VERSION "ConnectivityCANFD"

NS_ :

BS_ :

BU_ :  ETC IHU TCAM

BO_ 880 DhuConnCANFDFr07 : 64 IHU
 SG_ BookChrgnTarValFb : 7|10@0+ (0.1,0.0) [0.0|100.0] "%" TCAM
 SG_ BookChrgnTarValFb_UB : 13|1@0+ (1,0) [0|1] "" TCAM
 SG_ BookTrvlHeatgStsFb : 23|3@0+ (1,0) [0|7] "" TCAM
 SG_ BookTrvlHeatgStsFb_UB : 20|1@0+ (1,0) [0|1] "" TCAM
 SG_ BookTrvlPreHeatgFb : 9|2@0+ (1,0) [0|3] "" TCAM
 SG_ BookTrvlPreHeatgFb_UB : 10|1@0+ (1,0) [0|1] "" TCAM
 SG_ CarLoctrActvnSts : 31|2@0+ (1,0) [0|3] "" TCAM
 SG_ CarLoctrActvnSts_UB : 29|1@0+ (1,0) [0|1] "" TCAM
 SG_ CdsParkgClimaActv : 12|1@0+ (1,0) [0|1] "" TCAM
 SG_ CdsParkgClimaActv_UB : 11|1@0+ (1,0) [0|1] "" TCAM
 SG_ ClimaOvrHeatProActv : 19|1@0+ (1,0) [0|1] "" TCAM
 SG_ ClimaOvrHeatProActv_UB : 18|1@0+ (1,0) [0|1] "" TCAM
 SG_ ClimaOvrHeatProActvSts : 17|1@0+ (1,0) [0|1] "" TCAM
 SG_ ClimaOvrHeatProActvSts_UB : 16|1@0+ (1,0) [0|1] "" TCAM
 SG_ CmptmtRelHum : 47|8@0+ (0.5,0.0) [0.0|100.0] "%" TCAM
 SG_ CmptmtRelHum_UB : 55|1@0+ (1,0) [0|1] "" TCAM
 SG_ DchaChrgnTarValFb : 25|10@0+ (0.1,0.0) [0.0|100.0] "%" TCAM
 SG_ DchaChrgnTarValFb_UB : 26|1@0+ (1,0) [0|1] "" TCAM
 SG_ DigKeyLogUploadSwt : 88|1@0+ (1,0) [0|1] "" TCAM
 SG_ DigKeyLogUploadSwt_UB : 56|1@0+ (1,0) [0|1] "" TCAM
 SG_ DrvrSeatHeatgAvlSts : 51|3@0+ (1,0) [0|7] "" TCAM
 SG_ DrvrSeatHeatgAvlSts_UB : 48|1@0+ (1,0) [0|1] "" TCAM
 SG_ DrvrSeatHeatgLvlSts : 53|2@0+ (1,0) [0|3] "" TCAM
 SG_ DrvrSeatHeatgLvlSts_UB : 54|1@0+ (1,0) [0|1] "" TCAM
 SG_ DrvrSeatVentAvlSts : 63|3@0+ (1,0) [0|7] "" TCAM
 SG_ DrvrSeatVentAvlSts_UB : 60|1@0+ (1,0) [0|1] "" TCAM
 SG_ DrvrSeatVentnLvlSts : 59|2@0+ (1,0) [0|3] "" TCAM
 SG_ DrvrSeatVentnLvlSts_UB : 57|1@0+ (1,0) [0|1] "" TCAM
 SG_ EngN2 : 71|15@0+ (0.5,0.0) [0.0|16383.5] "rpm" TCAM
 SG_ EngN2_UB : 72|1@0+ (1,0) [0|1] "" TCAM
 SG_ FragCh1Id : 87|8@0+ (1.0,0.0) [0.0|255.0] "Unitless" TCAM
 SG_ FragCh1Id_UB : 95|1@0+ (1,0) [0|1] "" TCAM
 SG_ FragCh1UseUpWrn : 90|1@0+ (1,0) [0|1] "" TCAM
 SG_ FragCh1UseUpWrn_UB : 89|1@0+ (1,0) [0|1] "" TCAM
 SG_ FragCh2Id : 103|8@0+ (1.0,0.0) [0.0|255.0] "Unitless" TCAM
 SG_ FragCh2Id_UB : 94|1@0+ (1,0) [0|1] "" TCAM
 SG_ FragCh2UseUpWrn : 135|1@0+ (1,0) [0|1] "" TCAM
 SG_ FragCh2UseUpWrn_UB : 134|1@0+ (1,0) [0|1] "" TCAM
 SG_ FragCh3Id : 111|8@0+ (1.0,0.0) [0.0|255.0] "Unitless" TCAM
 SG_ FragCh3Id_UB : 93|1@0+ (1,0) [0|1] "" TCAM
 SG_ FragCh3UseUpWrn : 133|1@0+ (1,0) [0|1] "" TCAM
 SG_ FragCh3UseUpWrn_UB : 132|1@0+ (1,0) [0|1] "" TCAM
 SG_ FragCh4Id : 119|8@0+ (1.0,0.0) [0.0|255.0] "Unitless" TCAM
 SG_ FragCh4Id_UB : 92|1@0+ (1,0) [0|1] "" TCAM
 SG_ FragCh4UseUpWrn : 131|1@0+ (1,0) [0|1] "" TCAM
 SG_ FragCh4UseUpWrn_UB : 130|1@0+ (1,0) [0|1] "" TCAM
 SG_ FragCh5Id : 127|8@0+ (1.0,0.0) [0.0|255.0] "Unitless" TCAM
 SG_ FragCh5Id_UB : 91|1@0+ (1,0) [0|1] "" TCAM
 SG_ FragCh5UseUpWrn : 129|1@0+ (1,0) [0|1] "" TCAM
 SG_ FragCh5UseUpWrn_UB : 128|1@0+ (1,0) [0|1] "" TCAM
 SG_ FragLvlFrmClima : 143|2@0+ (1,0) [0|3] "" TCAM
 SG_ FragLvlFrmClima_UB : 151|1@0+ (1,0) [0|1] "" TCAM
 SG_ FragStsFrmClima : 141|2@0+ (1,0) [0|3] "" TCAM
 SG_ FragStsFrmClima_UB : 150|1@0+ (1,0) [0|1] "" TCAM
 SG_ HmiCarLocatorSetReq : 307|1@0+ (1,0) [0|1] "" TCAM
 SG_ HmiCarLocatorSetReq_UB : 306|1@0+ (1,0) [0|1] "" TCAM
 SG_ HvCellTDifFlt : 139|2@0+ (1,0) [0|3] "" TCAM
 SG_ HvCellTDifFlt_UB : 149|1@0+ (1,0) [0|1] "" TCAM
 SG_ HvCellUDifFlt : 137|2@0+ (1,0) [0|3] "" TCAM
 SG_ HvCellUDifFlt_UB : 148|1@0+ (1,0) [0|1] "" TCAM
 SG_ HvCellUOverFlt : 159|2@0+ (1,0) [0|3] "" TCAM
 SG_ HvCellUOverFlt_UB : 147|1@0+ (1,0) [0|1] "" TCAM
 SG_ HvCellUUnderFlt : 157|2@0+ (1,0) [0|3] "" TCAM
 SG_ HvCellUUnderFlt_UB : 146|1@0+ (1,0) [0|1] "" TCAM
 SG_ HvilFlt : 144|1@0+ (1,0) [0|1] "" TCAM
 SG_ HvilFlt_UB : 145|1@0+ (1,0) [0|1] "" TCAM
 SG_ HvIsoFlt : 167|2@0+ (1,0) [0|3] "" TCAM
 SG_ HvIsoFlt_UB : 175|1@0+ (1,0) [0|1] "" TCAM
 SG_ HvPackOverChrgFlt : 165|2@0+ (1,0) [0|3] "" TCAM
 SG_ HvPackOverChrgFlt_UB : 174|1@0+ (1,0) [0|1] "" TCAM
 SG_ HvPackUOverFlt : 163|2@0+ (1,0) [0|3] "" TCAM
 SG_ HvPackUOverFlt_UB : 173|1@0+ (1,0) [0|1] "" TCAM
 SG_ HvPackUUnderFlt : 161|2@0+ (1,0) [0|3] "" TCAM
 SG_ HvPackUUnderFlt_UB : 172|1@0+ (1,0) [0|1] "" TCAM
 SG_ HvSocHiFlt : 183|2@0+ (1,0) [0|3] "" TCAM
 SG_ HvSocHiFlt_UB : 171|1@0+ (1,0) [0|1] "" TCAM
 SG_ HvSocHopFlt : 181|2@0+ (1,0) [0|3] "" TCAM
 SG_ HvSocHopFlt_UB : 170|1@0+ (1,0) [0|1] "" TCAM
 SG_ HvSocLoFlt : 179|2@0+ (1,0) [0|3] "" TCAM
 SG_ HvSocLoFlt_UB : 169|1@0+ (1,0) [0|1] "" TCAM
 SG_ IntPm25StsFrmClima : 177|2@0+ (1,0) [0|3] "" TCAM
 SG_ IntPm25StsFrmClima_UB : 168|1@0+ (1,0) [0|1] "" TCAM
 SG_ KeyIntrVldDetd : 154|1@0+ (1,0) [0|1] "" TCAM
 SG_ KeyIntrVldDetd_UB : 155|1@0+ (1,0) [0|1] "" TCAM
 SG_ LiBattInPWLockTC : 298|1@0+ (1,0) [0|1] "" TCAM
 SG_ LiBattInPWLockTC_UB : 297|1@0+ (1,0) [0|1] "" TCAM
 SG_ OutdPm25LvlFrmClima : 207|3@0+ (1,0) [0|7] "" TCAM
 SG_ OutdPm25LvlFrmClima_UB : 204|1@0+ (1,0) [0|1] "" TCAM
 SG_ OutdPm25VluFrmClima : 191|10@0+ (1.0,0.0) [0.0|1023.0] "Unitless" TCAM
 SG_ OutdPm25VluFrmClima_UB : 197|1@0+ (1,0) [0|1] "" TCAM
 SG_ PassSeatHeatgAvlSts : 203|3@0+ (1,0) [0|7] "" TCAM
 SG_ PassSeatHeatgAvlSts_UB : 200|1@0+ (1,0) [0|1] "" TCAM
 SG_ PassSeatHeatgLvlSts : 215|2@0+ (1,0) [0|3] "" TCAM
 SG_ PassSeatHeatgLvlSts_UB : 223|1@0+ (1,0) [0|1] "" TCAM
 SG_ PassSeatVentAvlSts : 211|3@0+ (1,0) [0|7] "" TCAM
 SG_ PassSeatVentAvlSts_UB : 208|1@0+ (1,0) [0|1] "" TCAM
 SG_ PassSeatVentnLvlSts : 213|2@0+ (1,0) [0|3] "" TCAM
 SG_ PassSeatVentnLvlSts_UB : 222|1@0+ (1,0) [0|1] "" TCAM
 SG_ PrkgClimaWarn : 195|4@0+ (1,0) [0|15] "" TCAM
 SG_ PrkgClimaWarn_UB : 196|1@0+ (1,0) [0|1] "" TCAM
 SG_ RelHumSnsrRelHum : 231|8@0+ (0.5,0.0) [0.0|100.0] "%" TCAM
 SG_ RelHumSnsrRelHum_UB : 221|1@0+ (1,0) [0|1] "" TCAM
 SG_ RemClimaActv : 239|1@0+ (1,0) [0|1] "" TCAM
 SG_ RemClimaActv_UB : 238|1@0+ (1,0) [0|1] "" TCAM
 SG_ RemClimaDefrstSts : 237|1@0+ (1,0) [0|1] "" TCAM
 SG_ RemClimaDefrstSts_UB : 236|1@0+ (1,0) [0|1] "" TCAM
 SG_ RemClimaDelaySts : 235|1@0+ (1,0) [0|1] "" TCAM
 SG_ RemClimaDelaySts_UB : 234|1@0+ (1,0) [0|1] "" TCAM
 SG_ RemClimaExtnTiRspn : 233|1@0+ (1,0) [0|1] "" TCAM
 SG_ RemClimaExtnTiRspn_UB : 232|1@0+ (1,0) [0|1] "" TCAM
 SG_ RemClimaHvRspn : 247|1@0+ (1,0) [0|1] "" TCAM
 SG_ RemClimaHvRspn_UB : 246|1@0+ (1,0) [0|1] "" TCAM
 SG_ RemClimaHvSts : 245|1@0+ (1,0) [0|1] "" TCAM
 SG_ RemClimaHvSts_UB : 244|1@0+ (1,0) [0|1] "" TCAM
 SG_ RemClimaWarn : 219|4@0+ (1,0) [0|15] "" TCAM
 SG_ RemClimaWarn_UB : 220|1@0+ (1,0) [0|1] "" TCAM
 SG_ RemStrtClimaRspn : 251|1@0+ (1,0) [0|1] "" TCAM
 SG_ RemStrtClimaRspn_UB : 250|1@0+ (1,0) [0|1] "" TCAM
 SG_ RemVentActvSts : 243|1@0+ (1,0) [0|1] "" TCAM
 SG_ RemVentActvSts_UB : 242|1@0+ (1,0) [0|1] "" TCAM
 SG_ RemVentReqRspnFb : 241|1@0+ (1,0) [0|1] "" TCAM
 SG_ RemVentReqRspnFb_UB : 240|1@0+ (1,0) [0|1] "" TCAM
 SG_ RemVentWarnSts : 255|2@0+ (1,0) [0|3] "" TCAM
 SG_ RemVentWarnSts_UB : 253|1@0+ (1,0) [0|1] "" TCAM
 SG_ SteerWhlHeatgAvlSts : 271|3@0+ (1,0) [0|7] "" TCAM
 SG_ SteerWhlHeatgAvlSts_UB : 268|1@0+ (1,0) [0|1] "" TCAM
 SG_ SunCurtImpctDetnSts2 : 263|3@0+ (1,0) [0|7] "" TCAM
 SG_ SunCurtImpctDetnSts2_UB : 249|1@0+ (1,0) [0|1] "" TCAM
 SG_ SunCurtMvngSts : 311|1@0+ (1,0) [0|1] "" Vector__XXX
 SG_ SunCurtMvngSts_UB : 310|1@0+ (1,0) [0|1] "" Vector__XXX
 SG_ SunCurtPosnSts : 260|5@0+ (1,0) [0|31] "" TCAM
 SG_ SunCurtPosnSts_UB : 248|1@0+ (1,0) [0|1] "" TCAM
 SG_ SunRoofAndCurtFailr_UB : 252|1@0+ (1,0) [0|1] "" TCAM
 SG_ SunRoofAndCurtFailrCurtMotFailr : 279|1@0+ (1,0) [0|1] "" TCAM
 SG_ SunRoofAndCurtFailrCurtMotHallFailr : 278|1@0+ (1,0) [0|1] "" TCAM
 SG_ SunRoofAndCurtFailrCurtMotNotAvl : 277|1@0+ (1,0) [0|1] "" TCAM
 SG_ SunRoofAndCurtFailrEcuFailrGen : 276|1@0+ (1,0) [0|1] "" TCAM
 SG_ SunRoofAndCurtFailrPanMotFailr : 275|1@0+ (1,0) [0|1] "" TCAM
 SG_ SunRoofAndCurtFailrPanMotHallFailr : 274|1@0+ (1,0) [0|1] "" TCAM
 SG_ SunRoofAndCurtFailrPanMotNotAvl : 273|1@0+ (1,0) [0|1] "" TCAM
 SG_ SunRoofAndCurtFailrResvd : 272|1@0+ (1,0) [0|1] "" TCAM
 SG_ SunRoofMvngSts : 309|1@0+ (1,0) [0|1] "" Vector__XXX
 SG_ SunRoofMvngSts_UB : 308|1@0+ (1,0) [0|1] "" Vector__XXX
 SG_ TankFlapSts : 301|2@0+ (1,0) [0|3] "" TCAM
 SG_ TankFlapSts_UB : 299|1@0+ (1,0) [0|1] "" TCAM
 SG_ WhlMotSysInvrT : 287|8@0+ (1.0,-50.0) [-50.0|200.0] "degC" TCAM
 SG_ WhlMotSysInvrT_UB : 303|1@0+ (1,0) [0|1] "" TCAM
 SG_ WhlMotSysMotT : 295|8@0+ (1.0,-50.0) [-50.0|200.0] "degC" TCAM
 SG_ WhlMotSysMotT_UB : 302|1@0+ (1,0) [0|1] "" TCAM
 SG_ WinFailrStsAtPass : 267|1@0+ (1,0) [0|1] "" TCAM
 SG_ WinFailrStsAtPass_UB : 266|1@0+ (1,0) [0|1] "" TCAM
 SG_ WinFailrStsAtReRi : 265|1@0+ (1,0) [0|1] "" TCAM
 SG_ WinFailrStsAtReRi_UB : 264|1@0+ (1,0) [0|1] "" TCAM

BO_ 672 DhuConnCANFDFr08 : 64 IHU
 SG_ ClimaOvrHeatProRspn : 4|1@0+ (1,0) [0|1] "" TCAM
 SG_ ClimaOvrHeatProRspn_UB : 3|1@0+ (1,0) [0|1] "" TCAM
 SG_ ClimaOvrHeatProWarn : 7|2@0+ (1,0) [0|3] "" TCAM
 SG_ ClimaOvrHeatProWarn_UB : 5|1@0+ (1,0) [0|1] "" TCAM
 SG_ ClsdDueToRain : 15|1@0+ (1,0) [0|1] "" TCAM
 SG_ ClsdDueToRain_UB : 14|1@0+ (1,0) [0|1] "" TCAM
 SG_ SchedCmptHeatCoolFB : 2|2@0+ (1,0) [0|3] "" TCAM
 SG_ SchedCmptHeatCoolFB_UB : 0|1@0+ (1,0) [0|1] "" TCAM
 SG_ VehCfgPrm_UB : 13|1@0+ (1,0) [0|1] "" TCAM
 SG_ VehCfgPrmBlkIDBytePosn1 : 23|8@0+ (1.0,0.0) [0.0|255.0] "Unitless" TCAM
 SG_ VehCfgPrmCCPBytePosn2 : 31|8@0+ (1.0,0.0) [0.0|255.0] "Unitless" TCAM
 SG_ VehCfgPrmCCPBytePosn3 : 39|8@0+ (1.0,0.0) [0.0|255.0] "Unitless" TCAM
 SG_ VehCfgPrmCCPBytePosn4 : 47|8@0+ (1.0,0.0) [0.0|255.0] "Unitless" TCAM
 SG_ VehCfgPrmCCPBytePosn5 : 55|8@0+ (1.0,0.0) [0.0|255.0] "Unitless" TCAM
 SG_ VehCfgPrmCCPBytePosn6 : 63|8@0+ (1.0,0.0) [0.0|255.0] "Unitless" TCAM
 SG_ VehCfgPrmCCPBytePosn7 : 71|8@0+ (1.0,0.0) [0.0|255.0] "Unitless" TCAM
 SG_ VehCfgPrmCCPBytePosn8 : 79|8@0+ (1.0,0.0) [0.0|255.0] "Unitless" TCAM
 SG_ VehCfgPrmExt_UB : 12|1@0+ (1,0) [0|1] "" TCAM
 SG_ VehCfgPrmExtBlkIDBytePosn1 : 87|8@0+ (1.0,0.0) [0.0|255.0] "Unitless" TCAM
 SG_ VehCfgPrmExtCCPBytePosn2 : 95|8@0+ (1.0,0.0) [0.0|255.0] "Unitless" TCAM
 SG_ VehCfgPrmExtCCPBytePosn3 : 103|8@0+ (1.0,0.0) [0.0|255.0] "Unitless" TCAM
 SG_ VehCfgPrmExtCCPBytePosn4 : 111|8@0+ (1.0,0.0) [0.0|255.0] "Unitless" TCAM
 SG_ VehCfgPrmExtCCPBytePosn5 : 119|8@0+ (1.0,0.0) [0.0|255.0] "Unitless" TCAM
 SG_ VehCfgPrmExtCCPBytePosn6 : 127|8@0+ (1.0,0.0) [0.0|255.0] "Unitless" TCAM
 SG_ VehCfgPrmExtCCPBytePosn7 : 135|8@0+ (1.0,0.0) [0.0|255.0] "Unitless" TCAM
 SG_ VehCfgPrmExtCCPBytePosn8 : 143|8@0+ (1.0,0.0) [0.0|255.0] "Unitless" TCAM
 SG_ Vin_UB : 11|1@0+ (1,0) [0|1] "" TCAM
 SG_ VinBlockNr : 151|8@0+ (1.0,0.0) [0.0|255.0] "Unitless" TCAM
 SG_ VinVINSignalPos1 : 159|8@0+ (1.0,0.0) [0.0|255.0] "Unitless" TCAM
 SG_ VinVINSignalPos2 : 167|8@0+ (1.0,0.0) [0.0|255.0] "Unitless" TCAM
 SG_ VinVINSignalPos3 : 175|8@0+ (1.0,0.0) [0.0|255.0] "Unitless" TCAM
 SG_ VinVINSignalPos4 : 183|8@0+ (1.0,0.0) [0.0|255.0] "Unitless" TCAM
 SG_ VinVINSignalPos5 : 191|8@0+ (1.0,0.0) [0.0|255.0] "Unitless" TCAM
 SG_ VinVINSignalPos6 : 199|8@0+ (1.0,0.0) [0.0|255.0] "Unitless" TCAM
 SG_ VinVINSignalPos7 : 207|8@0+ (1.0,0.0) [0.0|255.0] "Unitless" TCAM

BO_ 1008 DhuConnCANFDFr09 : 64 IHU
 SG_ LocalBookChrgnTarVal : 15|10@0+ (0.1,0.0) [0.0|100.0] "%" TCAM
 SG_ LocalBookChrgnTarVal_UB : 21|1@0+ (1,0) [0|1] "" TCAM
 SG_ MaxAcInpCurrentSet : 7|8@0+ (1.0,0.0) [0.0|255.0] "Unitless" TCAM
 SG_ MaxAcInpCurrentSet_UB : 20|1@0+ (1,0) [0|1] "" TCAM

BO_ 48 DhuConnCANFDFr10 : 64 IHU
 SG_ CarTiGlb : 7|32@0+ (0.1,0.0) [0.0|429496729.5] "s" TCAM
 SG_ CarTiGlb_UB : 39|1@0+ (1,0) [0|1] "" TCAM
 SG_ DoorDrvrLockSts : 47|2@0+ (1,0) [0|3] "" TCAM
 SG_ DoorDrvrLockSts_UB : 38|1@0+ (1,0) [0|1] "" TCAM
 SG_ DoorDrvrSts : 117|2@0+ (1,0) [0|3] "" TCAM
 SG_ DoorDrvrSts_UB : 115|1@0+ (1,0) [0|1] "" TCAM
 SG_ DoorLeReLockSts : 45|2@0+ (1,0) [0|3] "" TCAM
 SG_ DoorLeReLockSts_UB : 37|1@0+ (1,0) [0|1] "" TCAM
 SG_ DoorLeReSts : 113|2@0+ (1,0) [0|3] "" TCAM
 SG_ DoorLeReSts_UB : 114|1@0+ (1,0) [0|1] "" TCAM
 SG_ DoorPassLockSts : 43|2@0+ (1,0) [0|3] "" TCAM
 SG_ DoorPassLockSts_UB : 36|1@0+ (1,0) [0|1] "" TCAM
 SG_ DoorPassSts : 127|2@0+ (1,0) [0|3] "" TCAM
 SG_ DoorPassSts_UB : 125|1@0+ (1,0) [0|1] "" TCAM
 SG_ DoorRiReLockSts : 41|2@0+ (1,0) [0|3] "" TCAM
 SG_ DoorRiReLockSts_UB : 35|1@0+ (1,0) [0|1] "" TCAM
 SG_ DoorRiReSts : 123|2@0+ (1,0) [0|3] "" TCAM
 SG_ DoorRiReSts_UB : 124|1@0+ (1,0) [0|1] "" TCAM
 SG_ LockgCenSts_UB : 48|1@0+ (1,0) [0|1] "" TCAM
 SG_ LockgCenStsLockSt : 51|2@0+ (1,0) [0|3] "" TCAM
 SG_ LockgCenStsTrigSrc : 55|4@0+ (1,0) [0|15] "" TCAM
 SG_ LockgCenStsUpdEve : 49|1@0+ (1,0) [0|1] "" TCAM
 SG_ RecOfImpct_UB : 89|1@0+ (1,0) [0|1] "" TCAM
 SG_ RecOfImpct2_UB : 118|1@0+ (1,0) [0|1] "" TCAM
 SG_ RecOfImpct2ImpctDvxSigned : 88|9@0+ (1.0,-255.0) [-255.0|257.0] "Km/h" TCAM
 SG_ RecOfImpct2ImpctDvySigned : 111|9@0+ (1.0,-255.0) [-255.0|257.0] "Km/h" TCAM
 SG_ RecOfImpctCrashFrnt : 72|1@0+ (1,0) [0|1] "" TCAM
 SG_ RecOfImpctCrashOffroadA : 90|1@0+ (1,0) [0|1] "" TCAM
 SG_ RecOfImpctCrashOffroadD : 91|1@0+ (1,0) [0|1] "" TCAM
 SG_ RecOfImpctCrashOffroadRT : 92|1@0+ (1,0) [0|1] "" TCAM
 SG_ RecOfImpctCrashOffroadRTsevere : 93|1@0+ (1,0) [0|1] "" TCAM
 SG_ RecOfImpctCrashPed : 94|1@0+ (1,0) [0|1] "" TCAM
 SG_ RecOfImpctCrashRe : 95|1@0+ (1,0) [0|1] "" TCAM
 SG_ RecOfImpctCrashRollovr : 80|1@0+ (1,0) [0|1] "" TCAM
 SG_ RecOfImpctCrashSideLe : 81|1@0+ (1,0) [0|1] "" TCAM
 SG_ RecOfImpctCrashSideRi : 82|1@0+ (1,0) [0|1] "" TCAM
 SG_ RecOfImpctCrashState : 84|2@0+ (1,0) [0|3] "" TCAM
 SG_ RecOfImpctImpctDvx : 63|8@0+ (1.0,0.0) [0.0|255.0] "Km/h" TCAM
 SG_ RecOfImpctImpctDvy : 71|8@0+ (1.0,0.0) [0.0|255.0] "Km/h" TCAM
 SG_ RecOfImpctImpctRollAg : 79|7@0+ (15.0,0.0) [0.0|1905.0] "Deg" TCAM
 SG_ RecOfImpctVehOri : 87|3@0+ (1,0) [0|7] "" TCAM
 SG_ TrLockSts : 33|2@0+ (1,0) [0|3] "" TCAM
 SG_ TrLockSts_UB : 34|1@0+ (1,0) [0|1] "" TCAM
 SG_ TrSts : 121|2@0+ (1,0) [0|3] "" TCAM
 SG_ TrSts_UB : 135|1@0+ (1,0) [0|1] "" TCAM

BO_ 944 DhuConnCANFDFr11 : 64 IHU
 SG_ AccrPedlPsd_UB : 9|1@0+ (1,0) [0|1] "" TCAM
 SG_ AccrPedlPsdAccrPedlPsd : 11|1@0+ (1,0) [0|1] "" TCAM
 SG_ AccrPedlPsdChks : 7|8@0+ (1.0,0.0) [0.0|255.0] "Unitless" TCAM
 SG_ AccrPedlPsdCntr : 15|4@0+ (1.0,0.0) [0.0|15.0] "Unitless" TCAM
 SG_ AccrPedlPsdSts : 10|1@0+ (1,0) [0|1] "" TCAM
 SG_ AjarChrgLidRearSwitch : 45|2@0+ (1,0) [0|3] "" TCAM
 SG_ AjarChrgLidRearSwitch_UB : 43|1@0+ (1,0) [0|1] "" TCAM
 SG_ DCChrgSt : 63|4@0+ (1,0) [0|15] "" TCAM
 SG_ DCChrgSt_UB : 59|1@0+ (1,0) [0|1] "" TCAM
 SG_ EscWarnIndcnReq_UB : 25|1@0+ (1,0) [0|1] "" TCAM
 SG_ EscWarnIndcnReqChks : 23|8@0+ (1.0,0.0) [0.0|255.0] "Unitless" TCAM
 SG_ EscWarnIndcnReqCntr : 31|4@0+ (1.0,0.0) [0.0|15.0] "Unitless" TCAM
 SG_ EscWarnIndcnReqEscWarnIndcnReq : 27|2@0+ (1,0) [0|3] "" TCAM
 SG_ GearIndcnRec_UB : 24|1@0+ (1,0) [0|1] "" TCAM
 SG_ GearIndcnRecGearIndcn : 39|4@0+ (1,0) [0|15] "" TCAM
 SG_ GearIndcnRecGearShiftIndcn : 47|2@0+ (1,0) [0|3] "" TCAM
 SG_ GearIndcnRecGearTarIndcn : 35|4@0+ (1,0) [0|15] "" TCAM
 SG_ HvBattChrgnTiEstimd : 42|11@0+ (1.0,0.0) [0.0|2047.0] "Mins" TCAM
 SG_ HvBattChrgnTiEstimd_UB : 8|1@0+ (1,0) [0|1] "" TCAM
 SG_ HvIsoR : 71|16@0+ (1.0,0.0) [0.0|60000.0] "kOhm" TCAM
 SG_ HvIsoR_UB : 58|1@0+ (1,0) [0|1] "" TCAM
 SG_ IemGeneric_UB : 151|1@0+ (1,0) [0|1] "" TCAM
 SG_ IemGenericADAlrmSt : 127|2@0+ (1,0) [0|3] "" TCAM
 SG_ IemGenericDTCHig : 87|8@0+ (1.0,0.0) [0.0|255.0] "Unitless" TCAM
 SG_ IemGenericDTCLow : 95|8@0+ (1.0,0.0) [0.0|255.0] "Unitless" TCAM
 SG_ IemGenericDTCMid : 103|8@0+ (1.0,0.0) [0.0|255.0] "Unitless" TCAM
 SG_ IemGenericDTCSts : 111|8@0+ (1.0,0.0) [0.0|255.0] "Unitless" TCAM
 SG_ IemGenericEMQnty : 119|4@0+ (1.0,0.0) [0.0|15.0] "Unitless" TCAM
 SG_ IemGenericEMSeqNr : 115|4@0+ (1.0,0.0) [0.0|15.0] "Unitless" TCAM
 SG_ IemGenericFltAlrmSt : 125|2@0+ (1,0) [0|3] "" TCAM
 SG_ IemGenericIacAlrmSt : 123|2@0+ (1,0) [0|3] "" TCAM
 SG_ IemGenericInvrtTAlrmSt : 121|2@0+ (1,0) [0|3] "" TCAM
 SG_ IemGenericModStatusRms : 135|4@0+ (1,0) [0|15] "" TCAM
 SG_ IemGenericMotTAlrmSt : 131|2@0+ (1,0) [0|3] "" TCAM
 SG_ IemGenericRslAlrmSt : 129|2@0+ (1,0) [0|3] "" TCAM
 SG_ IemGenericSpdAlrmSt : 143|2@0+ (1,0) [0|3] "" TCAM
 SG_ IemGenericTypeInfo : 139|4@0+ (1.0,0.0) [0.0|15.0] "Unitless" TCAM
 SG_ IemGenericUDcAlrmSt : 141|2@0+ (1,0) [0|3] "" TCAM
 SG_ IntPm25LvlFrmClima : 150|3@0+ (1,0) [0|7] "" TCAM
 SG_ IntPm25LvlFrmClima_UB : 147|1@0+ (1,0) [0|1] "" TCAM
 SG_ IntPm25VluFrmClima : 145|10@0+ (1.0,0.0) [0.0|1023.0] "Unitless" TCAM
 SG_ IntPm25VluFrmClima_UB : 146|1@0+ (1,0) [0|1] "" TCAM
 SG_ OnBdChrgrHndlSts1 : 199|4@0+ (1,0) [0|15] "" TCAM
 SG_ OnBdChrgrHndlSts1_UB : 191|1@0+ (1,0) [0|1] "" TCAM
 SG_ OnBdChrgrIAct : 167|12@0+ (0.1,-200.0) [-200.0|200.0] "A" TCAM
 SG_ OnBdChrgrIAct_UB : 171|1@0+ (1,0) [0|1] "" TCAM
 SG_ OnBdChrgrPwrEnaAllwd : 189|1@0+ (1,0) [0|1] "" TCAM
 SG_ OnBdChrgrPwrEnaAllwd_UB : 188|1@0+ (1,0) [0|1] "" TCAM
 SG_ OnBdChrgrSt : 195|4@0+ (1,0) [0|15] "" TCAM
 SG_ OnBdChrgrSt_UB : 190|1@0+ (1,0) [0|1] "" TCAM
 SG_ OnBdChrgrUAct : 170|11@0+ (0.25,0.0) [0.0|511.0] "Volt" TCAM
 SG_ OnBdChrgrUAct_UB : 185|1@0+ (1,0) [0|1] "" TCAM
 SG_ RemAllowStrt : 57|1@0+ (1,0) [0|1] "" TCAM
 SG_ RemAllowStrt_UB : 56|1@0+ (1,0) [0|1] "" TCAM
 SG_ WirelschrgActvReqFromHmi : 187|1@0+ (1,0) [0|1] "" TCAM
 SG_ WirelschrgActvReqFromHmi_UB : 186|1@0+ (1,0) [0|1] "" TCAM

BO_ 832 DhuConnCANFDFr12 : 64 IHU
 SG_ BookChargeSetResponse : 7|2@0+ (1,0) [0|3] "" TCAM
 SG_ BookChargeSetResponse_UB : 5|1@0+ (1,0) [0|1] "" TCAM
 SG_ BrkAndAbsWarnIndcnReq_UB : 111|1@0+ (1,0) [0|1] "" TCAM
 SG_ BrkAndAbsWarnIndcnReqAbsWarnIndcnReq : 109|2@0+ (1,0) [0|3] "" TCAM
 SG_ BrkAndAbsWarnIndcnReqBrkWarnIndcnReq : 110|1@0+ (1,0) [0|1] "" TCAM
 SG_ BrkAndAbsWarnIndcnReqChks : 119|8@0+ (1.0,0.0) [0.0|255.0] "Unitless" TCAM
 SG_ BrkAndAbsWarnIndcnReqCntr : 107|4@0+ (1.0,0.0) [0.0|15.0] "Unitless" TCAM
 SG_ DispOfPrpsnMod : 3|4@0+ (1,0) [0|15] "" TCAM
 SG_ DispOfPrpsnMod_UB : 4|1@0+ (1,0) [0|1] "" TCAM
 SG_ EngForbidRespFromVMM : 47|1@0+ (1,0) [0|1] "" TCAM
 SG_ EngForbidRespFromVMM_UB : 46|1@0+ (1,0) [0|1] "" TCAM
 SG_ NetDHUActvt : 63|8@0+ (1.0,0.0) [0.0|255.0] "Unitless" TCAM
 SG_ NetDHUActvt_UB : 42|1@0+ (1,0) [0|1] "" TCAM
 SG_ NotifForEmgyCall : 45|1@0+ (1,0) [0|1] "" TCAM
 SG_ NotifForEmgyCall_UB : 44|1@0+ (1,0) [0|1] "" TCAM
 SG_ PassSeatSnsrSts2 : 71|2@0+ (1,0) [0|3] "" TCAM
 SG_ PassSeatSnsrSts2_UB : 41|1@0+ (1,0) [0|1] "" TCAM
 SG_ PassSeatSts2 : 69|2@0+ (1,0) [0|3] "" TCAM
 SG_ PassSeatSts2_UB : 40|1@0+ (1,0) [0|1] "" TCAM
 SG_ TCSDoorNoClsSts : 103|1@0+ (1,0) [0|1] "" TCAM
 SG_ TCSDoorNoClsSts_UB : 102|1@0+ (1,0) [0|1] "" TCAM
 SG_ TrOpenerByFootOperCmd : 67|1@0+ (1,0) [0|1] "" TCAM
 SG_ TrOpenerByFootOperCmd_UB : 66|1@0+ (1,0) [0|1] "" TCAM
 SG_ TrsmParkLockd_UB : 14|1@0+ (1,0) [0|1] "" TCAM
 SG_ TrsmParkLockdChks : 23|8@0+ (1.0,0.0) [0.0|255.0] "Unitless" TCAM
 SG_ TrsmParkLockdCntr : 11|4@0+ (1.0,0.0) [0.0|15.0] "Unitless" TCAM
 SG_ TrsmParkLockdTrsmParkLockd : 13|2@0+ (1,0) [0|3] "" TCAM
 SG_ VehMtnSt_UB : 31|1@0+ (1,0) [0|1] "" TCAM
 SG_ VehMtnStChks : 39|8@0+ (1.0,0.0) [0.0|255.0] "Unitless" TCAM
 SG_ VehMtnStCntr : 30|4@0+ (1.0,0.0) [0.0|15.0] "Unitless" TCAM
 SG_ VehMtnStVehMtnSt : 26|3@0+ (1,0) [0|7] "" TCAM
 SG_ WirelsChrgFrntLeSwt : 101|1@0+ (1,0) [0|1] "" TCAM
 SG_ WirelsChrgFrntLeSwt_UB : 100|1@0+ (1,0) [0|1] "" TCAM
 SG_ WirelsChrgFrntRiSwt : 99|1@0+ (1,0) [0|1] "" TCAM
 SG_ WirelsChrgFrntRiSwt_UB : 98|1@0+ (1,0) [0|1] "" TCAM

BO_ 272 DhuConnCANFDFr13 : 64 IHU
 SG_ ClimaActv : 17|1@0+ (1,0) [0|1] "" TCAM
 SG_ ClimaActv_UB : 16|1@0+ (1,0) [0|1] "" TCAM
 SG_ HoodSts : 25|2@0+ (1,0) [0|3] "" TCAM
 SG_ HoodSts_UB : 33|1@0+ (1,0) [0|1] "" TCAM
 SG_ SunRoofPosnSts : 15|5@0+ (1,0) [0|31] "" TCAM
 SG_ SunRoofPosnSts_UB : 10|1@0+ (1,0) [0|1] "" TCAM
 SG_ WinPosnStsAtDrvr : 23|5@0+ (1,0) [0|31] "" TCAM
 SG_ WinPosnStsAtDrvr_UB : 18|1@0+ (1,0) [0|1] "" TCAM
 SG_ WinPosnStsAtPass : 31|5@0+ (1,0) [0|31] "" TCAM
 SG_ WinPosnStsAtPass_UB : 26|1@0+ (1,0) [0|1] "" TCAM
 SG_ WinPosnStsAtReLe : 39|5@0+ (1,0) [0|31] "" TCAM
 SG_ WinPosnStsAtReLe_UB : 34|1@0+ (1,0) [0|1] "" TCAM
 SG_ WinPosnStsAtReRi : 47|5@0+ (1,0) [0|31] "" TCAM
 SG_ WinPosnStsAtReRi_UB : 42|1@0+ (1,0) [0|1] "" TCAM

BO_ 800 DhuConnCANFDFr14 : 64 IHU
 SG_ ChrgnByEngStsDurgDcha : 42|3@0+ (1,0) [0|7] "" TCAM
 SG_ ChrgnByEngStsDurgDcha_UB : 43|1@0+ (1,0) [0|1] "" TCAM
 SG_ ChrgnWarn : 9|1@0+ (1,0) [0|1] "" TCAM
 SG_ ChrgnWarn_UB : 8|1@0+ (1,0) [0|1] "" TCAM
 SG_ EgyRegenEgyAct : 7|13@0+ (20.0,0.0) [0.0|163820.0] "Wh" TCAM
 SG_ EgyRegenEgyAct_UB : 10|1@0+ (1,0) [0|1] "" TCAM
 SG_ EngFltIndcn_UB : 44|1@0+ (1,0) [0|1] "" TCAM
 SG_ EngFltIndcn1 : 23|1@0+ (1,0) [0|1] "" TCAM
 SG_ EngFltIndcn10 : 30|1@0+ (1,0) [0|1] "" TCAM
 SG_ EngFltIndcn11 : 29|1@0+ (1,0) [0|1] "" TCAM
 SG_ EngFltIndcn12 : 28|1@0+ (1,0) [0|1] "" TCAM
 SG_ EngFltIndcn13 : 27|1@0+ (1,0) [0|1] "" TCAM
 SG_ EngFltIndcn14 : 26|1@0+ (1,0) [0|1] "" TCAM
 SG_ EngFltIndcn15 : 25|1@0+ (1,0) [0|1] "" TCAM
 SG_ EngFltIndcn16 : 24|1@0+ (1,0) [0|1] "" TCAM
 SG_ EngFltIndcn17 : 39|1@0+ (1,0) [0|1] "" TCAM
 SG_ EngFltIndcn18 : 38|1@0+ (1,0) [0|1] "" TCAM
 SG_ EngFltIndcn19 : 37|1@0+ (1,0) [0|1] "" TCAM
 SG_ EngFltIndcn2 : 22|1@0+ (1,0) [0|1] "" TCAM
 SG_ EngFltIndcn20 : 36|1@0+ (1,0) [0|1] "" TCAM
 SG_ EngFltIndcn21 : 35|1@0+ (1,0) [0|1] "" TCAM
 SG_ EngFltIndcn22 : 34|1@0+ (1,0) [0|1] "" TCAM
 SG_ EngFltIndcn23 : 33|1@0+ (1,0) [0|1] "" TCAM
 SG_ EngFltIndcn24 : 32|1@0+ (1,0) [0|1] "" TCAM
 SG_ EngFltIndcn25 : 47|1@0+ (1,0) [0|1] "" TCAM
 SG_ EngFltIndcn26 : 46|1@0+ (1,0) [0|1] "" TCAM
 SG_ EngFltIndcn27 : 45|1@0+ (1,0) [0|1] "" TCAM
 SG_ EngFltIndcn3 : 21|1@0+ (1,0) [0|1] "" TCAM
 SG_ EngFltIndcn4 : 20|1@0+ (1,0) [0|1] "" TCAM
 SG_ EngFltIndcn5 : 19|1@0+ (1,0) [0|1] "" TCAM
 SG_ EngFltIndcn6 : 18|1@0+ (1,0) [0|1] "" TCAM
 SG_ EngFltIndcn7 : 17|1@0+ (1,0) [0|1] "" TCAM
 SG_ EngFltIndcn8 : 16|1@0+ (1,0) [0|1] "" TCAM
 SG_ EngFltIndcn9 : 31|1@0+ (1,0) [0|1] "" TCAM
 SG_ EngOilLvlSts : 135|3@0+ (1,0) [0|7] "" TCAM
 SG_ EngOilLvlSts_UB : 132|1@0+ (1,0) [0|1] "" TCAM
 SG_ EngOilPWarn : 131|1@0+ (1,0) [0|1] "" TCAM
 SG_ EngOilPWarn_UB : 130|1@0+ (1,0) [0|1] "" TCAM
 SG_ IgmGeneric_UB : 119|1@0+ (1,0) [0|1] "" TCAM
 SG_ IgmGenericADAlrmSt : 103|2@0+ (1,0) [0|3] "" TCAM
 SG_ IgmGenericDTCHig : 55|8@0+ (1.0,0.0) [0.0|255.0] "Unitless" TCAM
 SG_ IgmGenericDTCLow : 63|8@0+ (1.0,0.0) [0.0|255.0] "Unitless" TCAM
 SG_ IgmGenericDTCMid : 71|8@0+ (1.0,0.0) [0.0|255.0] "Unitless" TCAM
 SG_ IgmGenericDTCSts : 79|8@0+ (1.0,0.0) [0.0|255.0] "Unitless" TCAM
 SG_ IgmGenericEMQnty : 87|4@0+ (1.0,0.0) [0.0|15.0] "Unitless" TCAM
 SG_ IgmGenericEMSeqNr : 83|4@0+ (1.0,0.0) [0.0|15.0] "Unitless" TCAM
 SG_ IgmGenericFltAlrmSt : 101|2@0+ (1,0) [0|3] "" TCAM
 SG_ IgmGenericIacAlrmSt : 99|2@0+ (1,0) [0|3] "" TCAM
 SG_ IgmGenericInvrtTAlrmSt : 97|2@0+ (1,0) [0|3] "" TCAM
 SG_ IgmGenericModStatusRms : 95|4@0+ (1,0) [0|15] "" TCAM
 SG_ IgmGenericMotTAlrmSt : 111|2@0+ (1,0) [0|3] "" TCAM
 SG_ IgmGenericRslAlrmSt : 109|2@0+ (1,0) [0|3] "" TCAM
 SG_ IgmGenericSpdAlrmSt : 107|2@0+ (1,0) [0|3] "" TCAM
 SG_ IgmGenericTypeInfo : 91|4@0+ (1.0,0.0) [0.0|15.0] "Unitless" TCAM
 SG_ IgmGenericUDcAlrmSt : 105|2@0+ (1,0) [0|3] "" TCAM
 SG_ IsgIDc : 117|14@0+ (0.1,-818.8) [-818.8|819.2] "A" TCAM
 SG_ IsgIDc_UB : 118|1@0+ (1,0) [0|1] "" TCAM
 SG_ IsgInvrT : 143|8@0+ (1.0,-50.0) [-50.0|200.0] "degC" TCAM
 SG_ IsgInvrT_UB : 129|1@0+ (1,0) [0|1] "" TCAM
 SG_ IsgMotT : 151|8@0+ (1.0,-50.0) [-50.0|200.0] "degC" TCAM
 SG_ IsgMotT_UB : 128|1@0+ (1,0) [0|1] "" TCAM
 SG_ IsgSpdActSgn : 159|15@0- (1.0,0.0) [-16384.0|16383.0] "rpm" TCAM
 SG_ IsgSpdActSgn_UB : 160|1@0+ (1,0) [0|1] "" TCAM
 SG_ LockgCenStsForUsrFb : 175|3@0+ (1,0) [0|7] "" TCAM
 SG_ LockgCenStsForUsrFb_UB : 172|1@0+ (1,0) [0|1] "" TCAM
 SG_ OilMntnAlrmSt : 183|4@0+ (1,0) [0|15] "" TCAM
 SG_ OilMntnAlrmSt_UB : 179|1@0+ (1,0) [0|1] "" TCAM
 SG_ PrpsnModElecDrvBlkd : 171|3@0+ (1,0) [0|7] "" TCAM
 SG_ PrpsnModElecDrvBlkd_UB : 168|1@0+ (1,0) [0|1] "" TCAM

BO_ 968 DhuConnCANFDFr15 : 64 IHU
 SG_ DstTrvldHiResl : 47|8@0+ (1.0,0.0) [0.0|255.0] "m" TCAM
 SG_ DstTrvldHiResl_UB : 29|1@0+ (1,0) [0|1] "" TCAM
 SG_ DstTrvldMst2 : 7|25@0+ (1.0,0.0) [0.0|20000000.0] "Unitless" TCAM
 SG_ DstTrvldMst2_UB : 30|1@0+ (1,0) [0|1] "" TCAM
 SG_ EngHrToSrv : 26|11@0+ (1.0,0.0) [0.0|2000.0] "hours" TCAM
 SG_ EngHrToSrv_UB : 27|1@0+ (1,0) [0|1] "" TCAM
 SG_ EngOilLvl : 55|8@0+ (0.5,0.0) [0.0|120.0] "%" TCAM
 SG_ EngOilLvl_UB : 28|1@0+ (1,0) [0|1] "" TCAM
 SG_ EngT_UB : 69|1@0+ (1,0) [0|1] "" TCAM
 SG_ EngTEngT : 63|8@0+ (1.0,-50.0) [-50.0|200.0] "degC" TCAM
 SG_ EngTQf : 71|2@0+ (1,0) [0|3] "" TCAM
 SG_ EpbSts_UB : 68|1@0+ (1,0) [0|1] "" TCAM
 SG_ EpbStsChks : 79|8@0+ (1.0,0.0) [0.0|255.0] "Unitless" TCAM
 SG_ EpbStsCntr : 87|4@0+ (1.0,0.0) [0.0|15.0] "Unitless" TCAM
 SG_ EpbStsEpbSts : 83|4@0+ (1,0) [0|15] "" TCAM
 SG_ FuCnsAvgIndcd_UB : 127|1@0+ (1,0) [0|1] "" TCAM
 SG_ FuCnsAvgIndcdFuCnsIndcdUnit : 95|3@0+ (1,0) [0|7] "" TCAM
 SG_ FuCnsAvgIndcdFuCnsIndcdVal : 92|13@0+ (0.1,0.0) [0.0|819.1] "Unitless" TCAM
 SG_ FuCnsIndcd_UB : 126|1@0+ (1,0) [0|1] "" TCAM
 SG_ FuCnsIndcdUnit : 111|3@0+ (1,0) [0|7] "" TCAM
 SG_ FuCnsIndcdVal : 108|13@0+ (0.1,0.0) [0.0|819.1] "Unitless" TCAM
 SG_ FuLvlIndcd_UB : 124|1@0+ (1,0) [0|1] "" TCAM
 SG_ FuLvlIndcdFuLvlValFromFuTbl : 121|10@0+ (0.2,0.0) [0.0|204.60000000000002] "Litre" TCAM
 SG_ FuLvlIndcdGenQF : 123|2@0+ (1,0) [0|3] "" TCAM
 SG_ FuLvlLoIndcn : 67|1@0+ (1,0) [0|1] "" TCAM
 SG_ FuLvlLoIndcn_UB : 66|1@0+ (1,0) [0|1] "" TCAM
 SG_ FuLvlLoWarn : 65|1@0+ (1,0) [0|1] "" TCAM
 SG_ FuLvlLoWarn_UB : 64|1@0+ (1,0) [0|1] "" TCAM
 SG_ GidInfoInp1_UB : 223|1@0+ (1,0) [0|1] "" TCAM
 SG_ GidInfoInp1Byte0 : 159|8@0+ (1.0,0.0) [0.0|255.0] "Unitless" TCAM
 SG_ GidInfoInp1Byte1 : 167|8@0+ (1.0,0.0) [0.0|255.0] "Unitless" TCAM
 SG_ GidInfoInp1Byte2 : 175|8@0+ (1.0,0.0) [0.0|255.0] "Unitless" TCAM
 SG_ GidInfoInp1Byte3 : 183|8@0+ (1.0,0.0) [0.0|255.0] "Unitless" TCAM
 SG_ GidInfoInp1Byte4 : 191|8@0+ (1.0,0.0) [0.0|255.0] "Unitless" TCAM
 SG_ GidInfoInp1Byte5 : 199|8@0+ (1.0,0.0) [0.0|255.0] "Unitless" TCAM
 SG_ GidInfoInp1Byte6 : 207|8@0+ (1.0,0.0) [0.0|255.0] "Unitless" TCAM
 SG_ GidInfoInp1Byte7 : 215|8@0+ (1.0,0.0) [0.0|255.0] "Unitless" TCAM
 SG_ GidInfoInp2_UB : 222|1@0+ (1,0) [0|1] "" TCAM
 SG_ GidInfoInp2Byte0 : 231|8@0+ (1.0,0.0) [0.0|255.0] "Unitless" TCAM
 SG_ GidInfoInp2Byte1 : 239|8@0+ (1.0,0.0) [0.0|255.0] "Unitless" TCAM
 SG_ GidInfoInp2Byte2 : 247|8@0+ (1.0,0.0) [0.0|255.0] "Unitless" TCAM
 SG_ GidInfoInp2Byte3 : 255|8@0+ (1.0,0.0) [0.0|255.0] "Unitless" TCAM
 SG_ GidInfoInp2Byte4 : 263|8@0+ (1.0,0.0) [0.0|255.0] "Unitless" TCAM
 SG_ GidInfoInp2Byte5 : 271|8@0+ (1.0,0.0) [0.0|255.0] "Unitless" TCAM
 SG_ GidInfoInp2Byte6 : 279|8@0+ (1.0,0.0) [0.0|255.0] "Unitless" TCAM
 SG_ GidInfoInp2Byte7 : 287|8@0+ (1.0,0.0) [0.0|255.0] "Unitless" TCAM
 SG_ HvBattLimnIndcn : 143|16@0+ (1.0,0.0) [0.0|65535.0] "Unitless" TCAM
 SG_ HvBattLimnIndcn_UB : 125|1@0+ (1,0) [0|1] "" TCAM
 SG_ HvBattSoc : 295|11@0+ (0.05,0.0) [0.0|100.0] "%" TCAM
 SG_ HvBattSoc_UB : 300|1@0+ (1,0) [0|1] "" TCAM
 SG_ HvBattUDc : 298|11@0+ (0.25,0.0) [0.0|511.0] "Volt" TCAM
 SG_ HvBattUDc_UB : 299|1@0+ (1,0) [0|1] "" TCAM
 SG_ HybErrIndcnReq_UB : 220|1@0+ (1,0) [0|1] "" TCAM
 SG_ HybErrIndcnReqTelltlBattTracCutOff : 219|1@0+ (1,0) [0|1] "" TCAM
 SG_ HybErrIndcnReqTelltlBattTracFailr : 218|1@0+ (1,0) [0|1] "" TCAM
 SG_ HybErrIndcnReqTelltlElecDrvFailr : 217|1@0+ (1,0) [0|1] "" TCAM
 SG_ HybErrIndcnReqTelltlSysHybFailr : 216|1@0+ (1,0) [0|1] "" TCAM
 SG_ IndcnUnit_UB : 331|1@0+ (1,0) [0|1] "" TCAM
 SG_ IndcnUnitClkFmt : 319|2@0+ (1,0) [0|3] "" TCAM
 SG_ IndcnUnitDateFmt : 317|2@0+ (1,0) [0|3] "" TCAM
 SG_ IndcnUnitDstLong : 315|2@0+ (1,0) [0|3] "" TCAM
 SG_ IndcnUnitDstSho : 313|2@0+ (1,0) [0|3] "" TCAM
 SG_ IndcnUnitFuCnsUnit : 327|3@0+ (1,0) [0|7] "" TCAM
 SG_ IndcnUnitPUnit : 324|3@0+ (1,0) [0|7] "" TCAM
 SG_ IndcnUnitSpdUnit : 321|2@0+ (1,0) [0|3] "" TCAM
 SG_ IndcnUnitTUnit : 335|2@0+ (1,0) [0|3] "" TCAM
 SG_ IndcnUnitVolUnit : 333|2@0+ (1,0) [0|3] "" TCAM
 SG_ IsgTqAct_UB : 330|1@0+ (1,0) [0|1] "" TCAM
 SG_ IsgTqActChks : 359|8@0+ (1.0,0.0) [0.0|255.0] "Unitless" TCAM
 SG_ IsgTqActCntr : 367|4@0+ (1.0,0.0) [0.0|15.0] "Unitless" TCAM
 SG_ IsgTqActIsgTqAct : 343|14@0+ (1.0,-8188.0) [-8188.0|8192.0] "NewtonMeter" TCAM
 SG_ IsgTqActQualityFactor : 345|2@0+ (1,0) [0|3] "" TCAM
 SG_ IsgUDc : 362|11@0+ (0.25,0.0) [0.0|511.0] "Volt" TCAM
 SG_ IsgUDc_UB : 363|1@0+ (1,0) [0|1] "" TCAM
 SG_ LimnIndcnDcDc : 383|16@0+ (1.0,0.0) [0.0|65535.0] "Unitless" TCAM
 SG_ LimnIndcnDcDc_UB : 221|1@0+ (1,0) [0|1] "" TCAM
 SG_ PwrCnsAvgIndcd_UB : 329|1@0+ (1,0) [0|1] "" TCAM
 SG_ PwrCnsAvgIndcd1_UB : 427|1@0+ (1,0) [0|1] "" TCAM
 SG_ PwrCnsAvgIndcd1EcoDrvInfo1 : 423|11@0+ (0.1,-102.3) [-102.3|102.30000000000003] "Unitless" TCAM
 SG_ PwrCnsAvgIndcd1PwrCnsUnit : 428|1@0+ (1,0) [0|1] "" TCAM
 SG_ PwrCnsAvgIndcdEcoDrvInfo1 : 399|11@0+ (0.1,-102.3) [-102.3|102.30000000000003] "Unitless" TCAM
 SG_ PwrCnsAvgIndcdPwrCnsUnit : 404|1@0+ (1,0) [0|1] "" TCAM
 SG_ PwrCnsIndcd_UB : 328|1@0+ (1,0) [0|1] "" TCAM
 SG_ PwrCnsIndcdCnsUnit : 403|1@0+ (1,0) [0|1] "" TCAM
 SG_ PwrCnsIndcdPwrCnsIn : 402|11@0+ (0.1,-100.0) [-100.0|100.0] "Unitless" TCAM
 SG_ SrvTrig : 443|4@0+ (1.0,0.0) [0.0|15.0] "Unitless" TCAM
 SG_ SrvTrig_UB : 444|1@0+ (1,0) [0|1] "" TCAM
 SG_ VehBattU_UB : 445|1@0+ (1,0) [0|1] "" TCAM
 SG_ VehBattUSysU : 439|8@0+ (0.1,0.0) [0.0|25.0] "Volt" TCAM
 SG_ VehBattUSysUQf : 447|2@0+ (1,0) [0|3] "" TCAM
 SG_ VehSpdAvgIndcd_UB : 460|1@0+ (1,0) [0|1] "" TCAM
 SG_ VehSpdAvgIndcdVehSpdIndcd : 455|9@0+ (1.0,0.0) [0.0|511.0] "Unitless" TCAM
 SG_ VehSpdAvgIndcdVeSpdIndcdUnit : 462|2@0+ (1,0) [0|3] "" TCAM
 SG_ VehSpdIndcd_UB : 459|1@0+ (1,0) [0|1] "" TCAM
 SG_ VehSpdIndcdQly : 425|2@0+ (1,0) [0|3] "" TCAM
 SG_ VehSpdIndcdQly_UB : 426|1@0+ (1,0) [0|1] "" TCAM
 SG_ VehSpdIndcdVehSpdIndcd : 456|9@0+ (1.0,0.0) [0.0|511.0] "Unitless" TCAM
 SG_ VehSpdIndcdVeSpdIndcdUnit : 458|2@0+ (1,0) [0|3] "" TCAM
 SG_ WhlMotSysTqEst_UB : 499|1@0+ (1,0) [0|1] "" TCAM
 SG_ WhlMotSysTqEstChks : 495|8@0+ (1.0,0.0) [0.0|255.0] "Unitless" TCAM
 SG_ WhlMotSysTqEstCntr : 503|4@0+ (1.0,0.0) [0.0|15.0] "Unitless" TCAM
 SG_ WhlMotSysTqEstIsgTqAct : 479|14@0+ (1.0,-8188.0) [-8188.0|8192.0] "NewtonMeter" TCAM
 SG_ WhlMotSysTqEstQualityFactor : 481|2@0+ (1,0) [0|3] "" TCAM

BO_ 976 DhuConnCANFDFr16 : 64 IHU
 SG_ OTAMod : 111|8@0+ (1,0) [0|255] "" TCAM
 SG_ OTAMod_UB : 90|1@0+ (1,0) [0|1] "" TCAM
 SG_ PrkgCameraRes : 103|2@0+ (1,0) [0|3] "" TCAM
 SG_ PrkgCameraRes_UB : 89|1@0+ (1,0) [0|1] "" TCAM
 SG_ PrkgCameraSwt : 101|1@0+ (1,0) [0|1] "" TCAM
 SG_ PrkgCameraSwt_UB : 88|1@0+ (1,0) [0|1] "" TCAM
 SG_ VehTiAndData_UB : 7|1@0+ (1,0) [0|1] "" TCAM
 SG_ VehTiAndDataDataValid : 6|1@0+ (1,0) [0|1] "" TCAM
 SG_ VehTiAndDataDay : 28|5@0+ (1.0,0.0) [1.0|31.0] "Days" TCAM
 SG_ VehTiAndDataHr1 : 20|5@0+ (1.0,0.0) [0.0|23.0] "hours" TCAM
 SG_ VehTiAndDataMins1 : 13|6@0+ (1.0,0.0) [0.0|59.0] "Mins" TCAM
 SG_ VehTiAndDataMth1 : 35|4@0+ (1.0,0.0) [1.0|12.0] "Month" TCAM
 SG_ VehTiAndDataSec1 : 5|6@0+ (1.0,0.0) [0.0|59.0] "s" TCAM
 SG_ VehTiAndDataYr1 : 46|7@0+ (1.0,0.0) [0.0|99.0] "Year" TCAM
 SG_ WhlMotSysIdc : 55|14@0+ (0.1,-818.8) [-818.8|819.2] "A" TCAM
 SG_ WhlMotSysIdc_UB : 57|1@0+ (1,0) [0|1] "" TCAM
 SG_ WhlMotSysSpdAct : 71|15@0- (1.0,0.0) [-16384.0|16383.0] "rpm" TCAM
 SG_ WhlMotSysSpdAct_UB : 72|1@0+ (1,0) [0|1] "" TCAM
 SG_ WhlMotSysUdc : 87|11@0+ (0.25,0.0) [0.0|511.0] "Volt" TCAM
 SG_ WhlMotSysUdc_UB : 92|1@0+ (1,0) [0|1] "" TCAM

BO_ 341 DHUConnCANFDSecOCSyncFr : 64 IHU
 SG_ TripResetSyncMsgAuthenticator : 47|88@0+ (1.0,0.0) [0.0|309485009821345070000000000.0] "Unitless" TCAM
 SG_ TripResetSyncMsgResetcounter : 31|16@0+ (1.0,0.0) [0.0|65535.0] "Unitless" TCAM
 SG_ TripResetSyncMsgTripcounter : 7|24@0+ (1.0,0.0) [0.0|16777215.0] "Unitless" TCAM

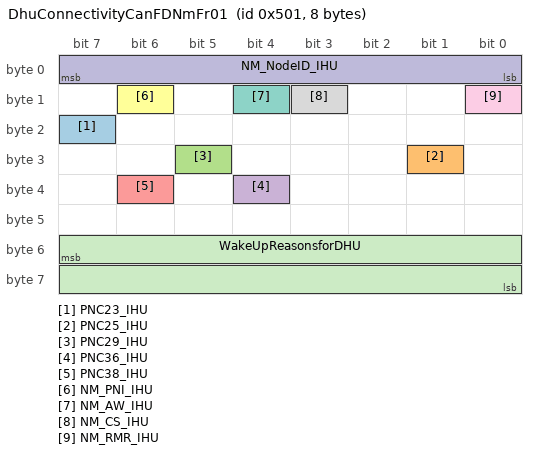
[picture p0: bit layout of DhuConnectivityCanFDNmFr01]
BO_ 1281 DhuConnectivityCanFDNmFr01 : 8 IHU
 SG_ PNC23_IHU : 23|1@0+ (1,0) [0|0] "" Vector__XXX
 SG_ PNC25_IHU : 25|1@0+ (1,0) [0|0] "" Vector__XXX
 SG_ PNC29_IHU : 29|1@0+ (1,0) [0|0] "" Vector__XXX
 SG_ PNC36_IHU : 36|1@0+ (1,0) [0|0] "" Vector__XXX
 SG_ PNC38_IHU : 38|1@0+ (1,0) [0|0] "" Vector__XXX
 SG_ NM_PNI_IHU : 14|1@0+ (1,0) [0|0] "" Vector__XXX
 SG_ NM_AW_IHU : 12|1@0+ (1,0) [0|0] "" Vector__XXX
 SG_ NM_CS_IHU : 11|1@0+ (1,0) [0|0] "" Vector__XXX
 SG_ NM_RMR_IHU : 8|1@0+ (1,0) [0|0] "" Vector__XXX
 SG_ NM_NodeID_IHU : 7|8@0+ (1,0) [0|0] "" Vector__XXX

 SG_ WakeUpReasonsforDHU : 55|16@0+ (1,0) [0|65535] "" Vector__XXX

BO_ 2047 DhuToAllFuncConnectivityCANFDDiagReqFrame : 8 IHU

BO_ 1889 DhuToIrrmConnectivityCANFDDiagReqFrame : 64 IHU

BO_ 1829 DhuToNkr2ConnectivityCANFDDiagReqFrame : 64 IHU

BO_ 1830 DhuToWpc3ConnectivityCANFDDiagReqFrame : 64 IHU

BO_ 1573 Nkr2ToDhuConnectivityCANFDDiagResFrame : 64 TCAM

CM_ SG_ 880 BookChrgnTarValFb "Feedback the corresponding signal when receives BookChrgnTarVal from TCAM";
CM_ SG_ 880 BookTrvlHeatgStsFb "book travel heating states feedback";
CM_ SG_ 880 BookTrvlPreHeatgFb "Feedback for book travel preheating function";
CM_ SG_ 880 CarLoctrActvnSts "Notification to telematics if the Car locator activation has failed. System1 for Exterior light AND System2 for Sound and signaling.";
CM_ SG_ 880 CdsParkgClimaActv "CDS parking climatization activation status.";
CM_ SG_ 880 ClimaOvrHeatProActv "Over heat protection function activation status.";
CM_ SG_ 880 ClimaOvrHeatProActvSts "Feedback over heat protection function enable/disable.";
CM_ SG_ 880 CmptmtRelHum "compartment relative humidity value for climate control.";
CM_ SG_ 880 DchaChrgnTarValFb "Feedback the corresponding signal when receivesDchaChrgnTarVal from TCAM";
CM_ SG_ 880 DigKeyLogUploadSwt "Digital key log upload switch";
CM_ SG_ 880 DrvrSeatHeatgAvlSts "Seat heating on, off, error and limitation status for driver seat.";
CM_ SG_ 880 DrvrSeatHeatgLvlSts "Seat heating level for first row driver seat.";
CM_ SG_ 880 DrvrSeatVentAvlSts "Seat ventilation on, off, error and limitation status for driver seat.";
CM_ SG_ 880 DrvrSeatVentnLvlSts "Seat ventilation level for first row driver seat.";
CM_ SG_ 880 EngN2 "Engine Speed [rpm]";
CM_ SG_ 880 FragCh1Id "Fragrance channel 1 ID from climate to Hmi.";
CM_ SG_ 880 FragCh1UseUpWrn "To remind customer the fragrance channel 1 use up.";
CM_ SG_ 880 FragCh2Id "Fragrance channel 1 ID from climate to Hmi.";
CM_ SG_ 880 FragCh2UseUpWrn "To remind customer the fragrance channel 2 use up.";
CM_ SG_ 880 FragCh3Id "Fragrance channel 1 ID from climate to Hmi.";
CM_ SG_ 880 FragCh3UseUpWrn "To remind customer the fragrance channel 3 use up.";
CM_ SG_ 880 FragCh4Id "Fragrance channel 1 ID from climate to Hmi.";
CM_ SG_ 880 FragCh4UseUpWrn "To remind customer the fragrance channel 4 use up.";
CM_ SG_ 880 FragCh5Id "Fragrance channel 1 ID from climate to Hmi.";
CM_ SG_ 880 FragCh5UseUpWrn "To remind customer the fragrance channel 5 use up.";
CM_ SG_ 880 FragLvlFrmClima "Fragrance level status from climate.";
CM_ SG_ 880 FragStsFrmClima "Fragrance use up and error warn from climate to Hmi.";
CM_ SG_ 880 HmiCarLocatorSetReq "HMI send a button to control Tcam Locate Vehicle service request .";
CM_ SG_ 880 HvCellTDifFlt "the fault of BMSH CellTemp Uniformity";
CM_ SG_ 880 HvCellUDifFlt "the fault of BMSH CellVolt Uniformity";
CM_ SG_ 880 HvCellUOverFlt "the fault of BMSH Cell OverVoltage";
CM_ SG_ 880 HvCellUUnderFlt "the fault of BMSH Cell underVoltage";
CM_ SG_ 880 HvilFlt "the fault of VCU TBOX HVILState";
CM_ SG_ 880 HvIsoFlt "the fault of BMSH InsulationRes Fault";
CM_ SG_ 880 HvPackOverChrgFlt "the fault of BMSH Pack Overcharge";
CM_ SG_ 880 HvPackUOverFlt "the fault of BMSH Pack OverVoltage";
CM_ SG_ 880 HvPackUUnderFlt "the fault of BMSH Pack UnderVoltage";
CM_ SG_ 880 HvSocHiFlt "the fualt of BMSH Over SOC";
CM_ SG_ 880 HvSocHopFlt "the fault of BMSH SOC Hop";
CM_ SG_ 880 HvSocLoFlt "the fualt of BMSH Low SOC";
CM_ SG_ 880 IntPm25StsFrmClima "Interior Pm 2.5 sensor status feedback.";
CM_ SG_ 880 KeyIntrVldDetd "Informs when a key search (lowest security level as locking or unlocking the vehicle) has found a valid key inside the vehicle.";
CM_ SG_ 880 LiBattInPWLockTC "Li-ion battery power locking mobile phone APP reminder signal
When BMS2 sends BattFltStsPrim=15, set LiBattInPWLockTC=1 for 20s, the mobile phone APP needs to send a reminder text. In order to avoid reminding customers repeatedly and causing complaints, this signal is only set once when an ignition cycle meets the conditions, LiBattInPWLock=0, Indicates that no reminder is required.
";
CM_ SG_ 880 OutdPm25LvlFrmClima "Outside PM 2.5 level of compartment.";
CM_ SG_ 880 OutdPm25VluFrmClima "Outside PM2.5 value of compartment.";
CM_ SG_ 880 PassSeatHeatgAvlSts "Seat heating on, off, error and limitation status for passenger seat.";
CM_ SG_ 880 PassSeatHeatgLvlSts "Seat heating level for first row passenger seat.";
CM_ SG_ 880 PassSeatVentAvlSts "Seat ventilation on, off, error and limitation status for passenger seat.";
CM_ SG_ 880 PassSeatVentnLvlSts "Seat ventilation level for first row passenger seat.";
CM_ SG_ 880 PrkgClimaWarn "Informs if anything has gone wrong with the parking climatisation.";
CM_ SG_ 880 RelHumSnsrRelHum "Compartment relative humidity signal.";
CM_ SG_ 880 RemClimaActv "Remote climate start status.";
CM_ SG_ 880 RemClimaDefrstSts "Feedback remote defrost status to HMI/Telematics";
CM_ SG_ 880 RemClimaDelaySts "remote climate delay request status feedback.";
CM_ SG_ 880 RemClimaExtnTiRspn "Remote climate delay time execution response.";
CM_ SG_ 880 RemClimaHvRspn "Remote climate high voltage request receiving response to telematics system.";
CM_ SG_ 880 RemClimaHvSts "Climate request high voltage status.";
CM_ SG_ 880 RemClimaWarn "Remote climate activation failure feedback.";
CM_ SG_ 880 RemStrtClimaRspn "remote start climatization response to telematics.";
CM_ SG_ 880 RemVentActvSts "Report remote ventilation activation status.";
CM_ SG_ 880 RemVentReqRspnFb "Feedback to telematics whether receive remote ventilation activate/deactivate successfully.";
CM_ SG_ 880 RemVentWarnSts "Reporting actuator or energy errors during RemVent ";
CM_ SG_ 880 SteerWhlHeatgAvlSts "Steering wheel heating activation, deactivation, unavailable and error status.";
CM_ SG_ 880 SunCurtImpctDetnSts2 "Interface reporting Status of Sun Curtain Impact Detection. ";
CM_ SG_ 880 SunCurtMvngSts "Interface indicating movement status of Sun Curtain. Value TRUE equals movement";
CM_ SG_ 880 SunCurtPosnSts "Interface Reporting Sun Curtain Position Status.";
CM_ SG_ 880 SunRoofAndCurtFailrCurtMotFailr "Curtain motor short circuit";
CM_ SG_ 880 SunRoofAndCurtFailrCurtMotHallFailr "Curtain motor hall sensor short or open";
CM_ SG_ 880 SunRoofAndCurtFailrCurtMotNotAvl "Curtain motor open circuit";
CM_ SG_ 880 SunRoofAndCurtFailrEcuFailrGen "General failure in the SRM ECU
";
CM_ SG_ 880 SunRoofAndCurtFailrPanMotFailr "Panel motor short circuit";
CM_ SG_ 880 SunRoofAndCurtFailrPanMotHallFailr "Panel motor hall sensor short or open";
CM_ SG_ 880 SunRoofAndCurtFailrPanMotNotAvl "Panel motor open circuit";
CM_ SG_ 880 SunRoofAndCurtFailrResvd "Resevered value, not used";
CM_ SG_ 880 SunRoofMvngSts "Interface indicating movement status of Sun Roof. Value TRUE equals movement";
CM_ SG_ 880 TankFlapSts "TankFlapSts -Tank Flap Status
Ukwn - Unknown status
Opend - Opened
Clsd - Closed";
CM_ SG_ 880 WhlMotSysInvrT "The inverter temperature measured in the IEM.";
CM_ SG_ 880 WhlMotSysMotT "The temperature of motor";
CM_ SG_ 880 WinFailrStsAtPass "Report failure if Window motor is not possible to Run";
CM_ SG_ 880 WinFailrStsAtReRi "Report failure if Window motor is not possible to Run";
CM_ SG_ 672 ClimaOvrHeatProRspn "Response signal used to notice telematics system that climate control system already receive setting signal for over heat protection from telematics system successfully.";
CM_ SG_ 672 ClimaOvrHeatProWarn "Feedback warning of Over heat protection function";
CM_ SG_ 672 ClsdDueToRain "Signal to telematics that the sunroof was successully closed due to rain";
CM_ SG_ 672 SchedCmptHeatCoolFB "Scheduled Climate Status Feedback signal";
CM_ SG_ 672 VehCfgPrmBlkIDBytePosn1 "signal block counter.";
CM_ SG_ 672 VehCfgPrmCCPBytePosn2 " (BlockID-1)*7 + 1. ";
CM_ SG_ 672 VehCfgPrmCCPBytePosn3 " (BlockID-1)*7 + 2. ";
CM_ SG_ 672 VehCfgPrmCCPBytePosn4 " (BlockID-1)*7 + 3. ";
CM_ SG_ 672 VehCfgPrmCCPBytePosn5 " (BlockID-1)*7 + 4. ";
CM_ SG_ 672 VehCfgPrmCCPBytePosn6 " (BlockID-1)*7 + 5. ";
CM_ SG_ 672 VehCfgPrmCCPBytePosn7 " (BlockID-1)*7 + 6. ";
CM_ SG_ 672 VehCfgPrmCCPBytePosn8 " (BlockID-1)*7 + 7. ";
CM_ SG_ 672 VehCfgPrmExtBlkIDBytePosn1 "CarConfigExtended BlockID";
CM_ SG_ 672 VehCfgPrmExtCCPBytePosn2 "CarConfigExtended BytePos2";
CM_ SG_ 672 VehCfgPrmExtCCPBytePosn3 "CarConfigExtended BytePos3";
CM_ SG_ 672 VehCfgPrmExtCCPBytePosn4 "CarConfigExtended BytePos4";
CM_ SG_ 672 VehCfgPrmExtCCPBytePosn5 "CarConfigExtended BytePos5";
CM_ SG_ 672 VehCfgPrmExtCCPBytePosn6 "CarConfigExtended BytePos6";
CM_ SG_ 672 VehCfgPrmExtCCPBytePosn7 "CarConfigExtended BytePos7";
CM_ SG_ 672 VehCfgPrmExtCCPBytePosn8 "CarConfigExtended BytePos8";
CM_ SG_ 672 VinBlockNr "VIN number block counter. ";
CM_ SG_ 672 VinVINSignalPos1 "VIN byte 1. Used for character 1, 8 and 15.";
CM_ SG_ 672 VinVINSignalPos2 "VIN byte 2. Used for character 2, 9 and 16.";
CM_ SG_ 672 VinVINSignalPos3 "VIN byte 3. Used for character 3, 10 and 17.";
CM_ SG_ 672 VinVINSignalPos4 "VIN byte 4. Used for character 4 and 11.";
CM_ SG_ 672 VinVINSignalPos5 "VIN byte 5. Used for character 5 and 12.";
CM_ SG_ 672 VinVINSignalPos6 "VIN byte 6. Used for character 6 and 13.";
CM_ SG_ 672 VinVINSignalPos7 "VIN byte 7. Used for character 7 and 14.";
CM_ SG_ 1008 LocalBookChrgnTarVal "Battery SOC Value";
CM_ SG_ 1008 MaxAcInpCurrentSet "set the input current";
CM_ SG_ 48 CarTiGlb "Presents a tiime value that shall be used by all ECUs to time-stamp diagnsotic trouble codes (DTC) according to the requirements for Global DTC snapshot data.";
CM_ SG_ 48 DoorDrvrLockSts "DoorDrvrLockSts - Driver Door Lock Status
Lock status
LockStsUkwn - Lock Status Unknown
Unlckd - Unlocked
Lockd - Locked
SafeLockd - Safe Locked (Double Locked)";
CM_ SG_ 48 DoorDrvrSts "DoorDrvrSts - Driver Door Status
Ukwn - Unknown status
Opend - Opened
Clsd - Closed";
CM_ SG_ 48 DoorLeReLockSts "DoorLeReLockSts - Left Rear Door Lock Status
Lock status
LockStsUkwn - Lock Status Unknown
Unlckd - Unlocked
Lockd - Locked
SafeLockd - Safe Locked (Double Locked)";
CM_ SG_ 48 DoorLeReSts "DoorLeReSts - Left Rear Side Door Status.
Ukwn - Unknown status
Opend - Opened
Clsd - Closed";
CM_ SG_ 48 DoorPassLockSts "DoorPassLockSts - Passenger Door Lock Status
Lock status
LockStsUkwn - Lock Status Unknown
Unlckd - Unlocked
Lockd - Locked
SafeLockd - Safe Locked (Double Locked)";
CM_ SG_ 48 DoorPassSts "DoorPassSts - Passenger Door Status
Ukwn - Unknown status
Opend - Opened
Clsd - Closed";
CM_ SG_ 48 DoorRiReLockSts "DoorRiReLockSts - Right Rear Door Lock Status
Lock status
LockStsUkwn - Lock Status Unknown
Unlckd - Unlocked
Lockd - Locked
SafeLockd - Safe Locked (Double Locked)";
CM_ SG_ 48 DoorRiReSts "DoorRiReSts - Right Rear Side Door Status
Ukwn - Unknown status
Opend - Opened
Clsd - Closed";
CM_ SG_ 48 LockgCenStsLockSt "Signal LockgCenSts provides central locking status to other subsystems.
Signal is a record with three items
- LockSt (Lock State)
- TrigSrc (Trig Source)
- UpdEve (Will be set to TRUE during one second at each new central locking or unlocking event)";
CM_ SG_ 48 LockgCenStsTrigSrc "Signal LockgCenSts provides central locking status to other subsystems.
Signal is a record with three items
- LockSt (Lock State)
- TrigSrc (Trig Source)
- UpdEve (Will be set to TRUE during one second at each new central locking or unlocking event)";
CM_ SG_ 48 LockgCenStsUpdEve "Signal LockgCenSts provides central locking status to other subsystems.
Signal is a record with three items
- LockSt (Lock State)
- TrigSrc (Trig Source)
- UpdEve (Will be set to TRUE during one second at each new central locking or unlocking event)";
CM_ SG_ 48 RecOfImpct2ImpctDvxSigned "Crash information , changed velocity in x direction , data with sign";
CM_ SG_ 48 RecOfImpct2ImpctDvySigned "Crash information , changed velocity in y direction, data with sign";
CM_ SG_ 48 RecOfImpctCrashFrnt "Crash information, if crash is frontal";
CM_ SG_ 48 RecOfImpctCrashOffroadA "Incident information, if driving off road and becoming airbourne has been detected.";
CM_ SG_ 48 RecOfImpctCrashOffroadD "Inicdent information, if driving into a ditch has been detected";
CM_ SG_ 48 RecOfImpctCrashOffroadRT "Incident information, if driving off the road and into rough terrain has been detected.";
CM_ SG_ 48 RecOfImpctCrashOffroadRTsevere "Incident information, if driving off road and into severe rough terrain has been detected.";
CM_ SG_ 48 RecOfImpctCrashPed "Incident information, if a pedestrian protection triggering has been made";
CM_ SG_ 48 RecOfImpctCrashRe "Crash information, if crash is rear";
CM_ SG_ 48 RecOfImpctCrashRollovr "Crash information, if crash is roll-over";
CM_ SG_ 48 RecOfImpctCrashSideLe "Crash information, if crash is left side";
CM_ SG_ 48 RecOfImpctCrashSideRi "Crash information, if crash is right side";
CM_ SG_ 48 RecOfImpctCrashState "Crash information, State of the crash";
CM_ SG_ 48 RecOfImpctImpctDvx "Crash information, change in velocity in x-direction";
CM_ SG_ 48 RecOfImpctImpctDvy "Crash information, change in velocity in y-direction";
CM_ SG_ 48 RecOfImpctImpctRollAg "Crash information, cumulative roll angle";
CM_ SG_ 48 RecOfImpctVehOri "Crash information, Vehicle orientation once crash subsides";
CM_ SG_ 48 TrLockSts "TrLockSts - Tailgate or bootlid lock status
LockStsUkwn - Lock status of tailgate or bootlid Unknown
Unlckd - Tailgate or Bootlid is unlocked
Lockd - Tailgate or Bootlid is locked
SafeLockd - Not used for Tailgate or Bootlid";
CM_ SG_ 48 TrSts "TrSts - Tailgate or Bootlid Status
Ukwn - Unknown status
Opend - Opened
Clsd - Closed";
CM_ SG_ 944 AccrPedlPsdAccrPedlPsd "Describes if the accelerator pedal is pressed. Will indicate pressed for a small pedal press. Accompanying status signal will indicate the integrity of the information.";
CM_ SG_ 944 AccrPedlPsdChks "Describes if the accelerator pedal is pressed. Will indicate pressed for a small pedal press.checksum";
CM_ SG_ 944 AccrPedlPsdCntr "Describes if the accelerator pedal is pressed. Will indicate pressed for a small pedal press.couner";
CM_ SG_ 944 AccrPedlPsdSts "Describes if the accelerator pedal is pressed. Will indicate pressed for a small pedal press. Accompanying status signal will indicate the integrity of the information. AccrPedlPsd fulfills ASIL C integrity";
CM_ SG_ 944 AjarChrgLidRearSwitch "AjarChrgLidRearSwitch - Rear Charge Lid Switch status
Ukwn - Unknown status
Opend - Opened
Clsd - Closed";
CM_ SG_ 944 DCChrgSt "DC charging state";
CM_ SG_ 944 EscWarnIndcnReqChks "Esc warning indication request or indication to driver that the Esc function is in active intervention. In case of disabled Esc the warning telltale shall be permanently lit. In case of active intervention indication the telltale will flash. Checksum for Esc warning indication request";
CM_ SG_ 944 EscWarnIndcnReqCntr "Esc warning indication request or indication to driver that the Esc function is in active intervention. In case of disabled Esc the warning telltale shall be permanently lit. In case of active intervention indication the telltale will flash. Counter for Esc warning indication request";
CM_ SG_ 944 EscWarnIndcnReqEscWarnIndcnReq "Esc warning indication request or indication to driver that the Esc function is in active intervention. In case of disabled Esc the warning telltale shall be permanently lit. In case of active intervention indication the telltale will flash. Esc warning indication request
";
CM_ SG_ 944 GearIndcnRecGearIndcn "Record contains two signals. 1. Actual gear displayed for the driver 2. Recommended shift up or down to obtain maximal fuel economy and driveability.";
CM_ SG_ 944 GearIndcnRecGearShiftIndcn "Record contains two signals. 1. Actual gear displayed for the driver 2. Recommended shift up or down to obtain maximal fuel economy and driveability.";
CM_ SG_ 944 GearIndcnRecGearTarIndcn "Record contains two signals. 1. Actual gear displayed for the driver 2. Recommended shift up or down to obtain maximal fuel economy and driveability.";
CM_ SG_ 944 HvBattChrgnTiEstimd "The estimated charging time left.";
CM_ SG_ 944 HvIsoR "BMSH Pack InsulationRes";
CM_ SG_ 944 IemGenericADAlrmSt "Active Discharge fault alarm status";
CM_ SG_ 944 IemGenericDTCHig "DTC high byte for non OBD or OBD";
CM_ SG_ 944 IemGenericDTCLow "DTC low byte for non OBD";
CM_ SG_ 944 IemGenericDTCMid "DTC middle byte for non OBD DTC low byte for OBD";
CM_ SG_ 944 IemGenericDTCSts "DTC Status";
CM_ SG_ 944 IemGenericEMQnty "Quantity of electric motor";
CM_ SG_ 944 IemGenericEMSeqNr "Sequence number of electric motor";
CM_ SG_ 944 IemGenericFltAlrmSt "Fault alarm status";
CM_ SG_ 944 IemGenericIacAlrmSt "3 Phase current alarm status";
CM_ SG_ 944 IemGenericInvrtTAlrmSt "Inverter temperature alarm status";
CM_ SG_ 944 IemGenericModStatusRms "Motor status for RMS monitor";
CM_ SG_ 944 IemGenericMotTAlrmSt "Motor temperature alarm status";
CM_ SG_ 944 IemGenericRslAlrmSt "Resolver fault alarm status";
CM_ SG_ 944 IemGenericSpdAlrmSt "Over speed alarm status";
CM_ SG_ 944 IemGenericTypeInfo "Indicate different EDS suppliers. OEM defines this value.
0=not defined
1=PMA1 VseA, with ratio=10.134
2=PMA1 Nidec,with ratio=10.294
3=PMA1 VREMT,with ratio=11.56
4=SPAL Scheaffler,with ratio=9.071
5=SPA Simens, with ratio=10.008
6=PMA2 VREMT,with ratio=11.209
7=EPA ZF,with radio=9.187
8=EPA Polestar,with 2-gear ratio=7.155 and 13.645
9=PMA2 UAES,with ratio=11.067";
CM_ SG_ 944 IemGenericUDcAlrmSt "High voltage alarm status";
CM_ SG_ 944 IntPm25LvlFrmClima "Inside PM 2.5 level of compartment.";
CM_ SG_ 944 IntPm25VluFrmClima "Inside PM 2.5 value of compartment.";
CM_ SG_ 944 OnBdChrgrHndlSts1 "Status of the Onboard Charger connection to the grid. ";
CM_ SG_ 944 OnBdChrgrIAct "The actual AC input current";
CM_ SG_ 944 OnBdChrgrPwrEnaAllwd "Signaling that the OBC is allowed to deliver power to the car and battery. Flag to sync battery contactor state with OBC power. Battery Contactor shall be closed when OBC supplies HV power; 0 = Do not supply HV power; 1 = Do supply HV power";
CM_ SG_ 944 OnBdChrgrSt "The charging state of OBC";
CM_ SG_ 944 OnBdChrgrUAct "The actual AC input voltage";
CM_ SG_ 944 RemAllowStrt "Signal indicate validity of remote allow start";
CM_ SG_ 944 WirelschrgActvReqFromHmi "On Off";
CM_ SG_ 832 BookChargeSetResponse "Indicate bookcharging set response.";
CM_ SG_ 832 BrkAndAbsWarnIndcnReqAbsWarnIndcnReq "Request for warning indication to driver in case of brake failure (red warning) or ABS failure (yellow warning) ABS warning indication request";
CM_ SG_ 832 BrkAndAbsWarnIndcnReqBrkWarnIndcnReq "Request for warning indication to driver in case of brake failure (red warning) or ABS failure (yellow warning) Brake warning indication request";
CM_ SG_ 832 BrkAndAbsWarnIndcnReqChks "Request for warning indication to driver in case of brake failure (red warning) or ABS failure (yellow warning) Checksum for Brake and ABS warning indication request";
CM_ SG_ 832 BrkAndAbsWarnIndcnReqCntr "Request for warning indication to driver in case of brake failure (red warning) or ABS failure (yellow warning) Counter for Brake and ABS warning indication request";
CM_ SG_ 832 DispOfPrpsnMod "Description: Actual powertrain propulsion mode of the hybrid propulsion system. Usage: For hybrid power flow status display in HMI.";
CM_ SG_ 832 EngForbidRespFromVMM "response for Telematic that VMM had received EngForbidReq and stored in NVM";
CM_ SG_ 832 NetDHUActvt "It describes which state managers that are member of each resource group.";
CM_ SG_ 832 NotifForEmgyCall "Information if there is a need for the vehicle to perform an emergency call.";
CM_ SG_ 832 PassSeatSnsrSts2 "Informs if there is a fault on the Passenger seat sensor is detected through electrical measurements, or plausibility judgement. NotOk means sensor is judged as faulty. Di means that the sensor is not configured.";
CM_ SG_ 832 PassSeatSts2 "Describes if an occupant is detected in the passenger seat.";
CM_ SG_ 832 TCSDoorNoClsSts "TCSDoorNoClsSts";
CM_ SG_ 832 TrOpenerByFootOperCmd "TrOpenerByFootOperCmd - Command for FMDM (Foot Movement Detection Module)
This signal is used to activate or deactivate FMDM foor movement detection.
On - Foot movement detection ON
Off - Foot movement detection OFF";
CM_ SG_ 832 TrsmParkLockdChks "Checksum for TrsmParkLockd";
CM_ SG_ 832 TrsmParkLockdCntr "Counter for TrsmParkLockd";
CM_ SG_ 832 TrsmParkLockdTrsmParkLockd "Transmission park lock status";
CM_ SG_ 832 VehMtnStChks "Vehicle motion state information based on wheel speed sensors. Provides information about vehicle stand still and vehicle rolling direction. Checksum for vehicle motion state";
CM_ SG_ 832 VehMtnStCntr "Vehicle motion state information based on wheel speed sensors. Provides information about vehicle stand still and vehicle rolling direction. Counter for vehicle motion state";
CM_ SG_ 832 VehMtnStVehMtnSt "Vehicle motion state information based on wheel speed sensors. Provides information about vehicle stand still and vehicle rolling direction. Vehicle motion state";
CM_ SG_ 832 WirelsChrgFrntLeSwt "This signal is designed for Front row Left wpc charging control switch.";
CM_ SG_ 832 WirelsChrgFrntRiSwt "This signal is designed for Front row Right wpc charging control switch.";
CM_ SG_ 272 ClimaActv "Informs if a parking climatisation is active (either pre- or post conditioning).";
CM_ SG_ 272 HoodSts "HoodSts - Hood Status
Ukwn - Unknown status
Opend - Opened
Clsd - Closed";
CM_ SG_ 272 SunRoofPosnSts "Sun roof position status";
CM_ SG_ 272 WinPosnStsAtDrvr "Signal sent to inform the rest of the car of the window position status for the front driver side door. The value of the signal is either an approximated percentage of openness, of the window is moving or if the position is unkown.
";
CM_ SG_ 272 WinPosnStsAtPass "Signal sent to inform the rest of the car of the window position status for the front passenger side door. The value of the signal is either an approximated percentage of openness, of the window is moving or if the position is unkown.
";
CM_ SG_ 272 WinPosnStsAtReLe "Signal sent to inform the rest of the car of the window position status for the rear driver side door. The value of the signal is either an approximated percentage of openness, of the window is moving or if the position is unkown.

";
CM_ SG_ 272 WinPosnStsAtReRi "Signal sent to inform the rest of the car of the window position status for the rear passenger side door. The value of the signal is either an approximated percentage of openness, of the window is moving or if the position is unkown.
";
CM_ SG_ 800 ChrgnByEngStsDurgDcha "Status of charging by engine during discharging";
CM_ SG_ 800 ChrgnWarn "ECM send the warning message to TCAM aim to indicate driver to charging";
CM_ SG_ 800 EgyRegenEgyAct "Regeneration energy accumulated in signal driving cycle";
CM_ SG_ 800 EngFltIndcn1 "engine fault indication";
CM_ SG_ 800 EngFltIndcn10 "engine fault indication";
CM_ SG_ 800 EngFltIndcn11 "engine fault indication";
CM_ SG_ 800 EngFltIndcn12 "engine fault indication";
CM_ SG_ 800 EngFltIndcn13 "engine fault indication";
CM_ SG_ 800 EngFltIndcn14 "engine fault indication";
CM_ SG_ 800 EngFltIndcn15 "engine fault indication";
CM_ SG_ 800 EngFltIndcn16 "engine fault indication";
CM_ SG_ 800 EngFltIndcn17 "engine fault indication";
CM_ SG_ 800 EngFltIndcn18 "engine fault indication";
CM_ SG_ 800 EngFltIndcn19 "engine fault indication";
CM_ SG_ 800 EngFltIndcn2 "engine fault indication";
CM_ SG_ 800 EngFltIndcn20 "engine fault indication";
CM_ SG_ 800 EngFltIndcn21 "engine fault indication";
CM_ SG_ 800 EngFltIndcn22 "engine fault indication";
CM_ SG_ 800 EngFltIndcn23 "engine fault indication";
CM_ SG_ 800 EngFltIndcn24 "engine fault indication";
CM_ SG_ 800 EngFltIndcn25 "engine fault indication";
CM_ SG_ 800 EngFltIndcn26 "engine fault indication";
CM_ SG_ 800 EngFltIndcn27 "engine fault indication";
CM_ SG_ 800 EngFltIndcn3 "engine fault indication";
CM_ SG_ 800 EngFltIndcn4 "engine fault indication";
CM_ SG_ 800 EngFltIndcn5 "engine fault indication";
CM_ SG_ 800 EngFltIndcn6 "engine fault indication";
CM_ SG_ 800 EngFltIndcn7 "engine fault indication";
CM_ SG_ 800 EngFltIndcn8 "engine fault indication";
CM_ SG_ 800 EngFltIndcn9 "engine fault indication";
CM_ SG_ 800 EngOilLvlSts "Engine oil level status information.If no status currently can be derived [Not available] will be shown.";
CM_ SG_ 800 EngOilPWarn "Request to set low engine oil pressure warning to driver";
CM_ SG_ 800 IgmGenericADAlrmSt "Active Discharge fault alarm status";
CM_ SG_ 800 IgmGenericDTCHig "DTC high byte for non OBD or OBD";
CM_ SG_ 800 IgmGenericDTCLow "DTC low byte for non OBD";
CM_ SG_ 800 IgmGenericDTCMid "DTC middle byte for non OBD DTC low byte for OBD";
CM_ SG_ 800 IgmGenericDTCSts "DTC Status";
CM_ SG_ 800 IgmGenericEMQnty "Quantity of electric motor";
CM_ SG_ 800 IgmGenericEMSeqNr "Sequence number of electric motor";
CM_ SG_ 800 IgmGenericFltAlrmSt "Fault alarm status";
CM_ SG_ 800 IgmGenericIacAlrmSt "3 Phase current alarm status";
CM_ SG_ 800 IgmGenericInvrtTAlrmSt "Inverter temperature alarm status";
CM_ SG_ 800 IgmGenericModStatusRms "Motor status for RMS monitor";
CM_ SG_ 800 IgmGenericMotTAlrmSt "Motor temperature alarm status";
CM_ SG_ 800 IgmGenericRslAlrmSt "Resolver fault alarm status";
CM_ SG_ 800 IgmGenericSpdAlrmSt "Over speed alarm status";
CM_ SG_ 800 IgmGenericTypeInfo "Indicate different EDS suppliers. OEM defines this value.
0=not defined
1=PMA1 VseA, with ratio=10.134
2=PMA1 Nidec,with ratio=10.294
3=PMA1 VREMT,with ratio=11.56
4=SPAL Scheaffler,with ratio=9.071
5=SPA Simens, with ratio=10.008
6=PMA2 VREMT,with ratio=11.209
7=EPA ZF,with radio=9.187
8=EPA Polestar,with 2-gear ratio=7.155 and 13.645
9=PMA2 UAES,with ratio=11.067";
CM_ SG_ 800 IgmGenericUDcAlrmSt "High voltage alarm status";
CM_ SG_ 800 IsgIDc "DC current measured by the front inverter";
CM_ SG_ 800 IsgInvrT "Temperature of the inverter";
CM_ SG_ 800 IsgMotT "Temperature of the CISG";
CM_ SG_ 800 IsgSpdActSgn "Actual ISG speed with sign to indicate forward or backward direction";
CM_ SG_ 800 LockgCenStsForUsrFb "LockgCenStsForUsrFb - Central Locking Status for User Feedback
The signal is used to communicate central locking status to the user of the vehicle";
CM_ SG_ 800 OilMntnAlrmSt "Oil Maintenance Alarm State";
CM_ SG_ 800 PrpsnModElecDrvBlkd "Propulsion mode PURE ( i.e. Electric Drive) is not available.";
CM_ SG_ 968 DstTrvldHiResl "High resolution trip meter value, resolution of 1mwithamodulus256 counter counts 0 -255 etc.";
CM_ SG_ 968 DstTrvldMst2 "Driven distance in miles";
CM_ SG_ 968 EngHrToSrv "Engine hours left before a service shall be done";
CM_ SG_ 968 EngOilLvl "Engine oil level, Range 0-120 %";
CM_ SG_ 968 EngTEngT "Engine coolant temperature. Resolution 1 degC
";
CM_ SG_ 968 EngTQf "Engine coolant temperature quality factor.Engine coolant temperature";
CM_ SG_ 968 EpbStsChks "Electrical Park Brake system status information Status for the rear wheel park actuator";
CM_ SG_ 968 EpbStsCntr "Electrical Park Brake system status information Counter for EPB status";
CM_ SG_ 968 EpbStsEpbSts "Electrical Park Brake system status information Status for the rear wheel park actuator";
CM_ SG_ 968 FuCnsAvgIndcdFuCnsIndcdUnit "Average Fuel Consumption with indicated unit";
CM_ SG_ 968 FuCnsAvgIndcdFuCnsIndcdVal "Average Fuel Consumption signal.";
CM_ SG_ 968 FuCnsIndcdUnit "Instantaneous Fuel Consumption (IFC) with indicated unit IFC unit";
CM_ SG_ 968 FuCnsIndcdVal "Instantaneous Fuel Consumption (IFC) with indicated unit IFC value";
CM_ SG_ 968 FuLvlIndcdFuLvlValFromFuTbl " Fuel level value converted from fuel table";
CM_ SG_ 968 FuLvlIndcdGenQF "Quality Flag";
CM_ SG_ 968 FuLvlLoIndcn "Signal that indicated if the yellow low fuel tell tale is lit";
CM_ SG_ 968 FuLvlLoWarn "Signal that indicated if the RED low fuel warning LED is lit";
CM_ SG_ 968 GidInfoInp1Byte0 "GidInfo1";
CM_ SG_ 968 GidInfoInp1Byte1 "GidInfo2";
CM_ SG_ 968 GidInfoInp1Byte2 "GidInfo3";
CM_ SG_ 968 GidInfoInp1Byte3 "GidInfo4";
CM_ SG_ 968 GidInfoInp1Byte4 "GidInfo5";
CM_ SG_ 968 GidInfoInp1Byte5 "GidInfo6";
CM_ SG_ 968 GidInfoInp1Byte6 "GidInfo7";
CM_ SG_ 968 GidInfoInp1Byte7 "GidInfo8";
CM_ SG_ 968 GidInfoInp2Byte0 "GidInfo9";
CM_ SG_ 968 GidInfoInp2Byte1 "GidInfo10";
CM_ SG_ 968 GidInfoInp2Byte2 "GidInfo11";
CM_ SG_ 968 GidInfoInp2Byte3 "GidInfoResv1";
CM_ SG_ 968 GidInfoInp2Byte4 "GidInfoResv2";
CM_ SG_ 968 GidInfoInp2Byte5 "GidInfoResv3";
CM_ SG_ 968 GidInfoInp2Byte6 "GidInfoResv4";
CM_ SG_ 968 GidInfoInp2Byte7 "GidInfoResv5";
CM_ SG_ 968 HvBattLimnIndcn "Propulsion related LOS (Limited Operation Strategy) information from Hv Battery. LOS";
CM_ SG_ 968 HvBattSoc "Actual state of charge of the Hv Battery.";
CM_ SG_ 968 HvBattUDc "Actual Hv Battery pack voltage (measuered before contactors, i.e. always giving pack voltage).";
CM_ SG_ 968 HybErrIndcnReqTelltlBattTracCutOff " Traction Battery Cut-Off";
CM_ SG_ 968 HybErrIndcnReqTelltlBattTracFailr " Traction Battery Failure";
CM_ SG_ 968 HybErrIndcnReqTelltlElecDrvFailr " Electrical Machine and controller overheated";
CM_ SG_ 968 HybErrIndcnReqTelltlSysHybFailr " System Failure";
CM_ SG_ 968 IndcnUnitClkFmt "Clock Format";
CM_ SG_ 968 IndcnUnitDateFmt "DateFormat";
CM_ SG_ 968 IndcnUnitDstLong "Long Distance Units";
CM_ SG_ 968 IndcnUnitDstSho "Short Distance Units";
CM_ SG_ 968 IndcnUnitFuCnsUnit "Fuel Consumption Units";
CM_ SG_ 968 IndcnUnitPUnit "Pressure Unit";
CM_ SG_ 968 IndcnUnitSpdUnit "Speed Units";
CM_ SG_ 968 IndcnUnitTUnit "Temperature Unit";
CM_ SG_ 968 IndcnUnitVolUnit "Volume Units";
CM_ SG_ 968 IsgTqActChks "Checksum";
CM_ SG_ 968 IsgTqActCntr "Counter";
CM_ SG_ 968 IsgTqActIsgTqAct "Actual torque";
CM_ SG_ 968 IsgTqActQualityFactor "Quality factor";
CM_ SG_ 968 IsgUDc "HVDC voltage";
CM_ SG_ 968 LimnIndcnDcDc "Indication signal from the DcDc that tells that a DTC is set";
CM_ SG_ 968 PwrCnsAvgIndcd1EcoDrvInfo1 "AEC value";
CM_ SG_ 968 PwrCnsAvgIndcd1PwrCnsUnit "AEC unit";
CM_ SG_ 968 PwrCnsAvgIndcdEcoDrvInfo1 "AEC value";
CM_ SG_ 968 PwrCnsAvgIndcdPwrCnsUnit "AEC unit";
CM_ SG_ 968 PwrCnsIndcdCnsUnit "Unit";
CM_ SG_ 968 PwrCnsIndcdPwrCnsIn "Value for Display";
CM_ SG_ 968 SrvTrig "Information that a service reminder message is shown in the instrument cluster. Gives information of which parameter that trigged the message and which service reminder message that is shown.";
CM_ SG_ 968 VehBattUSysU "Vehicle System Voltage At 12V side";
CM_ SG_ 968 VehBattUSysUQf "Present vehicle voltage measured by CEM with QF";
CM_ SG_ 968 VehSpdAvgIndcdVehSpdIndcd "Vehicle speed";
CM_ SG_ 968 VehSpdAvgIndcdVeSpdIndcdUnit "Unit for vehicle speed";
CM_ SG_ 968 VehSpdIndcdQly "Indicated vehicle speed QF info.";
CM_ SG_ 968 VehSpdIndcdVehSpdIndcd "Vehicle speed";
CM_ SG_ 968 VehSpdIndcdVeSpdIndcdUnit "Unit for vehicle speed";
CM_ SG_ 968 WhlMotSysTqEstChks "Checksum of estimation torque";
CM_ SG_ 968 WhlMotSysTqEstCntr "Counter of estimation torque";
CM_ SG_ 968 WhlMotSysTqEstIsgTqAct "Estimation torque of Rear Axle Control";
CM_ SG_ 968 WhlMotSysTqEstQualityFactor "Quality factor of estimation torque";
CM_ SG_ 976 OTAMod "Define the phases of OTA functionality";
CM_ SG_ 976 PrkgCameraRes "The result of take picture when parking";
CM_ SG_ 976 PrkgCameraSwt "Take picture when parking switch";
CM_ SG_ 976 VehTiAndDataDataValid "Vehicle time (Hr, Min and Sec) and date (Year, Months and days) data for indication. See requirement for more information about the signals. Signal qualifier, No means values should be ignored.";
CM_ SG_ 976 VehTiAndDataDay "Vehicle time (Hr, Min and Sec) and date (Year, Months and days) data for indication. See requirement for more information about the signals. Day";
CM_ SG_ 976 VehTiAndDataHr1 "Vehicle time (Hr, Min and Sec) and date (Year, Months and days) data for indication. See requirement for more information about the signals. Hour";
CM_ SG_ 976 VehTiAndDataMins1 "Vehicle time (Hr, Min and Sec) and date (Year, Months and days) data for indication. See requirement for more information about the signals. Minutes";
CM_ SG_ 976 VehTiAndDataMth1 "Vehicle time (Hr, Min and Sec) and date (Year, Months and days) data for indication. See requirement for more information about the signals. Month, 1-12";
CM_ SG_ 976 VehTiAndDataSec1 "Vehicle time (Hr, Min and Sec) and date (Year, Months and days) data for indication. See requirement for more information about the signals. Seconds";
CM_ SG_ 976 VehTiAndDataYr1 "Vehicle time (Hr, Min and Sec) and date (Year, Months and days) data for indication. See requirement for more information about the signals. Year, 0-99";
CM_ SG_ 976 WhlMotSysIdc "DC current measured in the IEM.";
CM_ SG_ 976 WhlMotSysSpdAct "The actual rotational speed of rear motor";
CM_ SG_ 976 WhlMotSysUdc "The DC voltage of rear motor";
CM_ SG_ 341 TripResetSyncMsgAuthenticator "Compute the MAC for the freshness value";
CM_ SG_ 341 TripResetSyncMsgResetcounter "The master FV is kept in line with the slave FV tirp counter";
CM_ SG_ 341 TripResetSyncMsgTripcounter "The master FV is kept in line with the slave FV Reset counter";
CM_ SG_ 1281 WakeUpReasonsforDHU "WakeUpReasons";
BA_DEF_ BO_ "CANFD_BRS" ENUM "0","1";
BA_DEF_ BO_ "GenMsgCycleTime" INT 0 65536;
BA_DEF_ BO_ "GenMsgDelayTime" INT 0 65536;
BA_DEF_ BO_ "GenMsgSendType" ENUM "cyclic", "spontaneous", "not-used", "not-used", "not-used", "cyclicAndSpontaneous", "not-used", "cyclicIfActive", "NoMsgSendType";
BA_DEF_ BO_ "GenMsgStartDelayTime" INT 0 65536;
BA_DEF_ BO_ "VFrameFormat" ENUM "StandardCAN","ExtendedCAN","reserved","J1939PG","reserved","reserved","reserved","reserved","reserved","reserved","reserved","reserved","reserved","reserved","StandardCAN_FD","ExtendedCAN_FD";
BA_DEF_ SG_ "GenSigSendType" ENUM "Cyclic","OnWrite","OnWriteWithRepetition","OnChange","OnChangeWithRepetition","IfActive","IfActiveWithRepetition","NoSigSendType";
BA_DEF_ SG_ "GenSigStartValue" HEX 0 80000000;
BA_DEF_ BO_ "GenMsgILSupport" ENUM "No","Yes";
BA_DEF_ BO_ "NmAsrMessage" ENUM "No","Yes";
BA_DEF_ SG_ "GenSigFuncType" ENUM "NoFunction","n/a","n/a","n/a","n/a","n/a","n/a","n/a","n/a","n/a","n/a","n/a","n/a","n/a","n/a","CHK","CNTR","n/a","n/a","n/a","CNTR_AR_01","CRC_AR_01_BOTH","CRC_AR_01_ALT","CRC_AR_01_LOW","CRC_AR_01_NIBBLE","CNTR_AR_04","CRC_AR_04A","CNTR_AR_05","CRC_AR_05";
BA_DEF_ SG_ "GenSigDataID" STRING;
BA_DEF_ SG_ "SigGroup" STRING;
BA_DEF_DEF_ "CANFD_BRS" "1";
BA_DEF_DEF_ "GenSigStartValue" 0;
BA_DEF_DEF_ "VFrameFormat" "J1939PG";
BA_DEF_DEF_ "GenSigSendType" "NoSigSendType";
BA_DEF_DEF_ "GenMsgCycleTime" 0;
BA_DEF_DEF_ "GenMsgDelayTime" 0;
BA_DEF_DEF_ "GenMsgStartDelayTime" 0;
BA_DEF_DEF_ "GenMsgSendType" "NoMsgSendType";
BA_DEF_DEF_ "GenMsgILSupport" "Yes";
BA_DEF_DEF_ "NmAsrMessage" "No";
BA_DEF_DEF_ "GenSigFuncType" "NoFunction";
BA_DEF_DEF_ "GenSigDataID" "";
BA_DEF_DEF_ "SigGroup" "";

BA_ "GenMsgDelayTime" BO_ 341 50.000;
BA_ "GenMsgSendType" BO_ 341 1;
BA_ "VFrameFormat" BO_ 341 14;

BA_ "GenMsgCycleTime" BO_ 880 200.000;
BA_ "GenMsgSendType" BO_ 880 0;
BA_ "VFrameFormat" BO_ 880 14;

BA_ "GenMsgDelayTime" BO_ 672 80.000;
BA_ "GenMsgSendType" BO_ 672 1;
BA_ "VFrameFormat" BO_ 672 14;

BA_ "GenMsgDelayTime" BO_ 1008 400.000;
BA_ "GenMsgSendType" BO_ 1008 1;
BA_ "VFrameFormat" BO_ 1008 14;

BA_ "GenMsgCycleTime" BO_ 48 10.000;
BA_ "GenMsgSendType" BO_ 48 0;
BA_ "VFrameFormat" BO_ 48 14;

BA_ "GenMsgCycleTime" BO_ 944 350.000;
BA_ "GenMsgSendType" BO_ 944 0;
BA_ "VFrameFormat" BO_ 944 14;

BA_ "GenMsgCycleTime" BO_ 832 150.000;
BA_ "GenMsgSendType" BO_ 832 0;
BA_ "VFrameFormat" BO_ 832 14;

BA_ "GenMsgCycleTime" BO_ 272 20.000;
BA_ "GenMsgSendType" BO_ 272 0;
BA_ "VFrameFormat" BO_ 272 14;

BA_ "GenMsgCycleTime" BO_ 800 120.000;
BA_ "GenMsgSendType" BO_ 800 0;
BA_ "VFrameFormat" BO_ 800 14;

BA_ "GenMsgCycleTime" BO_ 968 400.000;
BA_ "GenMsgSendType" BO_ 968 0;
BA_ "VFrameFormat" BO_ 968 14;

BA_ "GenMsgCycleTime" BO_ 976 400.000;
BA_ "GenMsgSendType" BO_ 976 0;
BA_ "VFrameFormat" BO_ 976 14;

BA_ "GenMsgDelayTime" BO_ 1281 20.000;
BA_ "GenMsgSendType" BO_ 1281 1;
BA_ "VFrameFormat" BO_ 1281 0;

BA_ "GenMsgDelayTime" BO_ 2047 5.000;
BA_ "GenMsgSendType" BO_ 2047 1;
BA_ "VFrameFormat" BO_ 2047 14;

BA_ "GenMsgDelayTime" BO_ 1889 5.000;
BA_ "GenMsgSendType" BO_ 1889 1;
BA_ "VFrameFormat" BO_ 1889 14;

BA_ "GenMsgDelayTime" BO_ 1829 5.000;
BA_ "GenMsgSendType" BO_ 1829 1;
BA_ "VFrameFormat" BO_ 1829 14;

BA_ "GenMsgDelayTime" BO_ 1830 5.000;
BA_ "GenMsgSendType" BO_ 1830 1;
BA_ "VFrameFormat" BO_ 1830 14;

BA_ "GenMsgDelayTime" BO_ 1573 5.000;
BA_ "GenMsgSendType" BO_ 1573 1;
BA_ "VFrameFormat" BO_ 1573 14;
BA_ "GenMsgILSupport" BO_ 1281 0;
BA_ "NmAsrMessage" BO_ 1281 1;
BA_ "GenSigSendType" SG_ 944 AccrPedlPsdAccrPedlPsd 0;
BA_ "GenSigDataID" SG_ 944 AccrPedlPsdChks "0x48";
BA_ "GenSigFuncType" SG_ 944 AccrPedlPsdChks 15;
BA_ "GenSigSendType" SG_ 944 AccrPedlPsdChks 0;
BA_ "GenSigStartValue" SG_ 944 AccrPedlPsdChks 255;
BA_ "GenSigFuncType" SG_ 944 AccrPedlPsdCntr 16;
BA_ "GenSigSendType" SG_ 944 AccrPedlPsdCntr 0;
BA_ "GenSigSendType" SG_ 944 AccrPedlPsdSts 0;
BA_ "GenSigSendType" SG_ 944 AjarChrgLidRearSwitch 0;
BA_ "GenSigSendType" SG_ 832 BookChargeSetResponse 0;
BA_ "GenSigSendType" SG_ 880 BookChrgnTarValFb 0;
BA_ "GenSigStartValue" SG_ 880 BookChrgnTarValFb 1000;
BA_ "GenSigSendType" SG_ 880 BookTrvlHeatgStsFb 0;
BA_ "GenSigSendType" SG_ 880 BookTrvlPreHeatgFb 0;
BA_ "GenSigSendType" SG_ 832 BrkAndAbsWarnIndcnReqAbsWarnIndcnReq 0;
BA_ "GenSigStartValue" SG_ 832 BrkAndAbsWarnIndcnReqAbsWarnIndcnReq 3;
BA_ "GenSigSendType" SG_ 832 BrkAndAbsWarnIndcnReqBrkWarnIndcnReq 0;
BA_ "GenSigStartValue" SG_ 832 BrkAndAbsWarnIndcnReqBrkWarnIndcnReq 1;
BA_ "GenSigDataID" SG_ 832 BrkAndAbsWarnIndcnReqChks "0x65";
BA_ "GenSigFuncType" SG_ 832 BrkAndAbsWarnIndcnReqChks 15;
BA_ "GenSigSendType" SG_ 832 BrkAndAbsWarnIndcnReqChks 0;
BA_ "GenSigFuncType" SG_ 832 BrkAndAbsWarnIndcnReqCntr 16;
BA_ "GenSigSendType" SG_ 832 BrkAndAbsWarnIndcnReqCntr 0;
BA_ "GenSigSendType" SG_ 880 CarLoctrActvnSts 0;
BA_ "GenSigSendType" SG_ 48 CarTiGlb 0;
BA_ "GenSigSendType" SG_ 880 CdsParkgClimaActv 0;
BA_ "GenSigSendType" SG_ 800 ChrgnWarn 0;
BA_ "GenSigSendType" SG_ 272 ClimaActv 0;
BA_ "GenSigSendType" SG_ 880 ClimaOvrHeatProActv 0;
BA_ "GenSigSendType" SG_ 880 ClimaOvrHeatProActvSts 0;
BA_ "GenSigSendType" SG_ 672 ClimaOvrHeatProRspn 1;
BA_ "GenSigSendType" SG_ 672 ClimaOvrHeatProWarn 1;
BA_ "GenSigSendType" SG_ 672 ClsdDueToRain 1;
BA_ "GenSigSendType" SG_ 880 CmptmtRelHum 0;
BA_ "GenSigStartValue" SG_ 880 CmptmtRelHum 80;
BA_ "GenSigSendType" SG_ 944 DCChrgSt 0;
BA_ "GenSigSendType" SG_ 880 DchaChrgnTarValFb 0;
BA_ "GenSigStartValue" SG_ 880 DchaChrgnTarValFb 200;
BA_ "GenSigSendType" SG_ 880 DigKeyLogUploadSwt 0;
BA_ "GenSigStartValue" SG_ 880 DigKeyLogUploadSwt 1;
BA_ "GenSigSendType" SG_ 48 DoorDrvrLockSts 0;
BA_ "GenSigSendType" SG_ 48 DoorDrvrSts 0;
BA_ "GenSigSendType" SG_ 48 DoorLeReLockSts 0;
BA_ "GenSigSendType" SG_ 48 DoorLeReSts 0;
BA_ "GenSigSendType" SG_ 48 DoorPassLockSts 0;
BA_ "GenSigSendType" SG_ 48 DoorPassSts 0;
BA_ "GenSigSendType" SG_ 48 DoorRiReLockSts 0;
BA_ "GenSigSendType" SG_ 48 DoorRiReSts 0;
BA_ "GenSigSendType" SG_ 880 DrvrSeatHeatgAvlSts 0;
BA_ "GenSigSendType" SG_ 880 DrvrSeatHeatgLvlSts 0;
BA_ "GenSigSendType" SG_ 880 DrvrSeatVentAvlSts 0;
BA_ "GenSigSendType" SG_ 880 DrvrSeatVentnLvlSts 0;
BA_ "GenSigSendType" SG_ 968 DstTrvldHiResl 0;
BA_ "GenSigSendType" SG_ 968 DstTrvldMst2 0;
BA_ "GenSigSendType" SG_ 832 EngForbidRespFromVMM 0;
BA_ "GenSigSendType" SG_ 968 EngHrToSrv 0;
BA_ "GenSigStartValue" SG_ 968 EngTEngT 50;
BA_ "GenSigDataID" SG_ 968 EpbStsChks "0x84";
BA_ "GenSigFuncType" SG_ 968 EpbStsChks 15;
BA_ "GenSigSendType" SG_ 968 EpbStsChks 0;
BA_ "GenSigFuncType" SG_ 968 EpbStsCntr 16;
BA_ "GenSigSendType" SG_ 968 EpbStsCntr 0;
BA_ "GenSigSendType" SG_ 968 EpbStsEpbSts 0;
BA_ "GenSigDataID" SG_ 944 EscWarnIndcnReqChks "0x66";
BA_ "GenSigFuncType" SG_ 944 EscWarnIndcnReqChks 15;
BA_ "GenSigSendType" SG_ 944 EscWarnIndcnReqChks 0;
BA_ "GenSigFuncType" SG_ 944 EscWarnIndcnReqCntr 16;
BA_ "GenSigSendType" SG_ 944 EscWarnIndcnReqCntr 0;
BA_ "GenSigSendType" SG_ 944 EscWarnIndcnReqEscWarnIndcnReq 0;
BA_ "GenSigStartValue" SG_ 944 EscWarnIndcnReqEscWarnIndcnReq 3;
BA_ "GenSigSendType" SG_ 880 FragCh1Id 0;
BA_ "GenSigSendType" SG_ 880 FragCh1UseUpWrn 0;
BA_ "GenSigSendType" SG_ 880 FragCh2Id 0;
BA_ "GenSigSendType" SG_ 880 FragCh2UseUpWrn 0;
BA_ "GenSigSendType" SG_ 880 FragCh3Id 0;
BA_ "GenSigSendType" SG_ 880 FragCh3UseUpWrn 0;
BA_ "GenSigSendType" SG_ 880 FragCh4Id 0;
BA_ "GenSigSendType" SG_ 880 FragCh4UseUpWrn 0;
BA_ "GenSigSendType" SG_ 880 FragCh5Id 0;
BA_ "GenSigSendType" SG_ 880 FragCh5UseUpWrn 0;
BA_ "GenSigSendType" SG_ 880 FragLvlFrmClima 0;
BA_ "GenSigSendType" SG_ 880 FragStsFrmClima 0;
BA_ "GenSigStartValue" SG_ 880 FragStsFrmClima 1;
BA_ "GenSigSendType" SG_ 968 FuCnsAvgIndcdFuCnsIndcdUnit 0;
BA_ "GenSigSendType" SG_ 968 FuCnsAvgIndcdFuCnsIndcdVal 0;
BA_ "GenSigSendType" SG_ 968 FuCnsIndcdUnit 0;
BA_ "GenSigSendType" SG_ 968 FuCnsIndcdVal 0;
BA_ "GenSigSendType" SG_ 968 FuLvlIndcdFuLvlValFromFuTbl 0;
BA_ "GenSigSendType" SG_ 968 FuLvlIndcdGenQF 0;
BA_ "GenSigSendType" SG_ 968 FuLvlLoIndcn 0;
BA_ "GenSigSendType" SG_ 968 FuLvlLoWarn 0;
BA_ "GenSigSendType" SG_ 968 GidInfoInp1Byte0 0;
BA_ "GenSigStartValue" SG_ 968 GidInfoInp1Byte0 32;
BA_ "GenSigSendType" SG_ 968 GidInfoInp1Byte1 0;
BA_ "GenSigStartValue" SG_ 968 GidInfoInp1Byte1 32;
BA_ "GenSigSendType" SG_ 968 GidInfoInp1Byte2 0;
BA_ "GenSigStartValue" SG_ 968 GidInfoInp1Byte2 32;
BA_ "GenSigSendType" SG_ 968 GidInfoInp1Byte3 0;
BA_ "GenSigStartValue" SG_ 968 GidInfoInp1Byte3 32;
BA_ "GenSigSendType" SG_ 968 GidInfoInp1Byte4 0;
BA_ "GenSigStartValue" SG_ 968 GidInfoInp1Byte4 32;
BA_ "GenSigSendType" SG_ 968 GidInfoInp1Byte5 0;
BA_ "GenSigStartValue" SG_ 968 GidInfoInp1Byte5 32;
BA_ "GenSigSendType" SG_ 968 GidInfoInp1Byte6 0;
BA_ "GenSigStartValue" SG_ 968 GidInfoInp1Byte6 32;
BA_ "GenSigSendType" SG_ 968 GidInfoInp1Byte7 0;
BA_ "GenSigStartValue" SG_ 968 GidInfoInp1Byte7 32;
BA_ "GenSigSendType" SG_ 968 GidInfoInp2Byte0 0;
BA_ "GenSigStartValue" SG_ 968 GidInfoInp2Byte0 32;
BA_ "GenSigSendType" SG_ 968 GidInfoInp2Byte1 0;
BA_ "GenSigStartValue" SG_ 968 GidInfoInp2Byte1 32;
BA_ "GenSigSendType" SG_ 968 GidInfoInp2Byte2 0;
BA_ "GenSigStartValue" SG_ 968 GidInfoInp2Byte2 32;
BA_ "GenSigSendType" SG_ 968 GidInfoInp2Byte3 0;
BA_ "GenSigStartValue" SG_ 968 GidInfoInp2Byte3 32;
BA_ "GenSigSendType" SG_ 968 GidInfoInp2Byte4 0;
BA_ "GenSigStartValue" SG_ 968 GidInfoInp2Byte4 32;
BA_ "GenSigSendType" SG_ 968 GidInfoInp2Byte5 0;
BA_ "GenSigStartValue" SG_ 968 GidInfoInp2Byte5 32;
BA_ "GenSigSendType" SG_ 968 GidInfoInp2Byte6 0;
BA_ "GenSigStartValue" SG_ 968 GidInfoInp2Byte6 32;
BA_ "GenSigSendType" SG_ 968 GidInfoInp2Byte7 0;
BA_ "GenSigStartValue" SG_ 968 GidInfoInp2Byte7 32;
BA_ "GenSigSendType" SG_ 880 HmiCarLocatorSetReq 0;
BA_ "GenSigStartValue" SG_ 880 HmiCarLocatorSetReq 1;
BA_ "GenSigSendType" SG_ 272 HoodSts 0;
BA_ "GenSigSendType" SG_ 944 HvBattChrgnTiEstimd 0;
BA_ "GenSigStartValue" SG_ 944 HvBattChrgnTiEstimd 2047;
BA_ "GenSigSendType" SG_ 968 HvBattLimnIndcn 0;
BA_ "GenSigSendType" SG_ 968 HvBattSoc 0;
BA_ "GenSigSendType" SG_ 968 HvBattUDc 0;
BA_ "GenSigSendType" SG_ 880 HvCellTDifFlt 0;
BA_ "GenSigSendType" SG_ 880 HvCellUDifFlt 0;
BA_ "GenSigSendType" SG_ 880 HvCellUOverFlt 0;
BA_ "GenSigSendType" SG_ 880 HvCellUUnderFlt 0;
BA_ "GenSigSendType" SG_ 880 HvIsoFlt 0;
BA_ "GenSigSendType" SG_ 944 HvIsoR 0;
BA_ "GenSigStartValue" SG_ 944 HvIsoR 5000;
BA_ "GenSigSendType" SG_ 880 HvPackOverChrgFlt 0;
BA_ "GenSigSendType" SG_ 880 HvPackUOverFlt 0;
BA_ "GenSigSendType" SG_ 880 HvPackUUnderFlt 0;
BA_ "GenSigSendType" SG_ 880 HvSocHiFlt 0;
BA_ "GenSigSendType" SG_ 880 HvSocHopFlt 0;
BA_ "GenSigSendType" SG_ 880 HvSocLoFlt 0;
BA_ "GenSigSendType" SG_ 880 HvilFlt 0;
BA_ "GenSigSendType" SG_ 968 HybErrIndcnReqTelltlBattTracCutOff 0;
BA_ "GenSigSendType" SG_ 968 HybErrIndcnReqTelltlBattTracFailr 0;
BA_ "GenSigSendType" SG_ 968 HybErrIndcnReqTelltlElecDrvFailr 0;
BA_ "GenSigSendType" SG_ 968 HybErrIndcnReqTelltlSysHybFailr 0;
BA_ "GenSigStartValue" SG_ 944 IemGenericModStatusRms 3;
BA_ "GenSigSendType" SG_ 800 IgmGenericADAlrmSt 0;
BA_ "GenSigSendType" SG_ 800 IgmGenericDTCHig 0;
BA_ "GenSigSendType" SG_ 800 IgmGenericDTCLow 0;
BA_ "GenSigSendType" SG_ 800 IgmGenericDTCMid 0;
BA_ "GenSigSendType" SG_ 800 IgmGenericDTCSts 0;
BA_ "GenSigSendType" SG_ 800 IgmGenericEMQnty 0;
BA_ "GenSigSendType" SG_ 800 IgmGenericEMSeqNr 0;
BA_ "GenSigSendType" SG_ 800 IgmGenericFltAlrmSt 0;
BA_ "GenSigSendType" SG_ 800 IgmGenericIacAlrmSt 0;
BA_ "GenSigSendType" SG_ 800 IgmGenericInvrtTAlrmSt 0;
BA_ "GenSigSendType" SG_ 800 IgmGenericModStatusRms 0;
BA_ "GenSigStartValue" SG_ 800 IgmGenericModStatusRms 3;
BA_ "GenSigSendType" SG_ 800 IgmGenericMotTAlrmSt 0;
BA_ "GenSigSendType" SG_ 800 IgmGenericRslAlrmSt 0;
BA_ "GenSigSendType" SG_ 800 IgmGenericSpdAlrmSt 0;
BA_ "GenSigSendType" SG_ 800 IgmGenericTypeInfo 0;
BA_ "GenSigSendType" SG_ 800 IgmGenericUDcAlrmSt 0;
BA_ "GenSigSendType" SG_ 968 IndcnUnitClkFmt 0;
BA_ "GenSigSendType" SG_ 968 IndcnUnitDateFmt 0;
BA_ "GenSigSendType" SG_ 968 IndcnUnitDstLong 0;
BA_ "GenSigSendType" SG_ 968 IndcnUnitDstSho 0;
BA_ "GenSigSendType" SG_ 968 IndcnUnitFuCnsUnit 0;
BA_ "GenSigSendType" SG_ 968 IndcnUnitPUnit 0;
BA_ "GenSigSendType" SG_ 968 IndcnUnitSpdUnit 0;
BA_ "GenSigSendType" SG_ 968 IndcnUnitTUnit 0;
BA_ "GenSigSendType" SG_ 968 IndcnUnitVolUnit 0;
BA_ "GenSigSendType" SG_ 944 IntPm25LvlFrmClima 0;
BA_ "GenSigSendType" SG_ 880 IntPm25StsFrmClima 0;
BA_ "GenSigSendType" SG_ 944 IntPm25VluFrmClima 0;
BA_ "GenSigSendType" SG_ 800 IsgIDc 0;
BA_ "GenSigStartValue" SG_ 800 IsgIDc 8188;
BA_ "GenSigSendType" SG_ 800 IsgInvrT 0;
BA_ "GenSigStartValue" SG_ 800 IsgInvrT 50;
BA_ "GenSigSendType" SG_ 800 IsgMotT 0;
BA_ "GenSigStartValue" SG_ 800 IsgMotT 50;
BA_ "GenSigSendType" SG_ 800 IsgSpdActSgn 0;
BA_ "GenSigDataID" SG_ 968 IsgTqActChks "0x46";
BA_ "GenSigFuncType" SG_ 968 IsgTqActChks 15;
BA_ "GenSigSendType" SG_ 968 IsgTqActChks 0;
BA_ "GenSigFuncType" SG_ 968 IsgTqActCntr 16;
BA_ "GenSigSendType" SG_ 968 IsgTqActCntr 0;
BA_ "GenSigSendType" SG_ 968 IsgTqActIsgTqAct 0;
BA_ "GenSigStartValue" SG_ 968 IsgTqActIsgTqAct 8188;
BA_ "GenSigSendType" SG_ 968 IsgTqActQualityFactor 0;
BA_ "GenSigStartValue" SG_ 968 IsgTqActQualityFactor 1;
BA_ "GenSigSendType" SG_ 968 IsgUDc 0;
BA_ "GenSigSendType" SG_ 880 KeyIntrVldDetd 0;
BA_ "GenSigSendType" SG_ 880 LiBattInPWLockTC 0;
BA_ "GenSigSendType" SG_ 968 LimnIndcnDcDc 0;
BA_ "GenSigSendType" SG_ 1008 LocalBookChrgnTarVal 1;
BA_ "GenSigSendType" SG_ 800 LockgCenStsForUsrFb 0;
BA_ "GenSigSendType" SG_ 48 LockgCenStsLockSt 0;
BA_ "GenSigSendType" SG_ 48 LockgCenStsTrigSrc 0;
BA_ "GenSigSendType" SG_ 48 LockgCenStsUpdEve 0;
BA_ "GenSigSendType" SG_ 1008 MaxAcInpCurrentSet 1;
BA_ "GenSigSendType" SG_ 832 NetDHUActvt 0;
BA_ "GenSigSendType" SG_ 832 NotifForEmgyCall 0;
BA_ "GenSigSendType" SG_ 976 OTAMod 0;
BA_ "GenSigSendType" SG_ 944 OnBdChrgrHndlSts1 0;
BA_ "GenSigStartValue" SG_ 944 OnBdChrgrHndlSts1 8;
BA_ "GenSigSendType" SG_ 944 OnBdChrgrIAct 0;
BA_ "GenSigStartValue" SG_ 944 OnBdChrgrIAct 2000;
BA_ "GenSigSendType" SG_ 944 OnBdChrgrPwrEnaAllwd 0;
BA_ "GenSigSendType" SG_ 944 OnBdChrgrSt 0;
BA_ "GenSigSendType" SG_ 944 OnBdChrgrUAct 0;
BA_ "GenSigSendType" SG_ 880 OutdPm25LvlFrmClima 0;
BA_ "GenSigSendType" SG_ 880 OutdPm25VluFrmClima 0;
BA_ "GenSigSendType" SG_ 880 PassSeatHeatgAvlSts 0;
BA_ "GenSigSendType" SG_ 880 PassSeatHeatgLvlSts 0;
BA_ "GenSigSendType" SG_ 832 PassSeatSnsrSts2 0;
BA_ "GenSigSendType" SG_ 832 PassSeatSts2 0;
BA_ "GenSigStartValue" SG_ 832 PassSeatSts2 1;
BA_ "GenSigSendType" SG_ 880 PassSeatVentAvlSts 0;
BA_ "GenSigSendType" SG_ 880 PassSeatVentnLvlSts 0;
BA_ "GenSigSendType" SG_ 976 PrkgCameraRes 0;
BA_ "GenSigSendType" SG_ 976 PrkgCameraSwt 0;
BA_ "GenSigSendType" SG_ 880 PrkgClimaWarn 0;
BA_ "GenSigSendType" SG_ 968 PwrCnsAvgIndcd1EcoDrvInfo1 0;
BA_ "GenSigSendType" SG_ 968 PwrCnsAvgIndcd1PwrCnsUnit 0;
BA_ "GenSigSendType" SG_ 968 PwrCnsAvgIndcdEcoDrvInfo1 0;
BA_ "GenSigSendType" SG_ 968 PwrCnsAvgIndcdPwrCnsUnit 0;
BA_ "GenSigSendType" SG_ 968 PwrCnsIndcdCnsUnit 0;
BA_ "GenSigSendType" SG_ 968 PwrCnsIndcdPwrCnsIn 0;
BA_ "GenSigStartValue" SG_ 968 PwrCnsIndcdPwrCnsIn 1000;
BA_ "GenSigSendType" SG_ 48 RecOfImpct2ImpctDvxSigned 0;
BA_ "GenSigStartValue" SG_ 48 RecOfImpct2ImpctDvxSigned 255;
BA_ "GenSigSendType" SG_ 48 RecOfImpct2ImpctDvySigned 0;
BA_ "GenSigStartValue" SG_ 48 RecOfImpct2ImpctDvySigned 255;
BA_ "GenSigSendType" SG_ 48 RecOfImpctCrashFrnt 0;
BA_ "GenSigSendType" SG_ 48 RecOfImpctCrashOffroadA 0;
BA_ "GenSigSendType" SG_ 48 RecOfImpctCrashOffroadD 0;
BA_ "GenSigSendType" SG_ 48 RecOfImpctCrashOffroadRT 0;
BA_ "GenSigSendType" SG_ 48 RecOfImpctCrashOffroadRTsevere 0;
BA_ "GenSigSendType" SG_ 48 RecOfImpctCrashPed 0;
BA_ "GenSigSendType" SG_ 48 RecOfImpctCrashRe 0;
BA_ "GenSigSendType" SG_ 48 RecOfImpctCrashRollovr 0;
BA_ "GenSigSendType" SG_ 48 RecOfImpctCrashSideLe 0;
BA_ "GenSigSendType" SG_ 48 RecOfImpctCrashSideRi 0;
BA_ "GenSigSendType" SG_ 48 RecOfImpctCrashState 0;
BA_ "GenSigSendType" SG_ 48 RecOfImpctImpctDvx 0;
BA_ "GenSigSendType" SG_ 48 RecOfImpctImpctDvy 0;
BA_ "GenSigSendType" SG_ 48 RecOfImpctImpctRollAg 0;
BA_ "GenSigSendType" SG_ 48 RecOfImpctVehOri 0;
BA_ "GenSigStartValue" SG_ 48 RecOfImpctVehOri 4;
BA_ "GenSigSendType" SG_ 880 RelHumSnsrRelHum 0;
BA_ "GenSigStartValue" SG_ 880 RelHumSnsrRelHum 80;
BA_ "GenSigSendType" SG_ 944 RemAllowStrt 0;
BA_ "GenSigSendType" SG_ 880 RemClimaActv 0;
BA_ "GenSigSendType" SG_ 880 RemClimaDefrstSts 0;
BA_ "GenSigSendType" SG_ 880 RemClimaDelaySts 1;
BA_ "GenSigSendType" SG_ 880 RemClimaExtnTiRspn 1;
BA_ "GenSigSendType" SG_ 880 RemClimaHvRspn 1;
BA_ "GenSigSendType" SG_ 880 RemClimaHvSts 0;
BA_ "GenSigSendType" SG_ 880 RemClimaWarn 1;
BA_ "GenSigSendType" SG_ 880 RemStrtClimaRspn 1;
BA_ "GenSigSendType" SG_ 880 RemVentActvSts 0;
BA_ "GenSigSendType" SG_ 880 RemVentReqRspnFb 0;
BA_ "GenSigSendType" SG_ 880 RemVentWarnSts 0;
BA_ "GenSigSendType" SG_ 672 SchedCmptHeatCoolFB 1;
BA_ "GenSigSendType" SG_ 968 SrvTrig 0;
BA_ "GenSigSendType" SG_ 880 SteerWhlHeatgAvlSts 0;
BA_ "GenSigSendType" SG_ 880 SunCurtImpctDetnSts2 0;
BA_ "GenSigSendType" SG_ 880 SunCurtMvngSts 0;
BA_ "GenSigSendType" SG_ 880 SunCurtPosnSts 0;
BA_ "GenSigSendType" SG_ 880 SunRoofAndCurtFailrCurtMotFailr 0;
BA_ "GenSigSendType" SG_ 880 SunRoofAndCurtFailrCurtMotHallFailr 0;
BA_ "GenSigSendType" SG_ 880 SunRoofAndCurtFailrCurtMotNotAvl 0;
BA_ "GenSigSendType" SG_ 880 SunRoofAndCurtFailrEcuFailrGen 0;
BA_ "GenSigSendType" SG_ 880 SunRoofAndCurtFailrPanMotFailr 0;
BA_ "GenSigSendType" SG_ 880 SunRoofAndCurtFailrPanMotHallFailr 0;
BA_ "GenSigSendType" SG_ 880 SunRoofAndCurtFailrPanMotNotAvl 0;
BA_ "GenSigSendType" SG_ 880 SunRoofAndCurtFailrResvd 0;
BA_ "GenSigSendType" SG_ 880 SunRoofMvngSts 0;
BA_ "GenSigSendType" SG_ 272 SunRoofPosnSts 0;
BA_ "GenSigSendType" SG_ 832 TCSDoorNoClsSts 0;
BA_ "GenSigSendType" SG_ 880 TankFlapSts 0;
BA_ "GenSigSendType" SG_ 48 TrLockSts 0;
BA_ "GenSigSendType" SG_ 832 TrOpenerByFootOperCmd 0;
BA_ "GenSigSendType" SG_ 48 TrSts 0;
BA_ "GenSigSendType" SG_ 341 TripResetSyncMsgAuthenticator 1;
BA_ "GenSigSendType" SG_ 341 TripResetSyncMsgResetcounter 1;
BA_ "GenSigStartValue" SG_ 341 TripResetSyncMsgResetcounter 1;
BA_ "GenSigSendType" SG_ 341 TripResetSyncMsgTripcounter 1;
BA_ "GenSigStartValue" SG_ 341 TripResetSyncMsgTripcounter 1;
BA_ "GenSigDataID" SG_ 832 TrsmParkLockdChks "0x32";
BA_ "GenSigFuncType" SG_ 832 TrsmParkLockdChks 15;
BA_ "GenSigSendType" SG_ 832 TrsmParkLockdChks 0;
BA_ "GenSigFuncType" SG_ 832 TrsmParkLockdCntr 16;
BA_ "GenSigSendType" SG_ 832 TrsmParkLockdCntr 0;
BA_ "GenSigSendType" SG_ 832 TrsmParkLockdTrsmParkLockd 0;
BA_ "GenSigStartValue" SG_ 832 TrsmParkLockdTrsmParkLockd 3;
BA_ "GenSigSendType" SG_ 968 VehBattUSysU 0;
BA_ "GenSigSendType" SG_ 968 VehBattUSysUQf 0;
BA_ "GenSigStartValue" SG_ 968 VehBattUSysUQf 1;
BA_ "GenSigSendType" SG_ 672 VehCfgPrmBlkIDBytePosn1 1;
BA_ "GenSigSendType" SG_ 672 VehCfgPrmCCPBytePosn2 1;
BA_ "GenSigSendType" SG_ 672 VehCfgPrmCCPBytePosn3 1;
BA_ "GenSigSendType" SG_ 672 VehCfgPrmCCPBytePosn4 1;
BA_ "GenSigSendType" SG_ 672 VehCfgPrmCCPBytePosn5 1;
BA_ "GenSigSendType" SG_ 672 VehCfgPrmCCPBytePosn6 1;
BA_ "GenSigSendType" SG_ 672 VehCfgPrmCCPBytePosn7 1;
BA_ "GenSigSendType" SG_ 672 VehCfgPrmCCPBytePosn8 1;
BA_ "GenSigSendType" SG_ 672 VehCfgPrmExtBlkIDBytePosn1 1;
BA_ "GenSigSendType" SG_ 672 VehCfgPrmExtCCPBytePosn2 1;
BA_ "GenSigSendType" SG_ 672 VehCfgPrmExtCCPBytePosn3 1;
BA_ "GenSigSendType" SG_ 672 VehCfgPrmExtCCPBytePosn4 1;
BA_ "GenSigSendType" SG_ 672 VehCfgPrmExtCCPBytePosn5 1;
BA_ "GenSigSendType" SG_ 672 VehCfgPrmExtCCPBytePosn6 1;
BA_ "GenSigSendType" SG_ 672 VehCfgPrmExtCCPBytePosn7 1;
BA_ "GenSigSendType" SG_ 672 VehCfgPrmExtCCPBytePosn8 1;
BA_ "GenSigDataID" SG_ 832 VehMtnStChks "0x36";
BA_ "GenSigFuncType" SG_ 832 VehMtnStChks 15;
BA_ "GenSigSendType" SG_ 832 VehMtnStChks 0;
BA_ "GenSigFuncType" SG_ 832 VehMtnStCntr 16;
BA_ "GenSigSendType" SG_ 832 VehMtnStCntr 0;
BA_ "GenSigSendType" SG_ 832 VehMtnStVehMtnSt 0;
BA_ "GenSigSendType" SG_ 968 VehSpdAvgIndcdVeSpdIndcdUnit 0;
BA_ "GenSigSendType" SG_ 968 VehSpdAvgIndcdVehSpdIndcd 0;
BA_ "GenSigSendType" SG_ 968 VehSpdIndcdQly 0;
BA_ "GenSigSendType" SG_ 968 VehSpdIndcdVeSpdIndcdUnit 0;
BA_ "GenSigSendType" SG_ 968 VehSpdIndcdVehSpdIndcd 0;
BA_ "GenSigSendType" SG_ 976 VehTiAndDataDataValid 0;
BA_ "GenSigSendType" SG_ 976 VehTiAndDataDay 0;
BA_ "GenSigStartValue" SG_ 976 VehTiAndDataDay 1;
BA_ "GenSigSendType" SG_ 976 VehTiAndDataHr1 0;
BA_ "GenSigSendType" SG_ 976 VehTiAndDataMins1 0;
BA_ "GenSigSendType" SG_ 976 VehTiAndDataMth1 0;
BA_ "GenSigStartValue" SG_ 976 VehTiAndDataMth1 1;
BA_ "GenSigSendType" SG_ 976 VehTiAndDataSec1 0;
BA_ "GenSigSendType" SG_ 976 VehTiAndDataYr1 0;
BA_ "GenSigSendType" SG_ 672 VinBlockNr 1;
BA_ "GenSigSendType" SG_ 672 VinVINSignalPos1 1;
BA_ "GenSigSendType" SG_ 672 VinVINSignalPos2 1;
BA_ "GenSigSendType" SG_ 672 VinVINSignalPos3 1;
BA_ "GenSigSendType" SG_ 672 VinVINSignalPos4 1;
BA_ "GenSigSendType" SG_ 672 VinVINSignalPos5 1;
BA_ "GenSigSendType" SG_ 672 VinVINSignalPos6 1;
BA_ "GenSigSendType" SG_ 672 VinVINSignalPos7 1;
BA_ "GenSigSendType" SG_ 1281 WakeUpReasonsforDHU 0;
BA_ "GenSigStartValue" SG_ 976 WhlMotSysIdc 8188;
BA_ "GenSigStartValue" SG_ 880 WhlMotSysInvrT 50;
BA_ "GenSigStartValue" SG_ 880 WhlMotSysMotT 50;
BA_ "GenSigStartValue" SG_ 968 WhlMotSysTqEstIsgTqAct 8188;
BA_ "GenSigStartValue" SG_ 968 WhlMotSysTqEstQualityFactor 1;
BA_ "GenSigSendType" SG_ 880 WinFailrStsAtPass 0;
BA_ "GenSigSendType" SG_ 880 WinFailrStsAtReRi 0;
BA_ "GenSigSendType" SG_ 272 WinPosnStsAtDrvr 0;
BA_ "GenSigSendType" SG_ 272 WinPosnStsAtPass 0;
BA_ "GenSigSendType" SG_ 272 WinPosnStsAtReLe 0;
BA_ "GenSigSendType" SG_ 272 WinPosnStsAtReRi 0;
BA_ "GenSigSendType" SG_ 832 WirelsChrgFrntLeSwt 0;
BA_ "GenSigSendType" SG_ 832 WirelsChrgFrntRiSwt 0;
BA_ "GenSigSendType" SG_ 944 WirelschrgActvReqFromHmi 0;
VAL_ 880 BookTrvlHeatgStsFb 0 "BookTrvlHeatgStsFb_Default" 1 "BookTrvlHeatgStsFb_Heating" 2 "BookTrvlHeatgStsFb_HeatFinished" 3 "BookTrvlHeatgStsFb_HeatTerminated" 4 "BookTrvlHeatgStsFb_Fault";
VAL_ 880 BookTrvlPreHeatgFb 0 "BookChargeSetResponse_Default" 1 "BookChargeSetResponse_Success" 2 "BookChargeSetResponse_Cancelled" 3 "BookChargeSetResponse_Fail";
VAL_ 880 CarLoctrActvnSts 0 "ActvnWithMsg_Idle" 1 "ActvnWithMsg_Activation_Successful" 2 "ActvnWithMsg_Activation_Fail";
VAL_ 880 CdsParkgClimaActv 0 "OnOff1_Off" 1 "OnOff1_On";
VAL_ 880 ClimaOvrHeatProActv 0 "OnOff1_Off" 1 "OnOff1_On";
VAL_ 880 ClimaOvrHeatProActvSts 0 "OnOff1_Off" 1 "OnOff1_On";
VAL_ 880 DigKeyLogUploadSwt 0 "OnOff1_Off" 1 "OnOff1_On";
VAL_ 880 DrvrSeatHeatgAvlSts 0 "StsFd_None" 1 "StsFd_On" 2 "StsFd_Off" 3 "StsFd_Error" 4 "StsFd_Functionallimit" 5 "StsFd_Energylimit" 6 "StsFd_Resvd1" 7 "StsFd_Resvd2";
VAL_ 880 DrvrSeatHeatgLvlSts 0 "SeatClimaLvl_Off" 1 "SeatClimaLvl_Lvl1" 2 "SeatClimaLvl_Lvl2" 3 "SeatClimaLvl_Lvl3";
VAL_ 880 DrvrSeatVentAvlSts 0 "StsFd_None" 1 "StsFd_On" 2 "StsFd_Off" 3 "StsFd_Error" 4 "StsFd_Functionallimit" 5 "StsFd_Energylimit" 6 "StsFd_Resvd1" 7 "StsFd_Resvd2";
VAL_ 880 DrvrSeatVentnLvlSts 0 "SeatClimaLvl_Off" 1 "SeatClimaLvl_Lvl1" 2 "SeatClimaLvl_Lvl2" 3 "SeatClimaLvl_Lvl3";
VAL_ 880 FragCh1UseUpWrn 0 "Warn2_NoWarn" 1 "Warn2_Warn";
VAL_ 880 FragCh2UseUpWrn 0 "Warn2_NoWarn" 1 "Warn2_Warn";
VAL_ 880 FragCh3UseUpWrn 0 "Warn2_NoWarn" 1 "Warn2_Warn";
VAL_ 880 FragCh4UseUpWrn 0 "Warn2_NoWarn" 1 "Warn2_Warn";
VAL_ 880 FragCh5UseUpWrn 0 "Warn2_NoWarn" 1 "Warn2_Warn";
VAL_ 880 FragLvlFrmClima 0 "RatUse_NoRequest" 1 "RatUse_Low" 2 "RatUse_Mid" 3 "RatUse_High";
VAL_ 880 FragStsFrmClima 1 "AirFragSts_OFF" 2 "AirFragSts_ON" 3 "AirFragSts_Error";
VAL_ 880 HmiCarLocatorSetReq 0 "OnOff1_Off" 1 "OnOff1_On";
VAL_ 880 HvCellTDifFlt 0 "FauLevel_Normal" 1 "FauLevel_LevelI" 2 "FauLevel_LevelII" 3 "FauLevel_LevelIII";
VAL_ 880 HvCellUDifFlt 0 "FauLevel_Normal" 1 "FauLevel_LevelI" 2 "FauLevel_LevelII" 3 "FauLevel_LevelIII";
VAL_ 880 HvCellUOverFlt 0 "FauLevel_Normal" 1 "FauLevel_LevelI" 2 "FauLevel_LevelII" 3 "FauLevel_LevelIII";
VAL_ 880 HvCellUUnderFlt 0 "FauLevel_Normal" 1 "FauLevel_LevelI" 2 "FauLevel_LevelII" 3 "FauLevel_LevelIII";
VAL_ 880 HvilFlt 0 "DevErrSts2_NoFlt" 1 "DevErrSts2_Flt";
VAL_ 880 HvIsoFlt 0 "FauLevel_Normal" 1 "FauLevel_LevelI" 2 "FauLevel_LevelII" 3 "FauLevel_LevelIII";
VAL_ 880 HvPackOverChrgFlt 0 "FauLevel_Normal" 1 "FauLevel_LevelI" 2 "FauLevel_LevelII" 3 "FauLevel_LevelIII";
VAL_ 880 HvPackUOverFlt 0 "FauLevel_Normal" 1 "FauLevel_LevelI" 2 "FauLevel_LevelII" 3 "FauLevel_LevelIII";
VAL_ 880 HvPackUUnderFlt 0 "FauLevel_Normal" 1 "FauLevel_LevelI" 2 "FauLevel_LevelII" 3 "FauLevel_LevelIII";
VAL_ 880 HvSocHiFlt 0 "FauLevel_Normal" 1 "FauLevel_LevelI" 2 "FauLevel_LevelII" 3 "FauLevel_LevelIII";
VAL_ 880 HvSocHopFlt 0 "FauLevel_Normal" 1 "FauLevel_LevelI" 2 "FauLevel_LevelII" 3 "FauLevel_LevelIII";
VAL_ 880 HvSocLoFlt 0 "FauLevel_Normal" 1 "FauLevel_LevelI" 2 "FauLevel_LevelII" 3 "FauLevel_LevelIII";
VAL_ 880 IntPm25StsFrmClima 0 "PmSnsrSts_Initial" 1 "PmSnsrSts_Collecting" 2 "PmSnsrSts_Complete" 3 "PmSnsrSts_Error";
VAL_ 880 KeyIntrVldDetd 0 "Boolean_FALSE" 1 "Boolean_TRUE";
VAL_ 880 LiBattInPWLockTC 0 "OnOff1_Off" 1 "OnOff1_On";
VAL_ 880 OutdPm25LvlFrmClima 0 "CmpmtAirPmLvl_Level1" 1 "CmpmtAirPmLvl_Level2" 2 "CmpmtAirPmLvl_Level3" 3 "CmpmtAirPmLvl_Level4" 4 "CmpmtAirPmLvl_Level5" 5 "CmpmtAirPmLvl_Level6" 6 "CmpmtAirPmLvl_Reserved" 7 "CmpmtAirPmLvl_Invalid";
VAL_ 880 PassSeatHeatgAvlSts 0 "StsFd_None" 1 "StsFd_On" 2 "StsFd_Off" 3 "StsFd_Error" 4 "StsFd_Functionallimit" 5 "StsFd_Energylimit" 6 "StsFd_Resvd1" 7 "StsFd_Resvd2";
VAL_ 880 PassSeatHeatgLvlSts 0 "SeatClimaLvl_Off" 1 "SeatClimaLvl_Lvl1" 2 "SeatClimaLvl_Lvl2" 3 "SeatClimaLvl_Lvl3";
VAL_ 880 PassSeatVentAvlSts 0 "StsFd_None" 1 "StsFd_On" 2 "StsFd_Off" 3 "StsFd_Error" 4 "StsFd_Functionallimit" 5 "StsFd_Energylimit" 6 "StsFd_Resvd1" 7 "StsFd_Resvd2";
VAL_ 880 PassSeatVentnLvlSts 0 "SeatClimaLvl_Off" 1 "SeatClimaLvl_Lvl1" 2 "SeatClimaLvl_Lvl2" 3 "SeatClimaLvl_Lvl3";
VAL_ 880 PrkgClimaWarn 0 "ClimaWarn_NoWarn" 1 "ClimaWarn_FuLo" 2 "ClimaWarn_BattLo" 3 "ClimaWarn_FuAndBattLo" 4 "ClimaWarn_TLo" 5 "ClimaWarn_THi" 6 "ClimaWarn_Error" 7 "ClimaWarn_HVError" 8 "ClimaWarn_ActvnLimd";
VAL_ 880 RemClimaActv 0 "OnOff1_Off" 1 "OnOff1_On";
VAL_ 880 RemClimaDefrstSts 0 "OnOff1_Off" 1 "OnOff1_On";
VAL_ 880 RemClimaDelaySts 0 "OnOff1_Off" 1 "OnOff1_On";
VAL_ 880 RemClimaExtnTiRspn 0 "OnOff1_Off" 1 "OnOff1_On";
VAL_ 880 RemClimaHvRspn 0 "OnOff1_Off" 1 "OnOff1_On";
VAL_ 880 RemClimaHvSts 0 "OnOff1_Off" 1 "OnOff1_On";
VAL_ 880 RemClimaWarn 0 "ClimaWarn_NoWarn" 1 "ClimaWarn_FuLo" 2 "ClimaWarn_BattLo" 3 "ClimaWarn_FuAndBattLo" 4 "ClimaWarn_TLo" 5 "ClimaWarn_THi" 6 "ClimaWarn_Error" 7 "ClimaWarn_HVError" 8 "ClimaWarn_ActvnLimd";
VAL_ 880 RemStrtClimaRspn 0 "OnOff1_Off" 1 "OnOff1_On";
VAL_ 880 RemVentActvSts 0 "OnOff1_Off" 1 "OnOff1_On";
VAL_ 880 RemVentReqRspnFb 0 "OnOff1_Off" 1 "OnOff1_On";
VAL_ 880 RemVentWarnSts 0 "RemVentWarningSts_NoErr" 1 "RemVentWarningSts_Err" 2 "RemVentWarningSts_PwrNotAllwd" 3 "RemVentWarningSts_EgyNotAllwd";
VAL_ 880 SteerWhlHeatgAvlSts 0 "StsFd_None" 1 "StsFd_On" 2 "StsFd_Off" 3 "StsFd_Error" 4 "StsFd_Functionallimit" 5 "StsFd_Energylimit" 6 "StsFd_Resvd1" 7 "StsFd_Resvd2";
VAL_ 880 SunCurtImpctDetnSts2 0 "SunRoofAndCurtImpctDetnStsTyp_ImpctDetnDi" 1 "SunRoofAndCurtImpctDetnStsTyp_ImpctDetnEna" 2 "SunRoofAndCurtImpctDetnStsTyp_ClsPinch" 3 "SunRoofAndCurtImpctDetnStsTyp_ClsBlk" 4 "SunRoofAndCurtImpctDetnStsTyp_OpenPinch" 5 "SunRoofAndCurtImpctDetnStsTyp_OpenBlk";
VAL_ 880 SunCurtMvngSts 0 "Boolean_FALSE" 1 "Boolean_TRUE";
VAL_ 880 SunCurtPosnSts 0 "WinAndRoofAndCurtPosnTyp_PosnUkwn" 1 "WinAndRoofAndCurtPosnTyp_ClsFull" 2 "WinAndRoofAndCurtPosnTyp_PercOpen4" 3 "WinAndRoofAndCurtPosnTyp_PercOpen8" 4 "WinAndRoofAndCurtPosnTyp_PercOpen12" 5 "WinAndRoofAndCurtPosnTyp_PercOpen16" 6 "WinAndRoofAndCurtPosnTyp_PercOpen20" 7 "WinAndRoofAndCurtPosnTyp_PercOpen24" 8 "WinAndRoofAndCurtPosnTyp_PercOpen28" 9 "WinAndRoofAndCurtPosnTyp_PercOpen32" 10 "WinAndRoofAndCurtPosnTyp_PercOpen36" 11 "WinAndRoofAndCurtPosnTyp_PercOpen40" 12 "WinAndRoofAndCurtPosnTyp_PercOpen44" 13 "WinAndRoofAndCurtPosnTyp_PercOpen48" 14 "WinAndRoofAndCurtPosnTyp_PercOpen52" 15 "WinAndRoofAndCurtPosnTyp_PercOpen56" 16 "WinAndRoofAndCurtPosnTyp_PercOpen60" 17 "WinAndRoofAndCurtPosnTyp_PercOpen64" 18 "WinAndRoofAndCurtPosnTyp_PercOpen68" 19 "WinAndRoofAndCurtPosnTyp_PercOpen72" 20 "WinAndRoofAndCurtPosnTyp_PercOpen76" 21 "WinAndRoofAndCurtPosnTyp_PercOpen80" 22 "WinAndRoofAndCurtPosnTyp_PercOpen84" 23 "WinAndRoofAndCurtPosnTyp_PercOpen88" 24 "WinAndRoofAndCurtPosnTyp_PercOpen92" 25 "WinAndRoofAndCurtPosnTyp_PercOpen96" 26 "WinAndRoofAndCurtPosnTyp_OpenFull" 27 "WinAndRoofAndCurtPosnTyp_Resd1" 28 "WinAndRoofAndCurtPosnTyp_Resd2" 29 "WinAndRoofAndCurtPosnTyp_Resd3" 30 "WinAndRoofAndCurtPosnTyp_Resd4" 31 "WinAndRoofAndCurtPosnTyp_Movg";
VAL_ 880 SunRoofAndCurtFailrCurtMotFailr 0 "Boolean_FALSE" 1 "Boolean_TRUE";
VAL_ 880 SunRoofAndCurtFailrCurtMotHallFailr 0 "Boolean_FALSE" 1 "Boolean_TRUE";
VAL_ 880 SunRoofAndCurtFailrCurtMotNotAvl 0 "Boolean_FALSE" 1 "Boolean_TRUE";
VAL_ 880 SunRoofAndCurtFailrEcuFailrGen 0 "Boolean_FALSE" 1 "Boolean_TRUE";
VAL_ 880 SunRoofAndCurtFailrPanMotFailr 0 "Boolean_FALSE" 1 "Boolean_TRUE";
VAL_ 880 SunRoofAndCurtFailrPanMotHallFailr 0 "Boolean_FALSE" 1 "Boolean_TRUE";
VAL_ 880 SunRoofAndCurtFailrPanMotNotAvl 0 "Boolean_FALSE" 1 "Boolean_TRUE";
VAL_ 880 SunRoofAndCurtFailrResvd 0 "Boolean_FALSE" 1 "Boolean_TRUE";
VAL_ 880 SunRoofMvngSts 0 "Boolean_FALSE" 1 "Boolean_TRUE";
VAL_ 880 TankFlapSts 0 "DoorSts2_Ukwn" 1 "DoorSts2_Opend" 2 "DoorSts2_Clsd";
VAL_ 880 WinFailrStsAtPass 0 "Flt_NoFault" 1 "Flt_Fault";
VAL_ 880 WinFailrStsAtReRi 0 "Flt_NoFault" 1 "Flt_Fault";
VAL_ 672 ClimaOvrHeatProRspn 0 "OnOff1_Off" 1 "OnOff1_On";
VAL_ 672 ClimaOvrHeatProWarn 0 "ClimaOvrheatProWarnSts_NoWarn" 1 "ClimaOvrheatProWarnSts_Err" 2 "ClimaOvrheatProWarnSts_PwrLo" 3 "ClimaOvrheatProWarnSts_Tout";
VAL_ 672 ClsdDueToRain 0 "Boolean_FALSE" 1 "Boolean_TRUE";
VAL_ 672 SchedCmptHeatCoolFB 0 "SchedCmptHeatCoolFB_NoReq" 1 "SchedCmptHeatCoolFB_ON" 2 "SchedCmptHeatCoolFB_OFF" 3 "SchedCmptHeatCoolFB_Reserved";
VAL_ 48 DoorDrvrLockSts 0 "LockSts2_LockStsUkwn" 1 "LockSts2_Unlckd" 2 "LockSts2_Lockd" 3 "LockSts2_SafeLockd";
VAL_ 48 DoorDrvrSts 0 "DoorSts2_Ukwn" 1 "DoorSts2_Opend" 2 "DoorSts2_Clsd";
VAL_ 48 DoorLeReLockSts 0 "LockSts2_LockStsUkwn" 1 "LockSts2_Unlckd" 2 "LockSts2_Lockd" 3 "LockSts2_SafeLockd";
VAL_ 48 DoorLeReSts 0 "DoorSts2_Ukwn" 1 "DoorSts2_Opend" 2 "DoorSts2_Clsd";
VAL_ 48 DoorPassLockSts 0 "LockSts2_LockStsUkwn" 1 "LockSts2_Unlckd" 2 "LockSts2_Lockd" 3 "LockSts2_SafeLockd";
VAL_ 48 DoorPassSts 0 "DoorSts2_Ukwn" 1 "DoorSts2_Opend" 2 "DoorSts2_Clsd";
VAL_ 48 DoorRiReLockSts 0 "LockSts2_LockStsUkwn" 1 "LockSts2_Unlckd" 2 "LockSts2_Lockd" 3 "LockSts2_SafeLockd";
VAL_ 48 DoorRiReSts 0 "DoorSts2_Ukwn" 1 "DoorSts2_Opend" 2 "DoorSts2_Clsd";
VAL_ 48 LockgCenStsLockSt 0 "LockSt3_LockUndefd" 1 "LockSt3_LockUnlckd" 2 "LockSt3_LockTrUnlckd" 3 "LockSt3_LockLockd";
VAL_ 48 LockgCenStsTrigSrc 0 "LockTrigSrc2_NoTrigSrc" 1 "LockTrigSrc2_KeyRem" 2 "LockTrigSrc2_Keyls" 3 "LockTrigSrc2_IntrSwt" 4 "LockTrigSrc2_SpdAut" 5 "LockTrigSrc2_TmrAut" 6 "LockTrigSrc2_Slam" 7 "LockTrigSrc2_Telm" 8 "LockTrigSrc2_Crash" 9 "LockTrigSrc2_Apprch" 10 "LockTrigSrc2_OutsOth" 11 "LockTrigSrc2_InsOth";
VAL_ 48 LockgCenStsUpdEve 0 "Boolean_FALSE" 1 "Boolean_TRUE";
VAL_ 48 RecOfImpctCrashFrnt 0 "Boolean_FALSE" 1 "Boolean_TRUE";
VAL_ 48 RecOfImpctCrashOffroadA 0 "Boolean_FALSE" 1 "Boolean_TRUE";
VAL_ 48 RecOfImpctCrashOffroadD 0 "Boolean_FALSE" 1 "Boolean_TRUE";
VAL_ 48 RecOfImpctCrashOffroadRT 0 "Boolean_FALSE" 1 "Boolean_TRUE";
VAL_ 48 RecOfImpctCrashOffroadRTsevere 0 "Boolean_FALSE" 1 "Boolean_TRUE";
VAL_ 48 RecOfImpctCrashPed 0 "Boolean_FALSE" 1 "Boolean_TRUE";
VAL_ 48 RecOfImpctCrashRe 0 "Boolean_FALSE" 1 "Boolean_TRUE";
VAL_ 48 RecOfImpctCrashRollovr 0 "Boolean_FALSE" 1 "Boolean_TRUE";
VAL_ 48 RecOfImpctCrashSideLe 0 "Boolean_FALSE" 1 "Boolean_TRUE";
VAL_ 48 RecOfImpctCrashSideRi 0 "Boolean_FALSE" 1 "Boolean_TRUE";
VAL_ 48 RecOfImpctCrashState 0 "CrashSt_NoCrash" 1 "CrashSt_CrashImminent" 2 "CrashSt_CrashInProgress" 3 "CrashSt_CrashEnding";
VAL_ 48 RecOfImpctVehOri 0 "Orntn_OnWheels" 1 "Orntn_LeftSide" 2 "Orntn_RightSide" 3 "Orntn_OnRoof" 4 "Orntn_Indeterminate" 5 "Orntn_Resd1" 6 "Orntn_Resd2" 7 "Orntn_Resd3";
VAL_ 48 TrLockSts 0 "LockSts2_LockStsUkwn" 1 "LockSts2_Unlckd" 2 "LockSts2_Lockd" 3 "LockSts2_SafeLockd";
VAL_ 48 TrSts 0 "DoorSts2_Ukwn" 1 "DoorSts2_Opend" 2 "DoorSts2_Clsd";
VAL_ 944 AccrPedlPsdAccrPedlPsd 0 "NoYes1_No" 1 "NoYes1_Yes";
VAL_ 944 AccrPedlPsdSts 0 "NoYes1_No" 1 "NoYes1_Yes";
VAL_ 944 AjarChrgLidRearSwitch 0 "DoorSts2_Ukwn" 1 "DoorSts2_Opend" 2 "DoorSts2_Clsd";
VAL_ 944 DCChrgSt 0 "DCChrgrSts_Idle" 1 "DCChrgrSts_Prestart" 2 "DCChrgrSts_Charging" 3 "DCChrgrSts_DCChrgnFltVehSide" 4 "DCChrgrSts_DCChrgnFltChrgrSideTempFlt" 5 "DCChrgrSts_DCChrgnFltChrgrSideConnectFlt" 6 "DCChrgrSts_DCChrgnFltChrgrSideOtherFlt" 7 "DCChrgrSts_DCChrgnFltChrgrSideEmgyFlt" 8 "DCChrgrSts_DCChrgnFltChrgrSideComFlt" 9 "DCChrgrSts_Bookcharging" 10 "DCChrgrSts_Shuntdown" 11 "DCChrgrSts_Heating" 12 "DCChrgrSts_Supercharging" 13 "DCChrgrSts_SuperchargingEnd";
VAL_ 944 EscWarnIndcnReqEscWarnIndcnReq 0 "EscWarnIndcnReq_EscWarnIndcnOnReq" 1 "EscWarnIndcnReq_EscWarnIndcnFlsgReq" 2 "EscWarnIndcnReq_Resd2" 3 "EscWarnIndcnReq_EscWarnIndcnOffReq";
VAL_ 944 GearIndcnRecGearIndcn 0 "GearIndcnTyp2_NoIndcn" 1 "GearIndcnTyp2_Gear1" 2 "GearIndcnTyp2_Gear2" 3 "GearIndcnTyp2_Gear3" 4 "GearIndcnTyp2_Gear4" 5 "GearIndcnTyp2_Gear5" 6 "GearIndcnTyp2_Gear6" 7 "GearIndcnTyp2_Gear7" 8 "GearIndcnTyp2_Gear8" 9 "GearIndcnTyp2_Gear9" 10 "GearIndcnTyp2_Gear10" 11 "GearIndcnTyp2_Gear11" 12 "GearIndcnTyp2_Gear2468" 13 "GearIndcnTyp2_Gear13579" 14 "GearIndcnTyp2_Neut" 15 "GearIndcnTyp2_Rvs";
VAL_ 944 GearIndcnRecGearShiftIndcn 0 "GearShiftIndcn_NoShiftIndcn" 1 "GearShiftIndcn_ShiftUpIndcn" 2 "GearShiftIndcn_CoolShiftIndcn" 3 "GearShiftIndcn_ShiftDwnIndcn";
VAL_ 944 GearIndcnRecGearTarIndcn 0 "GearIndcnTyp2_NoIndcn" 1 "GearIndcnTyp2_Gear1" 2 "GearIndcnTyp2_Gear2" 3 "GearIndcnTyp2_Gear3" 4 "GearIndcnTyp2_Gear4" 5 "GearIndcnTyp2_Gear5" 6 "GearIndcnTyp2_Gear6" 7 "GearIndcnTyp2_Gear7" 8 "GearIndcnTyp2_Gear8" 9 "GearIndcnTyp2_Gear9" 10 "GearIndcnTyp2_Gear10" 11 "GearIndcnTyp2_Gear11" 12 "GearIndcnTyp2_Gear2468" 13 "GearIndcnTyp2_Gear13579" 14 "GearIndcnTyp2_Neut" 15 "GearIndcnTyp2_Rvs";
VAL_ 944 IemGenericADAlrmSt 0 "AlrmSt_Disarmd" 1 "AlrmSt_Armd" 2 "AlrmSt_Actv";
VAL_ 944 IemGenericFltAlrmSt 0 "AlrmSt_Disarmd" 1 "AlrmSt_Armd" 2 "AlrmSt_Actv";
VAL_ 944 IemGenericIacAlrmSt 0 "AlrmSt_Disarmd" 1 "AlrmSt_Armd" 2 "AlrmSt_Actv";
VAL_ 944 IemGenericInvrtTAlrmSt 0 "AlrmSt_Disarmd" 1 "AlrmSt_Armd" 2 "AlrmSt_Actv";
VAL_ 944 IemGenericModStatusRms 0 "ModStatusRms_Invalid" 1 "PModStatusRms_wrCns" 2 "ModStatusRms_PwrGen" 3 "ModStatusRms_OffSts" 4 "ModStatusRms_RdySts" 5 "ModStatusRms_Abnormal" 6 "ModStatusRms_Invalid1" 7 "ModStatusRms_Invalid2" 8 "ModStatusRms_Invalid3" 9 "ModStatusRms_Invalid4" 10 "ModStatusRms_Invalid5" 11 "ModStatusRms_Invalid6" 12 "ModStatusRms_Invalid7" 13 "ModStatusRms_Invalid8" 14 "ModStatusRms_Invalid9" 15 "ModStatusRms_Invalid10";
VAL_ 944 IemGenericMotTAlrmSt 0 "AlrmSt_Disarmd" 1 "AlrmSt_Armd" 2 "AlrmSt_Actv";
VAL_ 944 IemGenericRslAlrmSt 0 "AlrmSt_Disarmd" 1 "AlrmSt_Armd" 2 "AlrmSt_Actv";
VAL_ 944 IemGenericSpdAlrmSt 0 "AlrmSt_Disarmd" 1 "AlrmSt_Armd" 2 "AlrmSt_Actv";
VAL_ 944 IemGenericUDcAlrmSt 0 "AlrmSt_Disarmd" 1 "AlrmSt_Armd" 2 "AlrmSt_Actv";
VAL_ 944 IntPm25LvlFrmClima 0 "CmpmtAirPmLvl_Level1" 1 "CmpmtAirPmLvl_Level2" 2 "CmpmtAirPmLvl_Level3" 3 "CmpmtAirPmLvl_Level4" 4 "CmpmtAirPmLvl_Level5" 5 "CmpmtAirPmLvl_Level6" 6 "CmpmtAirPmLvl_Reserved" 7 "CmpmtAirPmLvl_Invalid";
VAL_ 944 OnBdChrgrHndlSts1 0 "OnBdChrgrHndlSts1_Disconnected" 1 "OnBdChrgrHndlSts1_ConnectedWithoutPower" 2 "OnBdChrgrHndlSts1_PowerAvailableButNotActivated" 3 "OnBdChrgrHndlSts1_ConnectedWithPower" 4 "OnBdChrgrHndlSts1_DischargeConnectwithoutpowerincar" 5 "OnBdChrgrHndlSts1_DischargeConnectwithoutpoweroutcar" 6 "OnBdChrgrHndlSts1_DischargeConnectwithpowerincar" 7 "OnBdChrgrHndlSts1_DischargeConnectwithpoweroutcar" 8 "OnBdChrgrHndlSts1_Init" 9 "OnBdChrgrHndlSts1_Fault" 10 "OnBdChrgrHndlSts1_NotCompleteConnnected" 11 "OnBdChrgrHndlSts1_Reserved0" 12 "OnBdChrgrHndlSts1_Reserved1" 13 "OnBdChrgrHndlSts1_Reserved2";
VAL_ 944 OnBdChrgrPwrEnaAllwd 0 "Boolean_FALSE" 1 "Boolean_TRUE";
VAL_ 944 OnBdChrgrSt 0 "ChrgrSts1_Idle" 1 "ChrgrSts1_PreStrt" 2 "ChrgrSts1_Chrgn" 3 "ChrgrSts1_Alrm" 4 "ChrgrSts1_Srv" 5 "ChrgrSts1_Diagc" 6 "ChrgrSts1_Boot" 7 "ChrgrSts1_Rstrt" 8 "ChrgrSts1_DisChrgn" 9 "ChrgrSts1_BookChrgn" 10 "ChrgrSts1_Shutdown" 11 "ChrgrSts1_Heating" 12 "ChrgrSts1_Cooling";
VAL_ 944 RemAllowStrt 0 "Validity_NotValid" 1 "Validity_Valid";
VAL_ 944 WirelschrgActvReqFromHmi 0 "OnOff1_Off" 1 "OnOff1_On";
VAL_ 832 BookChargeSetResponse 0 "BookChargeSetResponse_Default" 1 "BookChargeSetResponse_Success" 2 "BookChargeSetResponse_Cancelled" 3 "BookChargeSetResponse_Fail";
VAL_ 832 BrkAndAbsWarnIndcnReqAbsWarnIndcnReq 0 "AbsWarnIndcnReq_AbsWarnIndcnOnReq" 1 "AbsWarnIndcnReq_AbsWarnIndcnFlsgReq" 2 "AbsWarnIndcnReq_Resd2" 3 "AbsWarnIndcnReq_AbsWarnIndcnOffReq";
VAL_ 832 BrkAndAbsWarnIndcnReqBrkWarnIndcnReq 0 "OnOff2_On" 1 "OnOff2_Off";
VAL_ 832 DispOfPrpsnMod 0 "DispOfPrpsnMod4_NotRdy" 1 "DispOfPrpsnMod4_ChrgnWithOnBdChrgr" 2 "DispOfPrpsnMod4_PrpsnMotElecAndPrpsnEng" 3 "DispOfPrpsnMod4_PrpsnMotElecAndPrpsnEngAndChrgn" 4 "DispOfPrpsnMod4_OnlyEngPrpsn" 5 "DispOfPrpsnMod4_OnlyEngPrpsnAndChrgn" 6 "DispOfPrpsnMod4_OnlyPrpsnMotElec" 7 "DispOfPrpsnMod4_NoPrpsnMotElecAndEngOff" 8 "DispOfPrpsnMod4_NoPrpsnMotElecAndOnEng" 9 "DispOfPrpsnMod4_NoPrpsnMotElecAndOnEngAndChrgn" 10 "DispOfPrpsnMod4_BrkgRgnAndEngOff" 11 "DispOfPrpsnMod4_BrkgRgnAndOnEng" 12 "DispOfPrpsnMod4_BrkgRgnAndEngOnAndChrgn" 13 "DispOfPrpsnMod4_Abnormal" 14 "DispOfPrpsnMod4_PrpsnMotElecAndEngChrgn" 15 "DispOfPrpsnMod4_PrpsnMotElecAndEngOn";
VAL_ 832 EngForbidRespFromVMM 0 "NoYes1_No" 1 "NoYes1_Yes";
VAL_ 832 NotifForEmgyCall 0 "Boolean_FALSE" 1 "Boolean_TRUE";
VAL_ 832 PassSeatSnsrSts2 0 "OkNokDi_Ok" 1 "OkNokDi_NotOk" 2 "OkNokDi_Disabled" 3 "OkNokDi_Reserved";
VAL_ 832 PassSeatSts2 0 "OccptPresSt1_Undefd1" 1 "OccptPresSt1_OccptNotPrsnt" 2 "OccptPresSt1_OccptPrsnt" 3 "OccptPresSt1_Undefd2";
VAL_ 832 TCSDoorNoClsSts 0 "OnOff1_Off" 1 "OnOff1_On";
VAL_ 832 TrOpenerByFootOperCmd 0 "OnOff1_Off" 1 "OnOff1_On";
VAL_ 832 TrsmParkLockdTrsmParkLockd 0 "TrsmParkLock1_ParkNotEngd" 1 "TrsmParkLock1_ParkEngd" 2 "TrsmParkLock1_NotInUse" 3 "TrsmParkLock1_Undefd";
VAL_ 832 VehMtnStVehMtnSt 0 "VehMtnSt2_Ukwn" 1 "VehMtnSt2_StandStillVal1" 2 "VehMtnSt2_StandStillVal2" 3 "VehMtnSt2_StandStillVal3" 4 "VehMtnSt2_RollgFwdVal1" 5 "VehMtnSt2_RollgFwdVal2" 6 "VehMtnSt2_RollgBackwVal1" 7 "VehMtnSt2_RollgBackwVal2";
VAL_ 832 WirelsChrgFrntLeSwt 0 "OnOff1_Off" 1 "OnOff1_On";
VAL_ 832 WirelsChrgFrntRiSwt 0 "OnOff1_Off" 1 "OnOff1_On";
VAL_ 272 ClimaActv 0 "OnOff1_Off" 1 "OnOff1_On";
VAL_ 272 HoodSts 0 "DoorSts2_Ukwn" 1 "DoorSts2_Opend" 2 "DoorSts2_Clsd";
VAL_ 272 SunRoofPosnSts 0 "WinAndRoofAndCurtPosnTyp_PosnUkwn" 1 "WinAndRoofAndCurtPosnTyp_ClsFull" 2 "WinAndRoofAndCurtPosnTyp_PercOpen4" 3 "WinAndRoofAndCurtPosnTyp_PercOpen8" 4 "WinAndRoofAndCurtPosnTyp_PercOpen12" 5 "WinAndRoofAndCurtPosnTyp_PercOpen16" 6 "WinAndRoofAndCurtPosnTyp_PercOpen20" 7 "WinAndRoofAndCurtPosnTyp_PercOpen24" 8 "WinAndRoofAndCurtPosnTyp_PercOpen28" 9 "WinAndRoofAndCurtPosnTyp_PercOpen32" 10 "WinAndRoofAndCurtPosnTyp_PercOpen36" 11 "WinAndRoofAndCurtPosnTyp_PercOpen40" 12 "WinAndRoofAndCurtPosnTyp_PercOpen44" 13 "WinAndRoofAndCurtPosnTyp_PercOpen48" 14 "WinAndRoofAndCurtPosnTyp_PercOpen52" 15 "WinAndRoofAndCurtPosnTyp_PercOpen56" 16 "WinAndRoofAndCurtPosnTyp_PercOpen60" 17 "WinAndRoofAndCurtPosnTyp_PercOpen64" 18 "WinAndRoofAndCurtPosnTyp_PercOpen68" 19 "WinAndRoofAndCurtPosnTyp_PercOpen72" 20 "WinAndRoofAndCurtPosnTyp_PercOpen76" 21 "WinAndRoofAndCurtPosnTyp_PercOpen80" 22 "WinAndRoofAndCurtPosnTyp_PercOpen84" 23 "WinAndRoofAndCurtPosnTyp_PercOpen88" 24 "WinAndRoofAndCurtPosnTyp_PercOpen92" 25 "WinAndRoofAndCurtPosnTyp_PercOpen96" 26 "WinAndRoofAndCurtPosnTyp_OpenFull" 27 "WinAndRoofAndCurtPosnTyp_Resd1" 28 "WinAndRoofAndCurtPosnTyp_Resd2" 29 "WinAndRoofAndCurtPosnTyp_Resd3" 30 "WinAndRoofAndCurtPosnTyp_Resd4" 31 "WinAndRoofAndCurtPosnTyp_Movg";
VAL_ 272 WinPosnStsAtDrvr 0 "WinAndRoofAndCurtPosnTyp_PosnUkwn" 1 "WinAndRoofAndCurtPosnTyp_ClsFull" 2 "WinAndRoofAndCurtPosnTyp_PercOpen4" 3 "WinAndRoofAndCurtPosnTyp_PercOpen8" 4 "WinAndRoofAndCurtPosnTyp_PercOpen12" 5 "WinAndRoofAndCurtPosnTyp_PercOpen16" 6 "WinAndRoofAndCurtPosnTyp_PercOpen20" 7 "WinAndRoofAndCurtPosnTyp_PercOpen24" 8 "WinAndRoofAndCurtPosnTyp_PercOpen28" 9 "WinAndRoofAndCurtPosnTyp_PercOpen32" 10 "WinAndRoofAndCurtPosnTyp_PercOpen36" 11 "WinAndRoofAndCurtPosnTyp_PercOpen40" 12 "WinAndRoofAndCurtPosnTyp_PercOpen44" 13 "WinAndRoofAndCurtPosnTyp_PercOpen48" 14 "WinAndRoofAndCurtPosnTyp_PercOpen52" 15 "WinAndRoofAndCurtPosnTyp_PercOpen56" 16 "WinAndRoofAndCurtPosnTyp_PercOpen60" 17 "WinAndRoofAndCurtPosnTyp_PercOpen64" 18 "WinAndRoofAndCurtPosnTyp_PercOpen68" 19 "WinAndRoofAndCurtPosnTyp_PercOpen72" 20 "WinAndRoofAndCurtPosnTyp_PercOpen76" 21 "WinAndRoofAndCurtPosnTyp_PercOpen80" 22 "WinAndRoofAndCurtPosnTyp_PercOpen84" 23 "WinAndRoofAndCurtPosnTyp_PercOpen88" 24 "WinAndRoofAndCurtPosnTyp_PercOpen92" 25 "WinAndRoofAndCurtPosnTyp_PercOpen96" 26 "WinAndRoofAndCurtPosnTyp_OpenFull" 27 "WinAndRoofAndCurtPosnTyp_Resd1" 28 "WinAndRoofAndCurtPosnTyp_Resd2" 29 "WinAndRoofAndCurtPosnTyp_Resd3" 30 "WinAndRoofAndCurtPosnTyp_Resd4" 31 "WinAndRoofAndCurtPosnTyp_Movg";
VAL_ 272 WinPosnStsAtPass 0 "WinAndRoofAndCurtPosnTyp_PosnUkwn" 1 "WinAndRoofAndCurtPosnTyp_ClsFull" 2 "WinAndRoofAndCurtPosnTyp_PercOpen4" 3 "WinAndRoofAndCurtPosnTyp_PercOpen8" 4 "WinAndRoofAndCurtPosnTyp_PercOpen12" 5 "WinAndRoofAndCurtPosnTyp_PercOpen16" 6 "WinAndRoofAndCurtPosnTyp_PercOpen20" 7 "WinAndRoofAndCurtPosnTyp_PercOpen24" 8 "WinAndRoofAndCurtPosnTyp_PercOpen28" 9 "WinAndRoofAndCurtPosnTyp_PercOpen32" 10 "WinAndRoofAndCurtPosnTyp_PercOpen36" 11 "WinAndRoofAndCurtPosnTyp_PercOpen40" 12 "WinAndRoofAndCurtPosnTyp_PercOpen44" 13 "WinAndRoofAndCurtPosnTyp_PercOpen48" 14 "WinAndRoofAndCurtPosnTyp_PercOpen52" 15 "WinAndRoofAndCurtPosnTyp_PercOpen56" 16 "WinAndRoofAndCurtPosnTyp_PercOpen60" 17 "WinAndRoofAndCurtPosnTyp_PercOpen64" 18 "WinAndRoofAndCurtPosnTyp_PercOpen68" 19 "WinAndRoofAndCurtPosnTyp_PercOpen72" 20 "WinAndRoofAndCurtPosnTyp_PercOpen76" 21 "WinAndRoofAndCurtPosnTyp_PercOpen80" 22 "WinAndRoofAndCurtPosnTyp_PercOpen84" 23 "WinAndRoofAndCurtPosnTyp_PercOpen88" 24 "WinAndRoofAndCurtPosnTyp_PercOpen92" 25 "WinAndRoofAndCurtPosnTyp_PercOpen96" 26 "WinAndRoofAndCurtPosnTyp_OpenFull" 27 "WinAndRoofAndCurtPosnTyp_Resd1" 28 "WinAndRoofAndCurtPosnTyp_Resd2" 29 "WinAndRoofAndCurtPosnTyp_Resd3" 30 "WinAndRoofAndCurtPosnTyp_Resd4" 31 "WinAndRoofAndCurtPosnTyp_Movg";
VAL_ 272 WinPosnStsAtReLe 0 "WinAndRoofAndCurtPosnTyp_PosnUkwn" 1 "WinAndRoofAndCurtPosnTyp_ClsFull" 2 "WinAndRoofAndCurtPosnTyp_PercOpen4" 3 "WinAndRoofAndCurtPosnTyp_PercOpen8" 4 "WinAndRoofAndCurtPosnTyp_PercOpen12" 5 "WinAndRoofAndCurtPosnTyp_PercOpen16" 6 "WinAndRoofAndCurtPosnTyp_PercOpen20" 7 "WinAndRoofAndCurtPosnTyp_PercOpen24" 8 "WinAndRoofAndCurtPosnTyp_PercOpen28" 9 "WinAndRoofAndCurtPosnTyp_PercOpen32" 10 "WinAndRoofAndCurtPosnTyp_PercOpen36" 11 "WinAndRoofAndCurtPosnTyp_PercOpen40" 12 "WinAndRoofAndCurtPosnTyp_PercOpen44" 13 "WinAndRoofAndCurtPosnTyp_PercOpen48" 14 "WinAndRoofAndCurtPosnTyp_PercOpen52" 15 "WinAndRoofAndCurtPosnTyp_PercOpen56" 16 "WinAndRoofAndCurtPosnTyp_PercOpen60" 17 "WinAndRoofAndCurtPosnTyp_PercOpen64" 18 "WinAndRoofAndCurtPosnTyp_PercOpen68" 19 "WinAndRoofAndCurtPosnTyp_PercOpen72" 20 "WinAndRoofAndCurtPosnTyp_PercOpen76" 21 "WinAndRoofAndCurtPosnTyp_PercOpen80" 22 "WinAndRoofAndCurtPosnTyp_PercOpen84" 23 "WinAndRoofAndCurtPosnTyp_PercOpen88" 24 "WinAndRoofAndCurtPosnTyp_PercOpen92" 25 "WinAndRoofAndCurtPosnTyp_PercOpen96" 26 "WinAndRoofAndCurtPosnTyp_OpenFull" 27 "WinAndRoofAndCurtPosnTyp_Resd1" 28 "WinAndRoofAndCurtPosnTyp_Resd2" 29 "WinAndRoofAndCurtPosnTyp_Resd3" 30 "WinAndRoofAndCurtPosnTyp_Resd4" 31 "WinAndRoofAndCurtPosnTyp_Movg";
VAL_ 272 WinPosnStsAtReRi 0 "WinAndRoofAndCurtPosnTyp_PosnUkwn" 1 "WinAndRoofAndCurtPosnTyp_ClsFull" 2 "WinAndRoofAndCurtPosnTyp_PercOpen4" 3 "WinAndRoofAndCurtPosnTyp_PercOpen8" 4 "WinAndRoofAndCurtPosnTyp_PercOpen12" 5 "WinAndRoofAndCurtPosnTyp_PercOpen16" 6 "WinAndRoofAndCurtPosnTyp_PercOpen20" 7 "WinAndRoofAndCurtPosnTyp_PercOpen24" 8 "WinAndRoofAndCurtPosnTyp_PercOpen28" 9 "WinAndRoofAndCurtPosnTyp_PercOpen32" 10 "WinAndRoofAndCurtPosnTyp_PercOpen36" 11 "WinAndRoofAndCurtPosnTyp_PercOpen40" 12 "WinAndRoofAndCurtPosnTyp_PercOpen44" 13 "WinAndRoofAndCurtPosnTyp_PercOpen48" 14 "WinAndRoofAndCurtPosnTyp_PercOpen52" 15 "WinAndRoofAndCurtPosnTyp_PercOpen56" 16 "WinAndRoofAndCurtPosnTyp_PercOpen60" 17 "WinAndRoofAndCurtPosnTyp_PercOpen64" 18 "WinAndRoofAndCurtPosnTyp_PercOpen68" 19 "WinAndRoofAndCurtPosnTyp_PercOpen72" 20 "WinAndRoofAndCurtPosnTyp_PercOpen76" 21 "WinAndRoofAndCurtPosnTyp_PercOpen80" 22 "WinAndRoofAndCurtPosnTyp_PercOpen84" 23 "WinAndRoofAndCurtPosnTyp_PercOpen88" 24 "WinAndRoofAndCurtPosnTyp_PercOpen92" 25 "WinAndRoofAndCurtPosnTyp_PercOpen96" 26 "WinAndRoofAndCurtPosnTyp_OpenFull" 27 "WinAndRoofAndCurtPosnTyp_Resd1" 28 "WinAndRoofAndCurtPosnTyp_Resd2" 29 "WinAndRoofAndCurtPosnTyp_Resd3" 30 "WinAndRoofAndCurtPosnTyp_Resd4" 31 "WinAndRoofAndCurtPosnTyp_Movg";
VAL_ 800 ChrgnByEngStsDurgDcha 0 "ChrgnByEngSts_NoReq" 1 "ChrgnByEngSts_Chrgn" 2 "ChrgnByEngSts_Flt" 3 "ChrgnByEngSts_Finished" 4 "ChrgnByEngSts_StopByFuelLow" 5 "ChrgnByEngSts_StopByTiOut" 6 "ChrgnByEngSts_Reserved1" 7 "ChrgnByEngSts_Reserved2";
VAL_ 800 ChrgnWarn 0 "Warn2_NoWarn" 1 "Warn2_Warn";
VAL_ 800 EngFltIndcn1 0 "DevErrSts2_NoFlt" 1 "DevErrSts2_Flt";
VAL_ 800 EngFltIndcn10 0 "DevErrSts2_NoFlt" 1 "DevErrSts2_Flt";
VAL_ 800 EngFltIndcn11 0 "DevErrSts2_NoFlt" 1 "DevErrSts2_Flt";
VAL_ 800 EngFltIndcn12 0 "DevErrSts2_NoFlt" 1 "DevErrSts2_Flt";
VAL_ 800 EngFltIndcn13 0 "DevErrSts2_NoFlt" 1 "DevErrSts2_Flt";
VAL_ 800 EngFltIndcn14 0 "DevErrSts2_NoFlt" 1 "DevErrSts2_Flt";
VAL_ 800 EngFltIndcn15 0 "DevErrSts2_NoFlt" 1 "DevErrSts2_Flt";
VAL_ 800 EngFltIndcn16 0 "DevErrSts2_NoFlt" 1 "DevErrSts2_Flt";
VAL_ 800 EngFltIndcn17 0 "DevErrSts2_NoFlt" 1 "DevErrSts2_Flt";
VAL_ 800 EngFltIndcn18 0 "DevErrSts2_NoFlt" 1 "DevErrSts2_Flt";
VAL_ 800 EngFltIndcn19 0 "DevErrSts2_NoFlt" 1 "DevErrSts2_Flt";
VAL_ 800 EngFltIndcn2 0 "DevErrSts2_NoFlt" 1 "DevErrSts2_Flt";
VAL_ 800 EngFltIndcn20 0 "DevErrSts2_NoFlt" 1 "DevErrSts2_Flt";
VAL_ 800 EngFltIndcn21 0 "DevErrSts2_NoFlt" 1 "DevErrSts2_Flt";
VAL_ 800 EngFltIndcn22 0 "DevErrSts2_NoFlt" 1 "DevErrSts2_Flt";
VAL_ 800 EngFltIndcn23 0 "DevErrSts2_NoFlt" 1 "DevErrSts2_Flt";
VAL_ 800 EngFltIndcn24 0 "DevErrSts2_NoFlt" 1 "DevErrSts2_Flt";
VAL_ 800 EngFltIndcn25 0 "DevErrSts2_NoFlt" 1 "DevErrSts2_Flt";
VAL_ 800 EngFltIndcn26 0 "DevErrSts2_NoFlt" 1 "DevErrSts2_Flt";
VAL_ 800 EngFltIndcn27 0 "DevErrSts2_NoFlt" 1 "DevErrSts2_Flt";
VAL_ 800 EngFltIndcn3 0 "DevErrSts2_NoFlt" 1 "DevErrSts2_Flt";
VAL_ 800 EngFltIndcn4 0 "DevErrSts2_NoFlt" 1 "DevErrSts2_Flt";
VAL_ 800 EngFltIndcn5 0 "DevErrSts2_NoFlt" 1 "DevErrSts2_Flt";
VAL_ 800 EngFltIndcn6 0 "DevErrSts2_NoFlt" 1 "DevErrSts2_Flt";
VAL_ 800 EngFltIndcn7 0 "DevErrSts2_NoFlt" 1 "DevErrSts2_Flt";
VAL_ 800 EngFltIndcn8 0 "DevErrSts2_NoFlt" 1 "DevErrSts2_Flt";
VAL_ 800 EngFltIndcn9 0 "DevErrSts2_NoFlt" 1 "DevErrSts2_Flt";
VAL_ 800 EngOilLvlSts 0 "EngOilLvlSts1_OilLvlOk" 1 "EngOilLvlSts1_OilLvlLo1" 2 "EngOilLvlSts1_OilLvlLo2" 3 "EngOilLvlSts1_OilLvlHi" 4 "EngOilLvlSts1_OilLvlSrvRqrd" 5 "EngOilLvlSts1_Resd";
VAL_ 800 EngOilPWarn 0 "EngOilPWarn1_EngOilPOk" 1 "EngOilPWarn1_EngOilPNotOk";
VAL_ 800 IgmGenericADAlrmSt 0 "AlrmSt_Disarmd" 1 "AlrmSt_Armd" 2 "AlrmSt_Actv";
VAL_ 800 IgmGenericFltAlrmSt 0 "AlrmSt_Disarmd" 1 "AlrmSt_Armd" 2 "AlrmSt_Actv";
VAL_ 800 IgmGenericIacAlrmSt 0 "AlrmSt_Disarmd" 1 "AlrmSt_Armd" 2 "AlrmSt_Actv";
VAL_ 800 IgmGenericInvrtTAlrmSt 0 "AlrmSt_Disarmd" 1 "AlrmSt_Armd" 2 "AlrmSt_Actv";
VAL_ 800 IgmGenericModStatusRms 0 "ModStatusRms_Invalid" 1 "PModStatusRms_wrCns" 2 "ModStatusRms_PwrGen" 3 "ModStatusRms_OffSts" 4 "ModStatusRms_RdySts" 5 "ModStatusRms_Abnormal" 6 "ModStatusRms_Invalid1" 7 "ModStatusRms_Invalid2" 8 "ModStatusRms_Invalid3" 9 "ModStatusRms_Invalid4" 10 "ModStatusRms_Invalid5" 11 "ModStatusRms_Invalid6" 12 "ModStatusRms_Invalid7" 13 "ModStatusRms_Invalid8" 14 "ModStatusRms_Invalid9" 15 "ModStatusRms_Invalid10";
VAL_ 800 IgmGenericMotTAlrmSt 0 "AlrmSt_Disarmd" 1 "AlrmSt_Armd" 2 "AlrmSt_Actv";
VAL_ 800 IgmGenericRslAlrmSt 0 "AlrmSt_Disarmd" 1 "AlrmSt_Armd" 2 "AlrmSt_Actv";
VAL_ 800 IgmGenericSpdAlrmSt 0 "AlrmSt_Disarmd" 1 "AlrmSt_Armd" 2 "AlrmSt_Actv";
VAL_ 800 IgmGenericUDcAlrmSt 0 "AlrmSt_Disarmd" 1 "AlrmSt_Armd" 2 "AlrmSt_Actv";
VAL_ 800 LockgCenStsForUsrFb 0 "LockSt2_Undefd" 1 "LockSt2_Opend" 2 "LockSt2_Clsd" 3 "LockSt2_Lockd" 4 "LockSt2_Safe";
VAL_ 800 OilMntnAlrmSt 0 "OilMntnAlrmSt_NoRequestForMntn" 1 "OilMntnAlrmSt_MntnAboutToExpire" 2 "OilMntnAlrmSt_MntnExpire" 3 "OilMntnAlrmSt_MntnOutOfDate";
VAL_ 800 PrpsnModElecDrvBlkd 0 "Typ1_Typ0" 1 "Typ1_Typ1" 2 "Typ1_Typ2" 3 "Typ1_Typ3" 4 "Typ1_Typ4" 5 "Typ1_Typ5" 6 "Typ1_Typ6" 7 "Typ1_Typ7";
VAL_ 968 EngTQf 0 "Qf1_DevOfDataUndefd" 1 "Qf1_DataTmpUndefdAndEvlnInProgs" 2 "Qf1_DevOfDataNotWithinRngAllwd" 3 "Qf1_DataCalcdWithDevDefd";
VAL_ 968 EpbStsEpbSts 0 "EpbSts_Resd0" 1 "EpbSts_Resd1" 2 "EpbSts_Resd2" 3 "EpbSts_AllAppld" 4 "EpbSts_Resd4" 5 "EpbSts_AllInTran" 6 "EpbSts_BrkgDynByActr" 7 "EpbSts_Resd7" 8 "EpbSts_Resd8" 9 "EpbSts_ActrAllReld" 10 "EpbSts_BrkgDynDegraded" 11 "EpbSts_Resd11" 12 "EpbSts_BrkgDyn" 13 "EpbSts_Resd13" 14 "EpbSts_Resd14" 15 "EpbSts_Err";
VAL_ 968 FuCnsAvgIndcdFuCnsIndcdUnit 0 "FuCnsIndcdUnit_LperHectoKiloM" 1 "FuCnsIndcdUnit_KiloMPerL" 2 "FuCnsIndcdUnit_MilePerGallonEngland" 3 "FuCnsIndcdUnit_MilePerGallonUsa" 4 "FuCnsIndcdUnit_UkwnUnit";
VAL_ 968 FuCnsIndcdUnit 0 "FuCnsIndcdUnit_LperHectoKiloM" 1 "FuCnsIndcdUnit_KiloMPerL" 2 "FuCnsIndcdUnit_MilePerGallonEngland" 3 "FuCnsIndcdUnit_MilePerGallonUsa" 4 "FuCnsIndcdUnit_UkwnUnit";
VAL_ 968 FuLvlIndcdGenQF 0 "GenQf1_UndefindDataAccur" 1 "GenQf1_TmpUndefdData" 2 "GenQf1_DataAccurNotWithinSpcn" 3 "GenQf1_AccurData";
VAL_ 968 FuLvlLoIndcn 0 "Trig1_NoTrig" 1 "Trig1_Trig";
VAL_ 968 FuLvlLoWarn 0 "Trig1_NoTrig" 1 "Trig1_Trig";
VAL_ 968 HybErrIndcnReqTelltlBattTracCutOff 0 "Flg1_Rst" 1 "Flg1_Set";
VAL_ 968 HybErrIndcnReqTelltlBattTracFailr 0 "Flg1_Rst" 1 "Flg1_Set";
VAL_ 968 HybErrIndcnReqTelltlElecDrvFailr 0 "Flg1_Rst" 1 "Flg1_Set";
VAL_ 968 HybErrIndcnReqTelltlSysHybFailr 0 "Flg1_Rst" 1 "Flg1_Set";
VAL_ 968 IndcnUnitClkFmt 0 "ClkFmt_Hr24" 1 "ClkFmt_Hr12" 2 "ClkFmt_UkwnClkFmt";
VAL_ 968 IndcnUnitDateFmt 0 "DateFmt_DateFmt1" 1 "DateFmt_DateFmt2" 2 "DateFmt_DateFmt3" 3 "DateFmt_UkwnFmt";
VAL_ 968 IndcnUnitDstLong 0 "DstLong_km" 1 "DstLong_miles" 2 "DstLong_UkwnUnit";
VAL_ 968 IndcnUnitDstSho 0 "DstSho_Mtr" 1 "DstSho_Ft" 2 "DstSho_Yards" 3 "DstSho_UkwnUnit";
VAL_ 968 IndcnUnitFuCnsUnit 0 "FuCnsIndcdUnit_LperHectoKiloM" 1 "FuCnsIndcdUnit_KiloMPerL" 2 "FuCnsIndcdUnit_MilePerGallonEngland" 3 "FuCnsIndcdUnit_MilePerGallonUsa" 4 "FuCnsIndcdUnit_UkwnUnit";
VAL_ 968 IndcnUnitPUnit 0 "PUnit_Pa" 1 "PUnit_Psi" 2 "PUnit_Bar" 3 "PUnit_Atm" 4 "PUnit_UkwnUnit";
VAL_ 968 IndcnUnitSpdUnit 0 "VehSpdIndcdUnit_Kmph" 1 "VehSpdIndcdUnit_Mph" 2 "VehSpdIndcdUnit_UkwnUnit";
VAL_ 968 IndcnUnitTUnit 0 "AmbTIndcdUnit_Celsius" 1 "AmbTIndcdUnit_Fahrenheit" 2 "AmbTIndcdUnit_UkwnUnit";
VAL_ 968 IndcnUnitVolUnit 0 "VolUnit_litre" 1 "VolUnit_gallon1" 2 "VolUnit_gallon2" 3 "VolUnit_UkwnUnit";
VAL_ 968 IsgTqActQualityFactor 0 "QualityFactor_QfUndefd" 1 "QualityFactor_QfInProgs" 2 "QualityFactor_QfNotSpc" 3 "QualityFactor_QfSnsrDataOk";
VAL_ 968 PwrCnsAvgIndcd1PwrCnsUnit 0 "PwrCnsUnit_KWhPer100Km" 1 "PwrCnsUnit_KWhPer100Mile";
VAL_ 968 PwrCnsAvgIndcdPwrCnsUnit 0 "PwrCnsUnit_KWhPer100Km" 1 "PwrCnsUnit_KWhPer100Mile";
VAL_ 968 PwrCnsIndcdCnsUnit 0 "PwrCnsUnit_KWhPer100Km" 1 "PwrCnsUnit_KWhPer100Mile";
VAL_ 968 VehBattUSysUQf 0 "GenQf1_UndefindDataAccur" 1 "GenQf1_TmpUndefdData" 2 "GenQf1_DataAccurNotWithinSpcn" 3 "GenQf1_AccurData";
VAL_ 968 VehSpdAvgIndcdVeSpdIndcdUnit 0 "VehSpdIndcdUnit_Kmph" 1 "VehSpdIndcdUnit_Mph" 2 "VehSpdIndcdUnit_UkwnUnit";
VAL_ 968 VehSpdIndcdQly 0 "GenQf1_UndefindDataAccur" 1 "GenQf1_TmpUndefdData" 2 "GenQf1_DataAccurNotWithinSpcn" 3 "GenQf1_AccurData";
VAL_ 968 VehSpdIndcdVeSpdIndcdUnit 0 "VehSpdIndcdUnit_Kmph" 1 "VehSpdIndcdUnit_Mph" 2 "VehSpdIndcdUnit_UkwnUnit";
VAL_ 968 WhlMotSysTqEstQualityFactor 0 "QualityFactor_QfUndefd" 1 "QualityFactor_QfInProgs" 2 "QualityFactor_QfNotSpc" 3 "QualityFactor_QfSnsrDataOk";
VAL_ 976 OTAMod 0 "OTAMod_Idle" 1 "OTAMod_NoAssigment" 2 "OTAMod_SyncCSVersion" 3 "OTAMod_Downloading" 4 "OTAMod_DwonloadCompleted" 5 "OTAMod_InstallationConsentScheduled" 6 "OTAMod_InstallationConsentGranted" 7 "OTAMod_OTAMode" 8 "OTAMod_PreInstallation" 9 "OTAMod_SWDLInstallation" 10 "OTAMod_PostInstallation" 11 "OTAMod_HVPwrSts" 12 "OTAMod_InstallationCompleted" 13 "OTAMod_InstallationFaild" 14 "OTAMod_InstallationFaildCritical" 15 "OTAMod_InstallationFinishd" 16 "OTAMod_InstallationFaildCriticalLegal" 17 "OTAMod_OTALogUpload" 18 "OTAMod_DownloadingPause" 19 "OTAMod_InstallationDefferred" 20 "OTAMod_InstallationPending" 21 "OTAMod_SuperEnduranceMode";
VAL_ 976 PrkgCameraRes 0 "SuccessFailNoResp_NoResponse" 1 "SuccessFailNoResp_Success" 2 "SuccessFailNoResp_Fail" 3 "SuccessFailNoResp_Reserved";
VAL_ 976 PrkgCameraSwt 0 "OnOff1_Off" 1 "OnOff1_On";
VAL_ 976 VehTiAndDataDataValid 0 "NoYes1_No" 1 "NoYes1_Yes";
VAL_ 1281 WakeUpReasonsforDHU 0 "WakeupReasons_667949" 1 "WakeupReasons_667950" 2 "WakeupReasons_169654" 3 "WakeupReasons_667951" 4 "WakeupReasons_168965" 5 "WakeupReasons_197643" 6 "WakeupReasons_264933" 7 "WakeupReasons_45654" 8 "WakeupReasons_22058" 9 "WakeupReasons_49446" 10 "WakeupReasons_22060" 11 "WakeupReasons_269740" 12 "WakeupReasons_269735" 13 "WakeupReasons_269739" 14 "WakeupReasons_658500" 15 "WakeupReasons_21901" 16 "WakeupReasons_45793" 17 "WakeupReasons_45794" 18 "WakeupReasons_22005" 19 "WakeupReasons_22013" 20 "WakeupReasons_22100" 21 "WakeupReasons_45659" 22 "WakeupReasons_45657" 23 "WakeupReasons_140084" 24 "WakeupReasons_21973" 25 "WakeupReasons_91253" 26 "WakeupReasons_88123" 27 "WakeupReasons_88125" 28 "WakeupReasons_321583" 29 "WakeupReasons_74188" 30 "WakeupReasons_667945" 31 "WakeupReasons_169655" 32 "WakeupReasons_667948" 33 "WakeupReasons_168966" 34 "WakeupReasons_170865" 35 "WakeupReasons_197642" 36 "WakeupReasons_264876" 37 "WakeupReasons_191050" 38 "WakeupReasons_182033" 39 "WakeupReasons_200937" 40 "WakeupReasons_170807" 41 "WakeupReasons_319139" 42 "WakeupReasons_100298" 43 "WakeupReasons_100275" 44 "WakeupReasons_100300" 45 "WakeupReasons_100278" 46 "WakeupReasons_100281" 47 "WakeupReasons_265333" 48 "WakeupReasons_108776" 49 "WakeupReasons_176921" 50 "WakeupReasons_197826" 51 "WakeupReasons_185670" 52 "WakeupReasons_161066" 53 "WakeupReasons_200156" 54 "WakeupReasons_225696" 55 "WakeupReasons_21997" 56 "WakeupReasons_45656" 57 "WakeupReasons_266860" 58 "WakeupReasons_169894" 59 "WakeupReasons_320282" 60 "WakeupReasons_319422" 61 "WakeupReasons_320277" 62 "WakeupReasons_355601" 63 "WakeupReasons_360904" 64 "WakeupReasons_361505" 65 "WakeupReasons_361509" 66 "WakeupReasons_645094" 67 "WakeupReasons_68676" 68 "WakeupReasons_360008" 69 "WakeupReasons_109382" 70 "WakeupReasons_119273" 71 "WakeupReasons_224065" 72 "WakeupReasons_68644" 73 "WakeupReasons_109364" 74 "WakeupReasons_68481" 75 "WakeupReasons_224061" 76 "WakeupReasons_360006" 77 "WakeupReasons_138997" 78 "WakeupReasons_634696" 79 "WakeupReasons_645810" 80 "WakeupReasons_297868" 81 "WakeupReasons_315364" 82 "WakeupReasons_109367" 83 "WakeupReasons_320126" 84 "WakeupReasons_109387" 85 "WakeupReasons_634710" 86 "WakeupReasons_338820" 87 "WakeupReasons_67182" 88 "WakeupReasons_152237" 89 "WakeupReasons_145707" 90 "WakeupReasons_199172" 91 "WakeupReasons_144897" 92 "WakeupReasons_186489" 93 "WakeupReasons_144970" 94 "WakeupReasons_152786" 95 "WakeupReasons_264932" 96 "WakeupReasons_264934" 97 "WakeupReasons_356190" 98 "WakeupReasons_145688" 99 "WakeupReasons_95444" 100 "WakeupReasons_169945" 101 "WakeupReasons_140678" 102 "WakeupReasons_222553" 103 "WakeupReasons_224831" 104 "WakeupReasons_201815" 105 "WakeupReasons_45864" 106 "WakeupReasons_659549" 107 "WakeupReasons_45866" 108 "WakeupReasons_45867" 109 "WakeupReasons_169884" 110 "WakeupReasons_264962" 111 "WakeupReasons_201348" 112 "WakeupReasons_320287" 113 "WakeupReasons_156412" 114 "WakeupReasons_133749" 115 "WakeupReasons_355409" 116 "WakeupReasons_636692" 117 "WakeupReasons_533044" 118 "WakeupReasons_106774" 119 "WakeupReasons_145311" 120 "WakeupReasons_145319" 121 "WakeupReasons_152774" 122 "WakeupReasons_145330" 123 "WakeupReasons_145388" 124 "WakeupReasons_145399" 125 "WakeupReasons_145362" 126 "WakeupReasons_145385" 127 "WakeupReasons_145373" 128 "WakeupReasons_145288" 129 "WakeupReasons_145419" 130 "WakeupReasons_145454" 131 "WakeupReasons_145462" 132 "WakeupReasons_269156" 133 "WakeupReasons_300427" 134 "WakeupReasons_220322" 135 "WakeupReasons_224617" 136 "WakeupReasons_224634" 137 "WakeupReasons_300682" 138 "WakeupReasons_264958" 139 "WakeupReasons_160597" 140 "WakeupReasons_160602" 141 "WakeupReasons_108841" 142 "WakeupReasons_265569" 143 "WakeupReasons_526429" 144 "WakeupReasons_514545" 145 "WakeupReasons_265232" 146 "WakeupReasons_644550" 147 "WakeupReasons_317616" 148 "WakeupReasons_354791" 149 "WakeupReasons_320631" 150 "WakeupReasons_337565" 151 "WakeupReasons_532007" 152 "WakeupReasons_514503" 153 "WakeupReasons_299117" 154 "WakeupReasons_340667" 155 "WakeupReasons_321845" 156 "WakeupReasons_179103" 157 "WakeupReasons_108810" 158 "WakeupReasons_322857" 159 "WakeupReasons_658603" 160 "WakeupReasons_197648" 161 "WakeupReasons_160596" 162 "WakeupReasons_361272" 163 "WakeupReasons_361279" 164 "WakeupReasons_265305" 165 "WakeupReasons_265328" 166 "WakeupReasons_265330" 167 "WakeupReasons_298808" 168 "WakeupReasons_515804" 169 "WakeupReasons_514502" 170 "WakeupReasons_645753" 171 "WakeupReasons_646109" 172 "WakeupReasons_299547" 173 "WakeupReasons_318342" 174 "WakeupReasons_360543" 175 "WakeupReasons_356549" 176 "WakeupReasons_198484" 177 "WakeupReasons_300681" 178 "WakeupReasons_359211" 179 "WakeupReasons_534077" 180 "WakeupReasons_525705" 181 "WakeupReasons_360299" 182 "WakeupReasons_526445" 183 "WakeupReasons_534145" 184 "WakeupReasons_192030" 185 "WakeupReasons_652361" 186 "WakeupReasons_355214" 187 "WakeupReasons_321317" 188 "WakeupReasons_359187" 189 "WakeupReasons_321057" 190 "WakeupReasons_321319" 191 "WakeupReasons_321323" 192 "WakeupReasons_321077" 193 "WakeupReasons_320895" 194 "WakeupReasons_655340" 195 "WakeupReasons_636556" 196 "WakeupReasons_108834" 197 "WakeupReasons_265937" 198 "WakeupReasons_533050" 199 "WakeupReasons_526426" 200 "WakeupReasons_264712" 201 "WakeupReasons_319401" 202 "WakeupReasons_643973" 203 "WakeupReasons_223715" 204 "WakeupReasons_199159" 205 "WakeupReasons_318382" 206 "WakeupReasons_226967" 207 "WakeupReasons_531743" 208 "WakeupReasons_360542" 209 "WakeupReasons_264726" 210 "WakeupReasons_535214" 211 "WakeupReasons_335068" 212 "WakeupReasons_316796" 213 "WakeupReasons_526438" 214 "WakeupReasons_198433" 215 "WakeupReasons_225961" 216 "WakeupReasons_197665" 217 "WakeupReasons_224550" 218 "WakeupReasons_667962" 219 "WakeupReasons_667953" 220 "WakeupReasons_110885" 221 "WakeupReasons_224552" 222 "WakeupReasons_224553" 223 "WakeupReasons_652546" 224 "WakeupReasons_331194" 225 "WakeupReasons_667820" 226 "WakeupReasons_659350" 227 "WakeupReasons_101706" 228 "WakeupReasons_101725" 229 "WakeupReasons_101728" 230 "WakeupReasons_101727" 231 "WakeupReasons_166267" 232 "WakeupReasons_156440" 233 "WakeupReasons_95949" 234 "WakeupReasons_112799" 235 "WakeupReasons_146470" 236 "WakeupReasons_176748" 237 "WakeupReasons_223920" 238 "WakeupReasons_668531" 239 "WakeupReasons_670087" 240 "WakeupReasons_668529" 241 "WakeupReasons_45858" 242 "WakeupReasons_315981" 243 "WakeupReasons_533370" 244 "WakeupReasons_533371" 245 "WakeupReasons_533372" 246 "WakeupReasons_241902" 247 "WakeupReasons_359559" 248 "WakeupReasons_516327" 249 "WakeupReasons_533872" 250 "WakeupReasons_45856" 251 "WakeupReasons_45853" 252 "WakeupReasons_45854" 253 "WakeupReasons_45852" 254 "WakeupReasons_45851" 255 "WakeupReasons_45850" 256 "WakeupReasons_45849" 257 "WakeupReasons_636801" 258 "WakeupReasons_109466" 259 "WakeupReasons_109467" 260 "WakeupReasons_670345" 261 "WakeupReasons_NMPDUReceived" 262 "WakeupReasons_358832" 263 "WakeupReasons_200683" 264 "WakeupReasons_198452" 265 "WakeupReasons_185457" 266 "WakeupReasons_185490" 267 "WakeupReasons_4471" 268 "WakeupReasons_269034" 269 "WakeupReasons_215560" 270 "WakeupReasons_312881" 271 "WakeupReasons_269140" 272 "WakeupReasons_197653" 273 "WakeupReasons_337991" 274 "WakeupReasons_658188" 275 "WakeupReasons_674953" 276 "WakeupReasons_675064" 277 "WakeupReasons_674958" 278 "WakeupReasons_675494" 279 "WakeupReasons_675837" 280 "WakeupReasons_667879" 281 "WakeupReasons_667947" 282 "WakeupReasons_676265" 283 "WakeupReasons_669465" 284 "WakeupReasons_670928" 285 "WakeupReasons_669447" 286 "WakeupReasons_667922" 287 "WakeupReasons_670753" 288 "WakeupReasons_668395" 289 "WakeupReasons_668393" 290 "WakeupReasons_667850" 291 "WakeupReasons_667848" 292 "WakeupReasons_311279" 293 "WakeupReasons_182918" 294 "WakeupReasons_667988" 295 "WakeupReasons_532555" 296 "WakeupReasons_532556" 297 "WakeupReasons_113348" 298 "WakeupReasons_193474" 299 "WakeupReasons_667871" 300 "WakeupReasons_670966" 301 "WakeupReasons_667985" 302 "WakeupReasons_670354" 303 "WakeupReasons_46017" 304 "WakeupReasons_675742" 305 "WakeupReasons_106669" 306 "WakeupReasons_80609" 307 "WakeupReasons_199714" 308 "WakeupReasons_200090" 309 "WakeupReasons_139075" 310 "WakeupReasons_268983" 311 "WakeupReasons_265131" 312 "WakeupReasons_263473" 313 "WakeupReasons_45887" 314 "WakeupReasons_69678" 315 "WakeupReasons_69679" 316 "WakeupReasons_45897" 317 "WakeupReasons_45898" 318 "WakeupReasons_80608" 319 "WakeupReasons_45869" 320 "WakeupReasons_45870" 321 "WakeupReasons_45872" 322 "WakeupReasons_45875" 323 "WakeupReasons_45871" 324 "WakeupReasons_45876" 325 "WakeupReasons_667980" 326 "WakeupReasons_45877" 327 "WakeupReasons_667973" 328 "WakeupReasons_670962" 329 "WakeupReasons_45888" 330 "WakeupReasons_45890" 331 "WakeupReasons_667869" 332 "WakeupReasons_45846" 333 "WakeupReasons_45847" 334 "WakeupReasons_45848" 335 "WakeupReasons_262872" 336 "WakeupReasons_127924" 337 "WakeupReasons_127926" 338 "WakeupReasons_674223" 339 "WakeupReasons_667982" 340 "WakeupReasons_657121" 341 "WakeupReasons_265745" 342 "WakeupReasons_657120" 343 "WakeupReasons_675564" 344 "WakeupReasons_197644" 345 "WakeupReasons_264943" 346 "WakeupReasons_264697" 347 "WakeupReasons_69216" 348 "WakeupReasons_128671" 349 "WakeupReasons_356598" 350 "WakeupReasons_675745" 351 "WakeupReasons_667983" 352 "WakeupReasons_667987" 353 "WakeupReasons_75103" 354 "WakeupReasons_305818" 355 "WakeupReasons_670942" 356 "WakeupReasons_532932" 357 "WakeupReasons_532933" 358 "WakeupReasons_83199" 359 "WakeupReasons_45900" 360 "WakeupReasons_88458" 361 "WakeupReasons_329457" 362 "WakeupReasons_45902" 363 "WakeupReasons_224211" 364 "WakeupReasons_667981" 365 "WakeupReasons_667874" 366 "WakeupReasons_46020" 367 "WakeupReasons_667842" 368 "WakeupReasons_145161" 369 "WakeupReasons_233755" 370 "WakeupReasons_297056" 371 "WakeupReasons_264691" 372 "WakeupReasons_262871" 373 "WakeupReasons_264964" 374 "WakeupReasons_667872" 375 "WakeupReasons_45655" 376 "WakeupReasons_177214" 377 "WakeupReasons_671005" 378 "WakeupReasons_680712" 379 "WakeupReasons_669822" 380 "WakeupReasons_668523" 381 "WakeupReasons_680974" 382 "WakeupReasons_680975" 383 "WakeupReasons_681028" 384 "WakeupReasons_670462" 385 "WakeupReasons_681134" 386 "WakeupReasons_681031" 387 "WakeupReasons_681711" 388 "WakeupReasons_682034" 389 "WakeupReasons_674839" 390 "WakeupReasons_681915" 391 "WakeupReasons_682032" 392 "WakeupReasons_682037" 393 "WakeupReasons_682688" 394 "WakeupReasons_681789" 395 "WakeupReasons_682023" 396 "WakeupReasons_681023" 397 "WakeupReasons_676285" 398 "WakeupReasons_682077" 399 "WakeupReasons_682076" 400 "WakeupReasons_682078" 401 "WakeupReasons_682153" 402 "WakeupReasons_682155" 403 "WakeupReasons_682152" 404 "WakeupReasons_682154" 405 "WakeupReasons_682074";
SIG_GROUP_ 944 AccrPedlPsd 1 : AccrPedlPsdAccrPedlPsd AccrPedlPsdChks AccrPedlPsdCntr AccrPedlPsdSts;
SIG_GROUP_ 832 BrkAndAbsWarnIndcnReq 1 : BrkAndAbsWarnIndcnReqAbsWarnIndcnReq BrkAndAbsWarnIndcnReqBrkWarnIndcnReq BrkAndAbsWarnIndcnReqChks BrkAndAbsWarnIndcnReqCntr;
SIG_GROUP_ 800 EngFltIndcn 1 : EngFltIndcn1 EngFltIndcn10 EngFltIndcn11 EngFltIndcn12 EngFltIndcn13 EngFltIndcn14 EngFltIndcn15 EngFltIndcn16 EngFltIndcn17 EngFltIndcn18 EngFltIndcn19 EngFltIndcn2 EngFltIndcn20 EngFltIndcn21 EngFltIndcn22 EngFltIndcn23 EngFltIndcn24 EngFltIndcn25 EngFltIndcn26 EngFltIndcn27 EngFltIndcn3 EngFltIndcn4 EngFltIndcn5 EngFltIndcn6 EngFltIndcn7 EngFltIndcn8 EngFltIndcn9;
SIG_GROUP_ 968 EngT 1 : EngTEngT EngTQf;
SIG_GROUP_ 968 EpbSts 1 : EpbStsChks EpbStsCntr EpbStsEpbSts;
SIG_GROUP_ 944 EscWarnIndcnReq 1 : EscWarnIndcnReqChks EscWarnIndcnReqCntr EscWarnIndcnReqEscWarnIndcnReq;
SIG_GROUP_ 968 FuCnsAvgIndcd 1 : FuCnsAvgIndcdFuCnsIndcdUnit FuCnsAvgIndcdFuCnsIndcdVal;
SIG_GROUP_ 968 FuCnsIndcd 1 : FuCnsIndcdUnit FuCnsIndcdVal;
SIG_GROUP_ 968 FuLvlIndcd 1 : FuLvlIndcdFuLvlValFromFuTbl FuLvlIndcdGenQF;
SIG_GROUP_ 944 GearIndcnRec 1 : GearIndcnRecGearIndcn GearIndcnRecGearShiftIndcn GearIndcnRecGearTarIndcn;
SIG_GROUP_ 968 GidInfoInp1 1 : GidInfoInp1Byte0 GidInfoInp1Byte1 GidInfoInp1Byte2 GidInfoInp1Byte3 GidInfoInp1Byte4 GidInfoInp1Byte5 GidInfoInp1Byte6 GidInfoInp1Byte7;
SIG_GROUP_ 968 GidInfoInp2 1 : GidInfoInp2Byte0 GidInfoInp2Byte1 GidInfoInp2Byte2 GidInfoInp2Byte3 GidInfoInp2Byte4 GidInfoInp2Byte5 GidInfoInp2Byte6 GidInfoInp2Byte7;
SIG_GROUP_ 968 HybErrIndcnReq 1 : HybErrIndcnReqTelltlBattTracCutOff HybErrIndcnReqTelltlBattTracFailr HybErrIndcnReqTelltlElecDrvFailr HybErrIndcnReqTelltlSysHybFailr;
SIG_GROUP_ 944 IemGeneric 1 : IemGenericADAlrmSt IemGenericDTCHig IemGenericDTCLow IemGenericDTCMid IemGenericDTCSts IemGenericEMQnty IemGenericEMSeqNr IemGenericFltAlrmSt IemGenericIacAlrmSt IemGenericInvrtTAlrmSt IemGenericModStatusRms IemGenericMotTAlrmSt IemGenericRslAlrmSt IemGenericSpdAlrmSt IemGenericTypeInfo IemGenericUDcAlrmSt;
SIG_GROUP_ 800 IgmGeneric 1 : IgmGenericADAlrmSt IgmGenericDTCHig IgmGenericDTCLow IgmGenericDTCMid IgmGenericDTCSts IgmGenericEMQnty IgmGenericEMSeqNr IgmGenericFltAlrmSt IgmGenericIacAlrmSt IgmGenericInvrtTAlrmSt IgmGenericModStatusRms IgmGenericMotTAlrmSt IgmGenericRslAlrmSt IgmGenericSpdAlrmSt IgmGenericTypeInfo IgmGenericUDcAlrmSt;
SIG_GROUP_ 968 IndcnUnit 1 : IndcnUnitClkFmt IndcnUnitDateFmt IndcnUnitDstLong IndcnUnitDstSho IndcnUnitFuCnsUnit IndcnUnitPUnit IndcnUnitSpdUnit IndcnUnitTUnit IndcnUnitVolUnit;
SIG_GROUP_ 968 IsgTqAct 1 : IsgTqActChks IsgTqActCntr IsgTqActIsgTqAct IsgTqActQualityFactor;
SIG_GROUP_ 48 LockgCenSts 1 : LockgCenStsLockSt LockgCenStsTrigSrc LockgCenStsUpdEve;
SIG_GROUP_ 968 PwrCnsAvgIndcd 1 : PwrCnsAvgIndcdEcoDrvInfo1 PwrCnsAvgIndcdPwrCnsUnit;
SIG_GROUP_ 968 PwrCnsAvgIndcd1 1 : PwrCnsAvgIndcd1EcoDrvInfo1 PwrCnsAvgIndcd1PwrCnsUnit;
SIG_GROUP_ 968 PwrCnsIndcd 1 : PwrCnsIndcdCnsUnit PwrCnsIndcdPwrCnsIn;
SIG_GROUP_ 48 RecOfImpct 1 : RecOfImpctCrashFrnt RecOfImpctCrashOffroadA RecOfImpctCrashOffroadD RecOfImpctCrashOffroadRT RecOfImpctCrashOffroadRTsevere RecOfImpctCrashPed RecOfImpctCrashRe RecOfImpctCrashRollovr RecOfImpctCrashSideLe RecOfImpctCrashSideRi RecOfImpctCrashState RecOfImpctImpctDvx RecOfImpctImpctDvy RecOfImpctImpctRollAg RecOfImpctVehOri;
SIG_GROUP_ 48 RecOfImpct2 1 : RecOfImpct2ImpctDvxSigned RecOfImpct2ImpctDvySigned;
SIG_GROUP_ 880 SunRoofAndCurtFailr 1 : SunRoofAndCurtFailrCurtMotFailr SunRoofAndCurtFailrCurtMotHallFailr SunRoofAndCurtFailrCurtMotNotAvl SunRoofAndCurtFailrEcuFailrGen SunRoofAndCurtFailrPanMotFailr SunRoofAndCurtFailrPanMotHallFailr SunRoofAndCurtFailrPanMotNotAvl SunRoofAndCurtFailrResvd;
SIG_GROUP_ 341 TripResetSyncMsg 1 : TripResetSyncMsgAuthenticator TripResetSyncMsgResetcounter TripResetSyncMsgTripcounter;
SIG_GROUP_ 832 TrsmParkLockd 1 : TrsmParkLockdChks TrsmParkLockdCntr TrsmParkLockdTrsmParkLockd;
SIG_GROUP_ 968 VehBattU 1 : VehBattUSysU VehBattUSysUQf;
SIG_GROUP_ 672 VehCfgPrm 1 : VehCfgPrmBlkIDBytePosn1 VehCfgPrmCCPBytePosn2 VehCfgPrmCCPBytePosn3 VehCfgPrmCCPBytePosn4 VehCfgPrmCCPBytePosn5 VehCfgPrmCCPBytePosn6 VehCfgPrmCCPBytePosn7 VehCfgPrmCCPBytePosn8;
SIG_GROUP_ 672 VehCfgPrmExt 1 : VehCfgPrmExtBlkIDBytePosn1 VehCfgPrmExtCCPBytePosn2 VehCfgPrmExtCCPBytePosn3 VehCfgPrmExtCCPBytePosn4 VehCfgPrmExtCCPBytePosn5 VehCfgPrmExtCCPBytePosn6 VehCfgPrmExtCCPBytePosn7 VehCfgPrmExtCCPBytePosn8;
SIG_GROUP_ 832 VehMtnSt 1 : VehMtnStChks VehMtnStCntr VehMtnStVehMtnSt;
SIG_GROUP_ 968 VehSpdAvgIndcd 1 : VehSpdAvgIndcdVehSpdIndcd VehSpdAvgIndcdVeSpdIndcdUnit;
SIG_GROUP_ 968 VehSpdIndcd 1 : VehSpdIndcdVehSpdIndcd VehSpdIndcdVeSpdIndcdUnit;
SIG_GROUP_ 976 VehTiAndData 1 : VehTiAndDataDataValid VehTiAndDataDay VehTiAndDataHr1 VehTiAndDataMins1 VehTiAndDataMth1 VehTiAndDataSec1 VehTiAndDataYr1;
SIG_GROUP_ 672 Vin 1 : VinBlockNr VinVINSignalPos1 VinVINSignalPos2 VinVINSignalPos3 VinVINSignalPos4 VinVINSignalPos5 VinVINSignalPos6 VinVINSignalPos7;
SIG_GROUP_ 968 WhlMotSysTqEst 1 : WhlMotSysTqEstChks WhlMotSysTqEstCntr WhlMotSysTqEstIsgTqAct WhlMotSysTqEstQualityFactor;
